VERSION ""

NS_ :

BS_:

BU_: SGW RFHM MPAD IPC GNMM EVCU2 ESL ECM DTCM DMSM BSM BCM AGSM ADCAM

BO_ 610 ADAS_FD_INFO2: 32 ADCAM
 SG_ TSRSts : 175|2@0+ (1,0) [0|3] "-"  EVCU2,SGW,IPC
 SG_ SignVehicleSpeedLimitConditional : 173|6@0+ (1,0) [0|63] "-"  IPC
 SG_ SignVehicleSpeedLimit : 165|6@0+ (1,0) [0|63] "-"  IPC
 SG_ SignSupplemVehicleSpeedLimit : 183|4@0+ (1,0) [0|15] "-"  IPC
 SG_ SignOvertaking : 155|2@0+ (1,0) [0|3] "-"  IPC
 SG_ AHBFault : 157|1@0+ (1,0) [0|1] ""  SGW,BCM
 SG_ AHB_ON : 158|1@0+ (1,0) [0|1] ""  BCM
 SG_ AHB_Blind : 156|1@0+ (1,0) [0|1] ""  BCM
 SG_ Speed_Sign_Shape : 153|2@0+ (1,0) [0|3] "-"  SGW,IPC
 SG_ SpdUnits_Cam : 159|1@0+ (1,0) [0|1] "-"  IPC
 SG_ SourceFusedSpeedLimit : 167|2@0+ (1,0) [0|3] "-"  IPC
 SG_ HAS_ValidRoad : 147|1@0+ (1,0) [0|1] "-"  Vector__XXX
 SG_ HAS_Status_DALM : 127|4@0+ (1,0) [0|3] "" BCM
 SG_ HAS_OpStat_Prim_DALM : 123|4@0+ (1,0) [0|5] "" BCM
 SG_ DALM_Request : 135|4@0+ (1,0) [0|14] "" BCM
 SG_ CADM_DALM_MC : 131|4@0+ (1,0) [0|15] "-"  BCM
 SG_ CADM_DALM_CRC : 143|8@0+ (1,0) [0|255] "-"  BCM
 SG_ Turn_Lever_Unlatch_Req : 7|2@0+ (1,0) [0|2] "-"  BCM
 SG_ SpeedArrows : 10|2@0+ (1,0) [0|3] "No_Unit"  IPC
 SG_ SignVehicleSpeedLimitPredictive : 23|5@0+ (1,0) [0|31] "No_Unit"  IPC
 SG_ MRRRR_Sts : 39|2@0+ (1,0) [0|2] "" SGW
 SG_ MRRRL_Sts : 25|2@0+ (1,0) [0|2] "" SGW
 SG_ MRRFR_Sts : 27|2@0+ (1,0) [0|2] "" SGW
 SG_ MRRFL_Sts : 29|2@0+ (1,0) [0|2] "" SGW
 SG_ LRRF_Sts : 31|2@0+ (1,0) [0|2] "" SGW
 SG_ LRCF_Sts : 18|2@0+ (1,0) [0|2] "" SGW
 SG_ DistanceSpeedLimitPredictive : 3|9@0+ (10,0) [0|5110] "meter"  IPC
 SG_ MessageCounter_ADAS_FD_INFO2 : 179|4@0+ (1,0) [0|15] "-"  EVCU2,SGW,BCM,IPC
 SG_ CRC_ADAS_FD_INFO2 : 191|8@0+ (1,0) [0|255] "-"  EVCU2,SGW,BCM,IPC
 SG_ DRV_Request : 43|4@0+ (1,0) [0|15] "" IPC
 SG_ Alg_DisplaySts : 146|3@0+ (1,0) [0|7] "" IPC

BO_ 1456 ADAS_FD_HMI: 32 ADCAM
 SG_ RR_Chime_RqSts : 99|1@0+ (1,0) [0|1] "" SGW,BCM
 SG_ MessageCounter_ADAS_FD_HMI : 179|4@0+ (1,0) [0|15] "-"  ADCAM,DMSM,BCM,BSM,IPC
 SG_ LR_Chime_RqSts : 100|1@0+ (1,0) [0|1] "" SGW,BCM
 SG_ CRC_ADAS_FD_HMI : 191|8@0+ (1,0) [0|255] "-"  ADCAM,DMSM,BCM,BSM,IPC
 SG_ Chime_Priority : 91|3@0+ (1,0) [0|4] "-"  SGW,BCM
 SG_ BSS_SRV_RQSts : 88|1@0+ (1,0) [0|1] "" SGW,BCM,IPC
 SG_ BSS_Blind_RQSts : 101|1@0+ (1,0) [0|1] "" SGW,BCM,IPC
 SG_ BSS_CFG_STATSts : 103|2@0+ (1,0) [0|2] "" IPC
 SG_ SVI_Request : 31|2@0+ (1,0) [0|3] "-"  SGW,IPC
 SG_ Set_Speed_MPH : 15|8@0+ (1,0) [0|255] "mph"  SGW,IPC
 SG_ Set_Speed_KPH : 7|8@0+ (1,0) [0|255] "kph"  SGW,IPC
 SG_ RF_Chime_RqSts : 95|1@0+ (1,0) [0|1] "-"  SGW,BCM
 SG_ PEB_Setting_Avail : 78|1@0+ (1,0) [0|1] "-"  Vector__XXX
 SG_ NCC_FailSts : 82|1@0+ (1,0) [0|1] "-"  Vector__XXX
 SG_ LKA_Status : 23|1@0+ (1,0) [0|1] "-"  SGW,IPC
 SG_ LKA_LEDControlSts : 57|2@0+ (1,0) [0|2] "-"  BCM
 SG_ LKA_FailSts : 84|1@0+ (1,0) [0|1] "-"  IPC
 SG_ LKA_Blind : 86|1@0+ (1,0) [0|1] "-"  IPC
 SG_ LF_Chime_RqSts : 93|1@0+ (1,0) [0|1] "-"  SGW,BCM
 SG_ Lane_DisplaySts_Right : 60|3@0+ (1,0) [0|7] "-"  SGW,IPC
 SG_ Lane_DisplaySts_Left : 71|3@0+ (1,0) [0|7] "-"  SGW,IPC
 SG_ ICA_Blind : 55|1@0+ (1,0) [0|1] "-"  IPC
 SG_ HAS_TurnSignalRequest : 111|2@0+ (1,0) [0|2] "" BCM
 SG_ HAS_TelltaleSts : 54|3@0+ (1,0) [0|6] "-"  SGW,IPC
 SG_ HAS_Hazard : 113|1@0+ (1,0) [0|1] "" BCM
 SG_ HAS_FailSts : 80|1@0+ (1,0) [0|1] "-"  IPC
 SG_ HAS_Escalation_Sts : 117|4@0+ (1,0) [0|8] "" Vector__XXX
 SG_ HAS_Blind : 85|1@0+ (1,0) [0|1] "-"  IPC
 SG_ FCW_Setting_Avail : 77|1@0+ (1,0) [0|1] "-"  IPC
 SG_ DMSM_Wakeup : 119|1@0+ (1,0) [0|1] "-"  DMSM
 SG_ DisplaySts_Veh : 63|3@0+ (1,0) [0|7] "-"  SGW,IPC
 SG_ DisplaySts_OFF : 68|3@0+ (1,0) [0|7] "-"  SGW,IPC
 SG_ DisplaySts_Curve : 109|2@0+ (1,0) [0|2] "" IPC
 SG_ DisplaySts_ACC : 51|4@0+ (1,0) [0|15] "-"  SGW,IPC
 SG_ DDD_FailSts : 96|1@0+ (1,0) [0|1] "" IPC
 SG_ DDD_DispPopupSts : 39|2@0+ (1,0) [0|2] "-"  IPC
 SG_ Chime_TypSts : 47|4@0+ (1,0) [0|15] "-"  SGW,BCM
 SG_ Chime_RepRate : 43|4@0+ (1,0) [0|15] "Hz"  SGW,BCM
 SG_ BlindSpotRightWarn : 171|2@0+ (1,0) [0|2] "" BCM
 SG_ BlindSpotLeftWarn : 105|2@0+ (1,0) [0|2] "" BCM
 SG_ AEB_Limited : 72|1@0+ (1,0) [0|1] "-"  IPC
 SG_ AEB_Limit_Fail : 74|1@0+ (1,0) [0|1] "-"  IPC
 SG_ AEB_FailSts : 83|1@0+ (1,0) [0|1] "-"  BSM,IPC
 SG_ AEB_DispPopupSts : 37|6@0+ (1,0) [0|63] "-"  SGW,IPC
 SG_ AEB_Blind : 76|1@0+ (1,0) [0|1] "-"  IPC
 SG_ ACC_Set_Speed_Strike : 92|1@0+ (1,0) [0|1] "-"  SGW,IPC
 SG_ ACC_Limited : 87|1@0+ (1,0) [0|1] "-"  IPC
 SG_ ACC_Limit_Fail : 73|1@0+ (1,0) [0|1] "-"  IPC
 SG_ ACC_FailSts : 81|1@0+ (1,0) [0|1] "-"  BCM,BSM,IPC
 SG_ ACC_DispPopupSts : 22|7@0+ (1,0) [0|127] "-"  SGW,IPC
 SG_ ACC_Blind : 75|1@0+ (1,0) [0|1] "-"  BSM,IPC
 SG_ Driver_Model : 107|2@0+ (1,0) [0|3] "" Vector__XXX
 SG_ RRCC_LEDSts : 25|2@0+ (1,0) [0|2] "-"  Vector__XXX
 SG_ HAS_Inhibit_HMI : 143|6@0+ (1,0) [0|63] "-"  IPC
 SG_ Lane_DispPopupSts : 127|8@0+ (1,0) [0|255] "-"  SGW,IPC
 SG_ RRCC_DispPopupSts : 149|6@0+ (1,0) [0|63] "-"  IPC
 SG_ SVI_Request_ext : 29|3@0+ (1,0) [0|7] "-"  IPC
 SG_ ADASDoorunlock_Request : 132|1@0+ (1,0) [0|1] "-"  BCM
 SG_ HAS_TelltaleSts_ext : 157|3@0+ (1,0) [0|7] "" IPC
 SG_ DisplaySts_Route : 154|3@0+ (1,0) [0|7] "" IPC
 SG_ SLA_Telltale_Sts : 167|2@0+ (1,0) [0|3] "" IPC

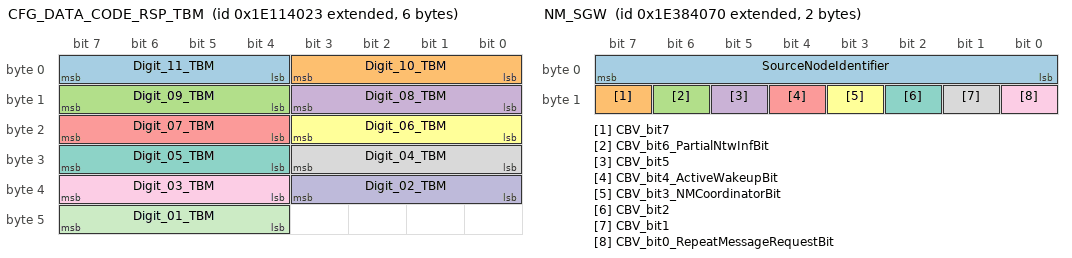
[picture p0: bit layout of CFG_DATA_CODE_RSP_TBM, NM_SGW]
BO_ 2651930659 CFG_DATA_CODE_RSP_TBM: 6 SGW
 SG_ Digit_11_TBM : 7|4@0+ (1,0) [0|15] "-"  BCM
 SG_ Digit_10_TBM : 3|4@0+ (1,0) [0|15] "-"  BCM
 SG_ Digit_09_TBM : 15|4@0+ (1,0) [0|15] "-"  BCM
 SG_ Digit_08_TBM : 11|4@0+ (1,0) [0|15] "-"  BCM
 SG_ Digit_07_TBM : 23|4@0+ (1,0) [0|15] "-"  BCM
 SG_ Digit_06_TBM : 19|4@0+ (1,0) [0|15] "-"  BCM
 SG_ Digit_05_TBM : 31|4@0+ (1,0) [0|15] "-"  BCM
 SG_ Digit_04_TBM : 27|4@0+ (1,0) [0|15] "-"  BCM
 SG_ Digit_03_TBM : 39|4@0+ (1,0) [0|15] "-"  BCM
 SG_ Digit_02_TBM : 35|4@0+ (1,0) [0|15] "-"  BCM
 SG_ Digit_01_TBM : 47|4@0+ (1,0) [0|15] "-"  BCM

BO_ 278 TRANSM_FD_1: 64 EVCU2
 SG_ TRANS_ADAS_Inhibit : 311|1@0+ (1,0) [0|1] "-"  BCM,BSM

BO_ 1452 TBM_SCHEDULE_FD_2: 32 SGW
 SG_ U_Call_Stat_TBM : 143|3@0+ (1,0) [0|7] "-"  BCM
 SG_ E_Call_Stat_TBM : 130|3@0+ (1,0) [0|7] "-"  BCM
 SG_ PrivacyMode : 134|1@0+ (1,0) [0|1] "-"  MPAD
 SG_ WiFiSts : 154|2@0+ (1,0) [0|3] "-"  MPAD
 SG_ SignalStrength : 159|3@0+ (1,0) [0|7] "-"  MPAD
 SG_ NetConnection : 163|2@0+ (1,0) [0|3] "-"  MPAD
 SG_ LTESts : 147|3@0+ (1,0) [0|7] "-"  MPAD
 SG_ MessageCounter_TBMS2 : 179|4@0+ (1,0) [0|15] "-"  MPAD,BCM
 SG_ CRC_TBMS2 : 191|8@0+ (1,0) [0|255] "-"  MPAD,BCM

BO_ 2654486640 NM_SGW: 2 SGW
 SG_ SourceNodeIdentifier : 7|8@0+ (1,0) [0|255] "-"  ADCAM,MPAD,EVCU2,GNMM,AGSM,ESL,BCM,BSM,IPC,RFHM,ECM,DTCM
 SG_ CBV_bit7 : 15|1@0+ (1,0) [0|1] "" ADCAM,MPAD,EVCU2,GNMM,AGSM,ESL,BCM,BSM,IPC,RFHM,ECM,DTCM
 SG_ CBV_bit6_PartialNtwInfBit : 14|1@0+ (1,0) [0|1] "" ADCAM,MPAD,EVCU2,GNMM,AGSM,ESL,BCM,BSM,IPC,RFHM,ECM,DTCM
 SG_ CBV_bit5 : 13|1@0+ (1,0) [0|1] "" ADCAM,MPAD,EVCU2,GNMM,AGSM,ESL,BCM,BSM,IPC,RFHM,ECM,DTCM
 SG_ CBV_bit4_ActiveWakeupBit : 12|1@0+ (1,0) [0|1] "" ADCAM,MPAD,EVCU2,GNMM,AGSM,ESL,BCM,BSM,IPC,RFHM,ECM,DTCM
 SG_ CBV_bit3_NMCoordinatorBit : 11|1@0+ (1,0) [0|1] "" ADCAM,MPAD,EVCU2,GNMM,AGSM,ESL,BCM,BSM,IPC,RFHM,ECM,DTCM
 SG_ CBV_bit2 : 10|1@0+ (1,0) [0|1] "" ADCAM,MPAD,EVCU2,GNMM,AGSM,ESL,BCM,BSM,IPC,RFHM,ECM,DTCM
 SG_ CBV_bit1 : 9|1@0+ (1,0) [0|1] "" ADCAM,MPAD,EVCU2,GNMM,AGSM,ESL,BCM,BSM,IPC,RFHM,ECM,DTCM
 SG_ CBV_bit0_RepeatMessageRequestBit : 8|1@0+ (1,0) [0|1] "" ADCAM,MPAD,EVCU2,GNMM,AGSM,ESL,BCM,BSM,IPC,RFHM,ECM,DTCM

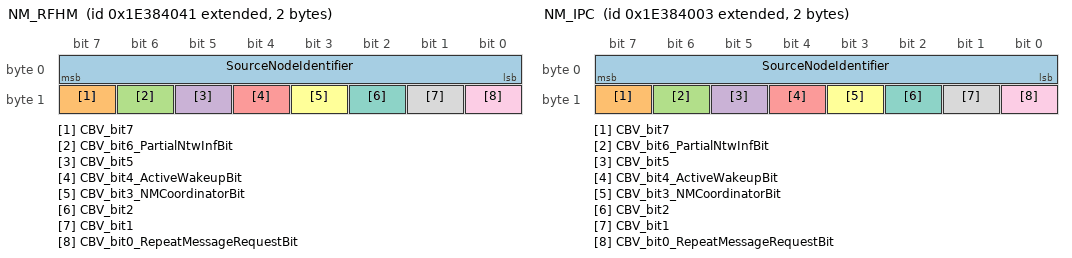
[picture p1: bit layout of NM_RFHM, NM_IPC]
BO_ 2654486593 NM_RFHM: 2 RFHM
 SG_ SourceNodeIdentifier : 7|8@0+ (1,0) [0|255] "-"  ADCAM,MPAD,EVCU2,GNMM,SGW,AGSM,ESL,BCM,BSM,IPC,ECM,DTCM
 SG_ CBV_bit7 : 15|1@0+ (1,0) [0|1] "" ADCAM,MPAD,EVCU2,GNMM,SGW,AGSM,ESL,BCM,BSM,IPC,ECM,DTCM
 SG_ CBV_bit6_PartialNtwInfBit : 14|1@0+ (1,0) [0|1] "" ADCAM,MPAD,EVCU2,GNMM,SGW,AGSM,ESL,BCM,BSM,IPC,ECM,DTCM
 SG_ CBV_bit5 : 13|1@0+ (1,0) [0|1] "" ADCAM,MPAD,EVCU2,GNMM,SGW,AGSM,ESL,BCM,BSM,IPC,ECM,DTCM
 SG_ CBV_bit4_ActiveWakeupBit : 12|1@0+ (1,0) [0|1] "" ADCAM,MPAD,EVCU2,GNMM,SGW,AGSM,ESL,BCM,BSM,IPC,ECM,DTCM
 SG_ CBV_bit3_NMCoordinatorBit : 11|1@0+ (1,0) [0|1] "" ADCAM,MPAD,EVCU2,GNMM,SGW,AGSM,ESL,BCM,BSM,IPC,ECM,DTCM
 SG_ CBV_bit2 : 10|1@0+ (1,0) [0|1] "" ADCAM,MPAD,EVCU2,GNMM,SGW,AGSM,ESL,BCM,BSM,IPC,ECM,DTCM
 SG_ CBV_bit1 : 9|1@0+ (1,0) [0|1] "" ADCAM,MPAD,EVCU2,GNMM,SGW,AGSM,ESL,BCM,BSM,IPC,ECM,DTCM
 SG_ CBV_bit0_RepeatMessageRequestBit : 8|1@0+ (1,0) [0|1] "" ADCAM,MPAD,EVCU2,GNMM,SGW,AGSM,ESL,BCM,BSM,IPC,ECM,DTCM

BO_ 2654486531 NM_IPC: 2 IPC
 SG_ SourceNodeIdentifier : 7|8@0+ (1,0) [0|255] "-"  ADCAM,MPAD,EVCU2,GNMM,SGW,AGSM,ESL,BCM,BSM,RFHM,ECM,DTCM
 SG_ CBV_bit7 : 15|1@0+ (1,0) [0|1] "" ADCAM,MPAD,EVCU2,GNMM,SGW,AGSM,ESL,BCM,BSM,RFHM,ECM,DTCM
 SG_ CBV_bit6_PartialNtwInfBit : 14|1@0+ (1,0) [0|1] "" ADCAM,MPAD,EVCU2,GNMM,SGW,AGSM,ESL,BCM,BSM,RFHM,ECM,DTCM
 SG_ CBV_bit5 : 13|1@0+ (1,0) [0|1] "" ADCAM,MPAD,EVCU2,GNMM,SGW,AGSM,ESL,BCM,BSM,RFHM,ECM,DTCM
 SG_ CBV_bit4_ActiveWakeupBit : 12|1@0+ (1,0) [0|1] "" ADCAM,MPAD,EVCU2,GNMM,SGW,AGSM,ESL,BCM,BSM,RFHM,ECM,DTCM
 SG_ CBV_bit3_NMCoordinatorBit : 11|1@0+ (1,0) [0|1] "" ADCAM,MPAD,EVCU2,GNMM,SGW,AGSM,ESL,BCM,BSM,RFHM,ECM,DTCM
 SG_ CBV_bit2 : 10|1@0+ (1,0) [0|1] "" ADCAM,MPAD,EVCU2,GNMM,SGW,AGSM,ESL,BCM,BSM,RFHM,ECM,DTCM
 SG_ CBV_bit1 : 9|1@0+ (1,0) [0|1] "" ADCAM,MPAD,EVCU2,GNMM,SGW,AGSM,ESL,BCM,BSM,RFHM,ECM,DTCM
 SG_ CBV_bit0_RepeatMessageRequestBit : 8|1@0+ (1,0) [0|1] "" ADCAM,MPAD,EVCU2,GNMM,SGW,AGSM,ESL,BCM,BSM,RFHM,ECM,DTCM

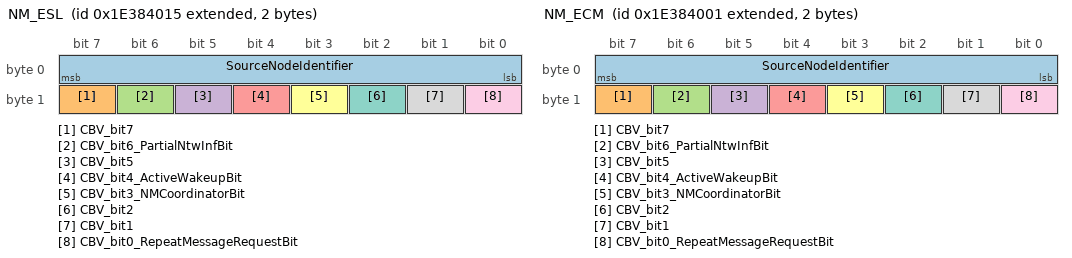
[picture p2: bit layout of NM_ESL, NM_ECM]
BO_ 2654486549 NM_ESL: 2 ESL
 SG_ SourceNodeIdentifier : 7|8@0+ (1,0) [0|255] "-"  ADCAM,MPAD,EVCU2,GNMM,SGW,AGSM,BCM,BSM,IPC,RFHM,ECM,DTCM
 SG_ CBV_bit7 : 15|1@0+ (1,0) [0|1] "" ADCAM,MPAD,EVCU2,GNMM,SGW,AGSM,BCM,BSM,IPC,RFHM,ECM,DTCM
 SG_ CBV_bit6_PartialNtwInfBit : 14|1@0+ (1,0) [0|1] "" ADCAM,MPAD,EVCU2,GNMM,SGW,AGSM,BCM,BSM,IPC,RFHM,ECM,DTCM
 SG_ CBV_bit5 : 13|1@0+ (1,0) [0|1] "" ADCAM,MPAD,EVCU2,GNMM,SGW,AGSM,BCM,BSM,IPC,RFHM,ECM,DTCM
 SG_ CBV_bit4_ActiveWakeupBit : 12|1@0+ (1,0) [0|1] "" ADCAM,MPAD,EVCU2,GNMM,SGW,AGSM,BCM,BSM,IPC,RFHM,ECM,DTCM
 SG_ CBV_bit3_NMCoordinatorBit : 11|1@0+ (1,0) [0|1] "" ADCAM,MPAD,EVCU2,GNMM,SGW,AGSM,BCM,BSM,IPC,RFHM,ECM,DTCM
 SG_ CBV_bit2 : 10|1@0+ (1,0) [0|1] "" ADCAM,MPAD,EVCU2,GNMM,SGW,AGSM,BCM,BSM,IPC,RFHM,ECM,DTCM
 SG_ CBV_bit1 : 9|1@0+ (1,0) [0|1] "" ADCAM,MPAD,EVCU2,GNMM,SGW,AGSM,BCM,BSM,IPC,RFHM,ECM,DTCM
 SG_ CBV_bit0_RepeatMessageRequestBit : 8|1@0+ (1,0) [0|1] "" ADCAM,MPAD,EVCU2,GNMM,SGW,AGSM,BCM,BSM,IPC,RFHM,ECM,DTCM

BO_ 2654486529 NM_ECM: 2 ECM
 SG_ SourceNodeIdentifier : 7|8@0+ (1,0) [0|255] "-"  ADCAM,MPAD,EVCU2,GNMM,SGW,AGSM,ESL,BCM,BSM,IPC,RFHM,DTCM
 SG_ CBV_bit7 : 15|1@0+ (1,0) [0|1] "" ADCAM,MPAD,EVCU2,GNMM,SGW,AGSM,ESL,BCM,BSM,IPC,RFHM,DTCM
 SG_ CBV_bit6_PartialNtwInfBit : 14|1@0+ (1,0) [0|1] "" ADCAM,MPAD,EVCU2,GNMM,SGW,AGSM,ESL,BCM,BSM,IPC,RFHM,DTCM
 SG_ CBV_bit5 : 13|1@0+ (1,0) [0|1] "" ADCAM,MPAD,EVCU2,GNMM,SGW,AGSM,ESL,BCM,BSM,IPC,RFHM,DTCM
 SG_ CBV_bit4_ActiveWakeupBit : 12|1@0+ (1,0) [0|1] "" ADCAM,MPAD,EVCU2,GNMM,SGW,AGSM,ESL,BCM,BSM,IPC,RFHM,DTCM
 SG_ CBV_bit3_NMCoordinatorBit : 11|1@0+ (1,0) [0|1] "" ADCAM,MPAD,EVCU2,GNMM,SGW,AGSM,ESL,BCM,BSM,IPC,RFHM,DTCM
 SG_ CBV_bit2 : 10|1@0+ (1,0) [0|1] "" ADCAM,MPAD,EVCU2,GNMM,SGW,AGSM,ESL,BCM,BSM,IPC,RFHM,DTCM
 SG_ CBV_bit1 : 9|1@0+ (1,0) [0|1] "" ADCAM,MPAD,EVCU2,GNMM,SGW,AGSM,ESL,BCM,BSM,IPC,RFHM,DTCM
 SG_ CBV_bit0_RepeatMessageRequestBit : 8|1@0+ (1,0) [0|1] "" ADCAM,MPAD,EVCU2,GNMM,SGW,AGSM,ESL,BCM,BSM,IPC,RFHM,DTCM

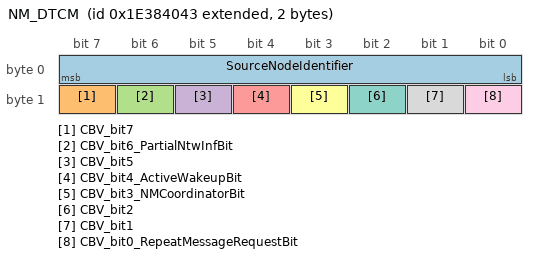
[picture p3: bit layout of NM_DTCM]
BO_ 2654486595 NM_DTCM: 2 DTCM
 SG_ SourceNodeIdentifier : 7|8@0+ (1,0) [0|255] "-"  ADCAM,MPAD,EVCU2,GNMM,SGW,AGSM,ESL,BCM,BSM,IPC,RFHM,ECM
 SG_ CBV_bit7 : 15|1@0+ (1,0) [0|1] "" ADCAM,MPAD,EVCU2,GNMM,SGW,AGSM,ESL,BCM,BSM,IPC,RFHM,ECM
 SG_ CBV_bit6_PartialNtwInfBit : 14|1@0+ (1,0) [0|1] "" ADCAM,MPAD,EVCU2,GNMM,SGW,AGSM,ESL,BCM,BSM,IPC,RFHM,ECM
 SG_ CBV_bit5 : 13|1@0+ (1,0) [0|1] "" ADCAM,MPAD,EVCU2,GNMM,SGW,AGSM,ESL,BCM,BSM,IPC,RFHM,ECM
 SG_ CBV_bit4_ActiveWakeupBit : 12|1@0+ (1,0) [0|1] "" ADCAM,MPAD,EVCU2,GNMM,SGW,AGSM,ESL,BCM,BSM,IPC,RFHM,ECM
 SG_ CBV_bit3_NMCoordinatorBit : 11|1@0+ (1,0) [0|1] "" ADCAM,MPAD,EVCU2,GNMM,SGW,AGSM,ESL,BCM,BSM,IPC,RFHM,ECM
 SG_ CBV_bit2 : 10|1@0+ (1,0) [0|1] "" ADCAM,MPAD,EVCU2,GNMM,SGW,AGSM,ESL,BCM,BSM,IPC,RFHM,ECM
 SG_ CBV_bit1 : 9|1@0+ (1,0) [0|1] "" ADCAM,MPAD,EVCU2,GNMM,SGW,AGSM,ESL,BCM,BSM,IPC,RFHM,ECM
 SG_ CBV_bit0_RepeatMessageRequestBit : 8|1@0+ (1,0) [0|1] "" ADCAM,MPAD,EVCU2,GNMM,SGW,AGSM,ESL,BCM,BSM,IPC,RFHM,ECM

BO_TX_BU_ 610 : ADCAM,MPAD;
BO_TX_BU_ 1456 : ADCAM,MPAD;
CM_ SG_ 610 CADM_DALM_MC "This signal is a counter used for safety checks strategies. This counter is incremented of 1 (one) unit at each frame transmission.";
CM_ SG_ 610 MRRRL_Sts "Mid Range Radar Rear Left Sensor Status";
CM_ SG_ 610 MRRRR_Sts "Mid Range Radar Rear Right Sensor Status";
CM_ SG_ 610 SignOvertaking "This signal indicates the road sign of no overtaking";
CM_ SG_ 610 SignSupplemVehicleSpeedLimit "This signal indicates the supplementary road sign  related to vehicle speed limit";
CM_ SG_ 610 SignVehicleSpeedLimit "This signal indicates the road sign of vehicle speed limit";
CM_ SG_ 610 SignVehicleSpeedLimitConditional "This signal indicates the conditional road sign of vehicle speed limit";
CM_ SG_ 610 SignVehicleSpeedLimitPredictive "This signal indicates the predictive vehicle sign speed limit.";
CM_ SG_ 610 SourceFusedSpeedLimit "Source of the fused speed limit data";
CM_ SG_ 610 HAS_OpStat_Prim_DALM "Capability of the primary controller to perform sensing, computing, and actuation";
CM_ SG_ 610 HAS_Status_DALM "Highway Assist System Status as reported by the main controller";
CM_ SG_ 610 HAS_ValidRoad "HAS Ready";
CM_ SG_ 610 LRCF_Sts "Long Range Camera Front Sensor Status";
CM_ SG_ 610 MRRFL_Sts "Mid Range Radar Front Left Sensor Status";
CM_ SG_ 610 MRRFR_Sts "Mid Range Radar Front Right Sensor Status";
CM_ SG_ 610 MessageCounter_ADAS_FD_INFO2 "This signal is a counter used for safety checks strategies. This counter is incremented of 1 (one) unit at each frame transmission.";
CM_ SG_ 610 LRRF_Sts "Long Range Radar Front Sensor Status";
CM_ SG_ 610 SpeedArrows "Arrow to indicate speed limit variation.";
CM_ SG_ 610 AHB_Blind "This signal indicates the AHB Controller state";
CM_ SG_ 610 AHB_ON "AHB Controller tells to the BCM to turn ON/OFF the high beam lamps";
CM_ SG_ 610 AHBFault "AHB Controller sends to the BCM the fault condition";
CM_ SG_ 610 Alg_DisplaySts "'Alg_DisplaySts.TEXT MSG n corresponds to a raw value of 'n'";
CM_ SG_ 610 CADM_DALM_CRC "CRC according to SAE J1850 standard at each frame transmission.";
CM_ SG_ 610 CRC_ADAS_FD_INFO2 "CRC according to SAE J1850 standard at each frame transmission.";
CM_ SG_ 610 DALM_Request "Request to driver alert lighting modules to trigger patttern and color display from primary controller";
CM_ SG_ 610 DistanceSpeedLimitPredictive "Distance to next speed limit (predictive speed limit).";
CM_ SG_ 610 DRV_Request "DRV_Request.TEXT MSG n corresponds to a raw value of 'n";
CM_ SG_ 610 SpdUnits_Cam "Speed Units";
CM_ SG_ 610 Speed_Sign_Shape "Shape of Speed Sign";
CM_ SG_ 610 TSRSts "This signal indicates the Traffic Sign Recognition status";
CM_ SG_ 610 Turn_Lever_Unlatch_Req "L2+ turn stalk unlatch request";
CM_ SG_ 1456 Lane_DispPopupSts "Lane Management Pop-up Messages.TEXT MSG n corresponds to a raw value of 'n'";
CM_ SG_ 1456 LF_Chime_RqSts "DASM_LF_Chime_RqSts";
CM_ SG_ 1456 LKA_Blind "LKA_Blind";
CM_ SG_ 1456 LKA_FailSts "LKA_FailSts";
CM_ SG_ 1456 Lane_DisplaySts_Left "Lane Display Status Left";
CM_ SG_ 1456 Lane_DisplaySts_Right "Lane Display Status Right";
CM_ SG_ 1456 ICA_Blind "This signal is used to indicate the presence of an occlusion of the ICA feature";
CM_ SG_ 1456 HAS_TurnSignalRequest "Request from the primary controller to actuate the turn signals";
CM_ SG_ 1456 NCC_FailSts "NCC_FailSts";
CM_ SG_ 1456 PEB_Setting_Avail "PEB setting availability";
CM_ SG_ 1456 RF_Chime_RqSts "DASM_RF_Chime_RqSts";
CM_ SG_ 1456 RR_Chime_RqSts "BSM right rear chime on request";
CM_ SG_ 1456 LKA_LEDControlSts "Lane Keep LED Control Status";
CM_ SG_ 1456 LKA_Status "None";
CM_ SG_ 1456 LR_Chime_RqSts "BSM Left rear chime on request";
CM_ SG_ 1456 MessageCounter_ADAS_FD_HMI "This signal is a counter used for safety checks strategies. This counter is incremented of 1 (one) unit at each frame transmission.";
CM_ SG_ 1456 SLA_Telltale_Sts "'SLA_Telltale_Sts.TEXT MSG n corresponds to a raw value of 'n'";
CM_ SG_ 1456 SVI_Request "Request to activate Secondary Visual Indication";
CM_ SG_ 1456 SVI_Request_ext "Cluster Glow";
CM_ SG_ 1456 ACC_Blind "ACC_Blind";
CM_ SG_ 1456 ACC_DispPopupSts "ACC Dips Pop Up";
CM_ SG_ 1456 ACC_FailSts "ACC_FailSts";
CM_ SG_ 1456 BSS_Blind_RQSts "Sensor blinded request from BSS";
CM_ SG_ 1456 ACC_Limit_Fail "ACC_Limit_Fail";
CM_ SG_ 1456 ACC_Limited "ACC_Limited";
CM_ SG_ 1456 ACC_Set_Speed_Strike "ACC Set Speed Strike";
CM_ SG_ 1456 ADASDoorunlock_Request "Request from Primary MPAD to unlock all the doors";
CM_ SG_ 1456 AEB_Blind "AEB_Blind";
CM_ SG_ 1456 AEB_DispPopupSts "AEB Dips Pop Up";
CM_ SG_ 1456 AEB_FailSts "AEB_FailSts";
CM_ SG_ 1456 AEB_Limit_Fail "AEB_Limit_Fail";
CM_ SG_ 1456 AEB_Limited "AEB_Limited";
CM_ SG_ 1456 BlindSpotLeftWarn "BlindSpotLeftWarn";
CM_ SG_ 1456 BlindSpotRightWarn "BlindSpotRightWarn";
CM_ SG_ 1456 BSS_CFG_STATSts "Blind Spot configuration status";
CM_ SG_ 1456 BSS_SRV_RQSts "BSS service warning request";
CM_ SG_ 1456 CRC_ADAS_FD_HMI "CRC according to SAE J1850 standard at each frame transmission.";
CM_ SG_ 1456 Chime_Priority "Chime Priority";
CM_ SG_ 1456 Chime_RepRate "DASM Chime Repetition Rate";
CM_ SG_ 1456 Chime_TypSts "DASM Chime Type Status";
CM_ SG_ 1456 DDD_DispPopupSts "DDD Disp Pop Up";
CM_ SG_ 1456 DDD_FailSts "DDD Fail Sts CADM2";
CM_ SG_ 1456 DisplaySts_ACC "Display status ACC";
CM_ SG_ 1456 DisplaySts_Curve "Indication that Curve Speed Control is reducing vehicle target speed in response to tight curve";
CM_ SG_ 1456 DisplaySts_OFF "Display Status Off";
CM_ SG_ 1456 DisplaySts_Route "'DisplaySts_Route.TEXT MSG n corresponds to a raw value of 'n'";
CM_ SG_ 1456 DisplaySts_Veh "Display Status Veh";
CM_ SG_ 1456 DMSM_Wakeup "To trigger driver monitoring camera and IR LED to turn on";
CM_ SG_ 1456 Driver_Model "Overall assessment of whether driver is attentive to the driving task according to driver model";
CM_ SG_ 1456 FCW_Setting_Avail "FCW setting availability";
CM_ SG_ 1456 HAS_Blind "HAS_Blind";
CM_ SG_ 1456 HAS_Escalation_Sts "HAS_Escalation_Sts";
CM_ SG_ 1456 HAS_FailSts "HAS_FailSts";
CM_ SG_ 1456 HAS_Hazard "Request from the primary controller to actuate the Hazard lamps.";
CM_ SG_ 1456 HAS_Inhibit_HMI "L2+ inhibiting reason message";
CM_ SG_ 1456 HAS_TelltaleSts "Highway Assist telltale status in cluster";
CM_ SG_ 1456 HAS_TelltaleSts_ext "'HAS_TelltaleSts_ext .TEXT MSG n corresponds to a raw value of 'n'";
CM_ SG_ 1456 RRCC_DispPopupSts "RRCC_DispPopupSts";
CM_ SG_ 1456 RRCC_LEDSts "RRCC_LEDSts";
CM_ SG_ 1456 Set_Speed_KPH "Speed shown by IPC, which ACC is controlling in KPH";
CM_ SG_ 1456 Set_Speed_MPH "Speed shown by IPC, which ACC is controlling in MPH";
CM_ SG_ 278 TRANS_ADAS_Inhibit "TCM's ability to accept external gear shift requests";
CM_ SG_ 1452 LTESts "It is used to show the cell network level";
CM_ SG_ 1452 E_Call_Stat_TBM "E-Call Status";
CM_ SG_ 1452 CRC_TBMS2 "CRC according to SAE J1850 standard at each frame transmission.";
CM_ SG_ 1452 MessageCounter_TBMS2 "This signal is a counter used for safety checks strategies. This counter is incremented of 1 (one) unit at each frame transmission.";
CM_ SG_ 1452 PrivacyMode "It is used to give information about  the Privacy Mode functionality.";
CM_ SG_ 1452 NetConnection "It is used to estimate data connection";
CM_ SG_ 1452 WiFiSts "It indicates the status of the WiFi modem";
CM_ SG_ 1452 U_Call_Stat_TBM "U-Call Status";
CM_ SG_ 1452 SignalStrength "It is used to show the cell signal strength";
CM_ SG_ 2654486640 CBV_bit0_RepeatMessageRequestBit "Repeat Message Request Bit";
CM_ SG_ 2654486640 CBV_bit3_NMCoordinatorBit "NM Coordinator Sleep Bit";
CM_ SG_ 2654486640 CBV_bit4_ActiveWakeupBit "Active Wakeup Bit";
CM_ SG_ 2654486640 CBV_bit6_PartialNtwInfBit "Partial Network Information Bit (PNI)";
CM_ SG_ 2654486640 SourceNodeIdentifier "Source Node Identifier";
CM_ SG_ 2654486593 CBV_bit0_RepeatMessageRequestBit "Repeat Message Request Bit";
CM_ SG_ 2654486593 CBV_bit3_NMCoordinatorBit "NM Coordinator Sleep Bit";
CM_ SG_ 2654486593 CBV_bit4_ActiveWakeupBit "Active Wakeup Bit";
CM_ SG_ 2654486593 CBV_bit6_PartialNtwInfBit "Partial Network Information Bit (PNI)";
CM_ SG_ 2654486593 SourceNodeIdentifier "Source Node Identifier";
CM_ SG_ 2654486531 CBV_bit0_RepeatMessageRequestBit "Repeat Message Request Bit";
CM_ SG_ 2654486531 CBV_bit3_NMCoordinatorBit "NM Coordinator Sleep Bit";
CM_ SG_ 2654486531 CBV_bit4_ActiveWakeupBit "Active Wakeup Bit";
CM_ SG_ 2654486531 CBV_bit6_PartialNtwInfBit "Partial Network Information Bit (PNI)";
CM_ SG_ 2654486531 SourceNodeIdentifier "Source Node Identifier";
CM_ SG_ 2654486549 CBV_bit0_RepeatMessageRequestBit "Repeat Message Request Bit";
CM_ SG_ 2654486549 CBV_bit3_NMCoordinatorBit "NM Coordinator Sleep Bit";
CM_ SG_ 2654486549 CBV_bit4_ActiveWakeupBit "Active Wakeup Bit";
CM_ SG_ 2654486549 CBV_bit6_PartialNtwInfBit "Partial Network Information Bit (PNI)";
CM_ SG_ 2654486549 SourceNodeIdentifier "Source Node Identifier";
CM_ SG_ 2654486529 CBV_bit3_NMCoordinatorBit "NM Coordinator Sleep Bit";
CM_ SG_ 2654486529 CBV_bit4_ActiveWakeupBit "Active Wakeup Bit";
CM_ SG_ 2654486529 CBV_bit6_PartialNtwInfBit "Partial Network Information Bit (PNI)";
CM_ SG_ 2654486529 SourceNodeIdentifier "Source Node Identifier";
CM_ SG_ 2654486529 CBV_bit0_RepeatMessageRequestBit "Repeat Message Request Bit";
CM_ SG_ 2654486595 SourceNodeIdentifier "Source Node Identifier";
CM_ SG_ 2654486595 CBV_bit0_RepeatMessageRequestBit "Repeat Message Request Bit";
CM_ SG_ 2654486595 CBV_bit3_NMCoordinatorBit "NM Coordinator Sleep Bit";
CM_ SG_ 2654486595 CBV_bit4_ActiveWakeupBit "Active Wakeup Bit";
CM_ SG_ 2654486595 CBV_bit6_PartialNtwInfBit "Partial Network Information Bit (PNI)";
BA_DEF_ BO_ "CANFD_BRS" ENUM "0","1";
BA_DEF_ BO_ "VFrameFormat" ENUM "StandardCAN","ExtendedCAN","reserved","reserved","reserved","reserved","reserved","reserved","reserved","reserved","reserved","reserved","reserved","reserved","StandardCAN_FD","ExtendedCAN_FD";
BA_DEF_ BO_ "DiagConnection" HEX 0 65535;
BA_DEF_ BO_ "DiagState" ENUM "No","Yes";
BA_DEF_ BO_ "NmAsrMessage" ENUM "No","Yes";
BA_DEF_ BO_ "GenMsgDelayTime" INT 0 65535;
BA_DEF_ BO_ "GenMsgCycleTime" INT 0 65535;
BA_DEF_ BO_ "GenMsgCycleTimeFast" INT 0 65535;
BA_DEF_ BO_ "GenMsgStartDelayTime" INT 0 65535;
BA_DEF_ BO_ "GenMsgILSupport" ENUM "No","Yes";
BA_DEF_ BO_ "GenMsgNrOfRepetition" INT 0 255;
BA_DEF_ BO_ "GenMsgSendType" ENUM "Cyclic","NotUsed","NotUsed","NotUsed","NotUsed","NotUsed","NotUsed","NotUsed","NoMsgSendType";
BA_DEF_ BO_ "NmMessage" ENUM "No","Yes";
BA_DEF_ BO_ "DiagResponse" ENUM "No","Yes";
BA_DEF_ BO_ "Type" ENUM "P","C","PE","COC","PE_Cntrl","E","E_Cntrl","OC","S","BAF","DC","EM","MM","ISO-TP","-";
BA_DEF_ BO_ "DiagRequest" ENUM "No","Yes";
BA_DEF_ SG_ "GenSigTimeoutTime_SGW" INT 0 65535;
BA_DEF_ SG_ "GenSigTimeoutTime_RFHM" INT 0 65535;
BA_DEF_ SG_ "GenSigTimeoutTime_MPAD" INT 0 65535;
BA_DEF_ SG_ "GenSigTimeoutTime_IPC" INT 0 65535;
BA_DEF_ SG_ "GenSigTimeoutTime_GNMM" INT 0 65535;
BA_DEF_ SG_ "GenSigTimeoutTime_EVCU2" INT 0 65535;
BA_DEF_ SG_ "GenSigTimeoutTime_ESL" INT 0 65535;
BA_DEF_ SG_ "GenSigTimeoutTime_ECM" INT 0 65535;
BA_DEF_ SG_ "GenSigTimeoutTime_DTCM" INT 0 65535;
BA_DEF_ SG_ "GenSigTimeoutTime_DMSM" INT 0 65535;
BA_DEF_ SG_ "GenSigTimeoutTime_BSM" INT 0 65535;
BA_DEF_ SG_ "GenSigTimeoutTime_BCM" INT 0 65535;
BA_DEF_ SG_ "GenSigTimeoutTime_AGSM" INT 0 65535;
BA_DEF_ SG_ "GenSigTimeoutTime_ADCAM" INT 0 65535;
BA_DEF_ SG_ "SystemSignalLongSymbol" STRING ;
BA_DEF_ SG_ "GenSigSendType" ENUM "NotUsed","OnWrite","OnWriteWithRepetition","OnChange","OnChangeWithRepetition","IfActive","IfActiveWithRepetition","NoSigSendType";
BA_DEF_ SG_ "GenSigInactiveValue" INT 0 2147483647;
BA_DEF_ SG_ "GenSigStartValue" INT 0 2147483647;
BA_DEF_DEF_ "CANFD_BRS" "0";
BA_DEF_DEF_ "VFrameFormat" "StandardCAN_FD";
BA_DEF_DEF_ "DiagConnection" 0;
BA_DEF_DEF_ "DiagState" "No";
BA_DEF_DEF_ "NmAsrMessage" "No";
BA_DEF_DEF_ "GenMsgDelayTime" 0;
BA_DEF_DEF_ "GenMsgCycleTime" 0;
BA_DEF_DEF_ "GenMsgCycleTimeFast" 0;
BA_DEF_DEF_ "GenMsgStartDelayTime" 0;
BA_DEF_DEF_ "GenMsgILSupport" "No";
BA_DEF_DEF_ "GenMsgNrOfRepetition" 0;
BA_DEF_DEF_ "GenMsgSendType" "NoMsgSendType";
BA_DEF_DEF_ "NmMessage" "No";
BA_DEF_DEF_ "DiagResponse" "No";
BA_DEF_DEF_ "Type" "-";
BA_DEF_DEF_ "DiagRequest" "No";
BA_DEF_DEF_ "GenSigTimeoutTime_SGW" 2500;
BA_DEF_DEF_ "GenSigTimeoutTime_RFHM" 2500;
BA_DEF_DEF_ "GenSigTimeoutTime_MPAD" 2500;
BA_DEF_DEF_ "GenSigTimeoutTime_IPC" 2500;
BA_DEF_DEF_ "GenSigTimeoutTime_GNMM" 2500;
BA_DEF_DEF_ "GenSigTimeoutTime_EVCU2" 2500;
BA_DEF_DEF_ "GenSigTimeoutTime_ESL" 2500;
BA_DEF_DEF_ "GenSigTimeoutTime_ECM" 2500;
BA_DEF_DEF_ "GenSigTimeoutTime_DTCM" 2500;
BA_DEF_DEF_ "GenSigTimeoutTime_DMSM" 2500;
BA_DEF_DEF_ "GenSigTimeoutTime_BSM" 2500;
BA_DEF_DEF_ "GenSigTimeoutTime_BCM" 2500;
BA_DEF_DEF_ "GenSigTimeoutTime_AGSM" 2500;
BA_DEF_DEF_ "GenSigTimeoutTime_ADCAM" 2500;
BA_DEF_DEF_ "SystemSignalLongSymbol" "";
BA_DEF_DEF_ "GenSigSendType" "NoSigSendType";
BA_DEF_DEF_ "GenSigInactiveValue" 0;
BA_DEF_DEF_ "GenSigStartValue" 0;
BA_ "CANFD_BRS" BO_ 610 1;
BA_ "GenMsgDelayTime" BO_ 610 20;
BA_ "GenMsgCycleTime" BO_ 610 100;
BA_ "GenMsgCycleTimeFast" BO_ 610 20;
BA_ "GenMsgILSupport" BO_ 610 1;
BA_ "GenMsgNrOfRepetition" BO_ 610 2;
BA_ "GenMsgSendType" BO_ 610 0;
BA_ "Type" BO_ 610 3;
BA_ "CANFD_BRS" BO_ 1456 1;
BA_ "GenMsgDelayTime" BO_ 1456 20;
BA_ "GenMsgCycleTime" BO_ 1456 100;
BA_ "GenMsgILSupport" BO_ 1456 1;
BA_ "GenMsgSendType" BO_ 1456 0;
BA_ "Type" BO_ 1456 3;
BA_ "CANFD_BRS" BO_ 2651930659 1;
BA_ "VFrameFormat" BO_ 2651930659 15;
BA_ "GenMsgILSupport" BO_ 2651930659 1;
BA_ "Type" BO_ 2651930659 11;
BA_ "CANFD_BRS" BO_ 278 1;
BA_ "GenMsgCycleTime" BO_ 278 10;
BA_ "GenMsgStartDelayTime" BO_ 278 5;
BA_ "GenMsgILSupport" BO_ 278 1;
BA_ "GenMsgSendType" BO_ 278 0;
BA_ "Type" BO_ 278 1;
BA_ "CANFD_BRS" BO_ 1452 1;
BA_ "GenMsgCycleTime" BO_ 1452 1000;
BA_ "GenMsgILSupport" BO_ 1452 1;
BA_ "GenMsgSendType" BO_ 1452 0;
BA_ "Type" BO_ 1452 3;
BA_ "CANFD_BRS" BO_ 2654486640 1;
BA_ "VFrameFormat" BO_ 2654486640 15;
BA_ "NmAsrMessage" BO_ 2654486640 1;
BA_ "NmMessage" BO_ 2654486640 1;
BA_ "Type" BO_ 2654486640 8;
BA_ "CANFD_BRS" BO_ 2654486593 1;
BA_ "VFrameFormat" BO_ 2654486593 15;
BA_ "NmAsrMessage" BO_ 2654486593 1;
BA_ "NmMessage" BO_ 2654486593 1;
BA_ "Type" BO_ 2654486593 8;
BA_ "CANFD_BRS" BO_ 2654486531 1;
BA_ "VFrameFormat" BO_ 2654486531 15;
BA_ "NmAsrMessage" BO_ 2654486531 1;
BA_ "NmMessage" BO_ 2654486531 1;
BA_ "Type" BO_ 2654486531 8;
BA_ "CANFD_BRS" BO_ 2654486549 1;
BA_ "VFrameFormat" BO_ 2654486549 15;
BA_ "NmAsrMessage" BO_ 2654486549 1;
BA_ "NmMessage" BO_ 2654486549 1;
BA_ "Type" BO_ 2654486549 8;
BA_ "CANFD_BRS" BO_ 2654486529 1;
BA_ "VFrameFormat" BO_ 2654486529 15;
BA_ "NmAsrMessage" BO_ 2654486529 1;
BA_ "NmMessage" BO_ 2654486529 1;
BA_ "Type" BO_ 2654486529 8;
BA_ "CANFD_BRS" BO_ 2654486595 1;
BA_ "VFrameFormat" BO_ 2654486595 15;
BA_ "NmAsrMessage" BO_ 2654486595 1;
BA_ "NmMessage" BO_ 2654486595 1;
BA_ "Type" BO_ 2654486595 8;
BA_ "GenSigTimeoutTime_SGW" SG_ 2654486531 CBV_bit2 0;
BA_ "GenSigTimeoutTime_RFHM" SG_ 2654486531 CBV_bit2 0;
BA_ "GenSigTimeoutTime_MPAD" SG_ 2654486531 CBV_bit2 0;
BA_ "GenSigTimeoutTime_IPC" SG_ 2654486531 CBV_bit2 0;
BA_ "GenSigTimeoutTime_GNMM" SG_ 2654486531 CBV_bit2 0;
BA_ "GenSigTimeoutTime_EVCU2" SG_ 2654486531 CBV_bit2 0;
BA_ "GenSigTimeoutTime_ESL" SG_ 2654486531 CBV_bit2 0;
BA_ "GenSigTimeoutTime_ECM" SG_ 2654486531 CBV_bit2 0;
BA_ "GenSigTimeoutTime_DTCM" SG_ 2654486531 CBV_bit2 0;
BA_ "GenSigTimeoutTime_DMSM" SG_ 2654486531 CBV_bit2 0;
BA_ "GenSigTimeoutTime_BSM" SG_ 2654486531 CBV_bit2 0;
BA_ "GenSigTimeoutTime_BCM" SG_ 2654486531 CBV_bit2 0;
BA_ "GenSigTimeoutTime_AGSM" SG_ 2654486531 CBV_bit2 0;
BA_ "GenSigTimeoutTime_ADCAM" SG_ 2654486531 CBV_bit2 0;
BA_ "GenSigTimeoutTime_SGW" SG_ 2654486549 CBV_bit2 0;
BA_ "GenSigTimeoutTime_RFHM" SG_ 2654486549 CBV_bit2 0;
BA_ "GenSigTimeoutTime_MPAD" SG_ 2654486549 CBV_bit2 0;
BA_ "GenSigTimeoutTime_IPC" SG_ 2654486549 CBV_bit2 0;
BA_ "GenSigTimeoutTime_GNMM" SG_ 2654486549 CBV_bit2 0;
BA_ "GenSigTimeoutTime_EVCU2" SG_ 2654486549 CBV_bit2 0;
BA_ "GenSigTimeoutTime_ESL" SG_ 2654486549 CBV_bit2 0;
BA_ "GenSigTimeoutTime_ECM" SG_ 2654486549 CBV_bit2 0;
BA_ "GenSigTimeoutTime_DTCM" SG_ 2654486549 CBV_bit2 0;
BA_ "GenSigTimeoutTime_DMSM" SG_ 2654486549 CBV_bit2 0;
BA_ "GenSigTimeoutTime_BSM" SG_ 2654486549 CBV_bit2 0;
BA_ "GenSigTimeoutTime_BCM" SG_ 2654486549 CBV_bit2 0;
BA_ "GenSigTimeoutTime_AGSM" SG_ 2654486549 CBV_bit2 0;
BA_ "GenSigTimeoutTime_ADCAM" SG_ 2654486549 CBV_bit2 0;
BA_ "GenSigTimeoutTime_SGW" SG_ 2654486549 CBV_bit3_NMCoordinatorBit 0;
BA_ "GenSigTimeoutTime_RFHM" SG_ 2654486549 CBV_bit3_NMCoordinatorBit 0;
BA_ "GenSigTimeoutTime_MPAD" SG_ 2654486549 CBV_bit3_NMCoordinatorBit 0;
BA_ "GenSigTimeoutTime_IPC" SG_ 2654486549 CBV_bit3_NMCoordinatorBit 0;
BA_ "GenSigTimeoutTime_GNMM" SG_ 2654486549 CBV_bit3_NMCoordinatorBit 0;
BA_ "GenSigTimeoutTime_EVCU2" SG_ 2654486549 CBV_bit3_NMCoordinatorBit 0;
BA_ "GenSigTimeoutTime_ESL" SG_ 2654486549 CBV_bit3_NMCoordinatorBit 0;
BA_ "GenSigTimeoutTime_ECM" SG_ 2654486549 CBV_bit3_NMCoordinatorBit 0;
BA_ "GenSigTimeoutTime_DTCM" SG_ 2654486549 CBV_bit3_NMCoordinatorBit 0;
BA_ "GenSigTimeoutTime_DMSM" SG_ 2654486549 CBV_bit3_NMCoordinatorBit 0;
BA_ "GenSigTimeoutTime_BSM" SG_ 2654486549 CBV_bit3_NMCoordinatorBit 0;
BA_ "GenSigTimeoutTime_BCM" SG_ 2654486549 CBV_bit3_NMCoordinatorBit 0;
BA_ "GenSigTimeoutTime_AGSM" SG_ 2654486549 CBV_bit3_NMCoordinatorBit 0;
BA_ "GenSigTimeoutTime_ADCAM" SG_ 2654486549 CBV_bit3_NMCoordinatorBit 0;
BA_ "GenSigTimeoutTime_SGW" SG_ 2654486549 CBV_bit4_ActiveWakeupBit 0;
BA_ "GenSigTimeoutTime_RFHM" SG_ 2654486549 CBV_bit4_ActiveWakeupBit 0;
BA_ "GenSigTimeoutTime_MPAD" SG_ 2654486549 CBV_bit4_ActiveWakeupBit 0;
BA_ "GenSigTimeoutTime_IPC" SG_ 2654486549 CBV_bit4_ActiveWakeupBit 0;
BA_ "GenSigTimeoutTime_GNMM" SG_ 2654486549 CBV_bit4_ActiveWakeupBit 0;
BA_ "GenSigTimeoutTime_EVCU2" SG_ 2654486549 CBV_bit4_ActiveWakeupBit 0;
BA_ "GenSigTimeoutTime_ESL" SG_ 2654486549 CBV_bit4_ActiveWakeupBit 0;
BA_ "GenSigTimeoutTime_ECM" SG_ 2654486549 CBV_bit4_ActiveWakeupBit 0;
BA_ "GenSigTimeoutTime_DTCM" SG_ 2654486549 CBV_bit4_ActiveWakeupBit 0;
BA_ "GenSigTimeoutTime_DMSM" SG_ 2654486549 CBV_bit4_ActiveWakeupBit 0;
BA_ "GenSigTimeoutTime_BSM" SG_ 2654486549 CBV_bit4_ActiveWakeupBit 0;
BA_ "GenSigTimeoutTime_BCM" SG_ 2654486549 CBV_bit4_ActiveWakeupBit 0;
BA_ "GenSigTimeoutTime_AGSM" SG_ 2654486549 CBV_bit4_ActiveWakeupBit 0;
BA_ "GenSigTimeoutTime_ADCAM" SG_ 2654486549 CBV_bit4_ActiveWakeupBit 0;
BA_ "GenSigTimeoutTime_SGW" SG_ 2654486529 CBV_bit4_ActiveWakeupBit 0;
BA_ "GenSigTimeoutTime_RFHM" SG_ 2654486529 CBV_bit4_ActiveWakeupBit 0;
BA_ "GenSigTimeoutTime_MPAD" SG_ 2654486529 CBV_bit4_ActiveWakeupBit 0;
BA_ "GenSigTimeoutTime_IPC" SG_ 2654486529 CBV_bit4_ActiveWakeupBit 0;
BA_ "GenSigTimeoutTime_GNMM" SG_ 2654486529 CBV_bit4_ActiveWakeupBit 0;
BA_ "GenSigTimeoutTime_EVCU2" SG_ 2654486529 CBV_bit4_ActiveWakeupBit 0;
BA_ "GenSigTimeoutTime_ESL" SG_ 2654486529 CBV_bit4_ActiveWakeupBit 0;
BA_ "GenSigTimeoutTime_ECM" SG_ 2654486529 CBV_bit4_ActiveWakeupBit 0;
BA_ "GenSigTimeoutTime_DTCM" SG_ 2654486529 CBV_bit4_ActiveWakeupBit 0;
BA_ "GenSigTimeoutTime_DMSM" SG_ 2654486529 CBV_bit4_ActiveWakeupBit 0;
BA_ "GenSigTimeoutTime_BSM" SG_ 2654486529 CBV_bit4_ActiveWakeupBit 0;
BA_ "GenSigTimeoutTime_SGW" SG_ 2654486529 CBV_bit5 0;
BA_ "GenSigTimeoutTime_RFHM" SG_ 2654486529 CBV_bit5 0;
BA_ "GenSigTimeoutTime_MPAD" SG_ 2654486529 CBV_bit5 0;
BA_ "GenSigTimeoutTime_IPC" SG_ 2654486529 CBV_bit5 0;
BA_ "GenSigTimeoutTime_GNMM" SG_ 2654486529 CBV_bit5 0;
BA_ "GenSigTimeoutTime_EVCU2" SG_ 2654486529 CBV_bit5 0;
BA_ "GenSigTimeoutTime_ESL" SG_ 2654486529 CBV_bit5 0;
BA_ "GenSigTimeoutTime_ECM" SG_ 2654486529 CBV_bit5 0;
BA_ "GenSigTimeoutTime_DTCM" SG_ 2654486529 CBV_bit5 0;
BA_ "GenSigTimeoutTime_DMSM" SG_ 2654486529 CBV_bit5 0;
BA_ "GenSigTimeoutTime_BSM" SG_ 2654486529 CBV_bit5 0;
BA_ "GenSigTimeoutTime_BCM" SG_ 2654486529 CBV_bit5 0;
BA_ "GenSigTimeoutTime_AGSM" SG_ 2654486529 CBV_bit5 0;
BA_ "GenSigTimeoutTime_ADCAM" SG_ 2654486529 CBV_bit5 0;
BA_ "GenSigTimeoutTime_SGW" SG_ 2654486549 CBV_bit5 0;
BA_ "GenSigTimeoutTime_RFHM" SG_ 2654486549 CBV_bit5 0;
BA_ "GenSigTimeoutTime_MPAD" SG_ 2654486549 CBV_bit5 0;
BA_ "GenSigTimeoutTime_IPC" SG_ 2654486549 CBV_bit5 0;
BA_ "GenSigTimeoutTime_GNMM" SG_ 2654486549 CBV_bit5 0;
BA_ "GenSigTimeoutTime_EVCU2" SG_ 2654486549 CBV_bit5 0;
BA_ "GenSigTimeoutTime_ESL" SG_ 2654486549 CBV_bit5 0;
BA_ "GenSigTimeoutTime_ECM" SG_ 2654486549 CBV_bit5 0;
BA_ "GenSigTimeoutTime_DTCM" SG_ 2654486549 CBV_bit5 0;
BA_ "GenSigTimeoutTime_DMSM" SG_ 2654486549 CBV_bit5 0;
BA_ "GenSigTimeoutTime_BSM" SG_ 2654486549 CBV_bit5 0;
BA_ "GenSigTimeoutTime_BCM" SG_ 2654486549 CBV_bit5 0;
BA_ "GenSigTimeoutTime_AGSM" SG_ 2654486549 CBV_bit5 0;
BA_ "GenSigTimeoutTime_ADCAM" SG_ 2654486549 CBV_bit5 0;
BA_ "GenSigTimeoutTime_SGW" SG_ 2654486549 CBV_bit6_PartialNtwInfBit 0;
BA_ "GenSigTimeoutTime_RFHM" SG_ 2654486549 CBV_bit6_PartialNtwInfBit 0;
BA_ "GenSigTimeoutTime_MPAD" SG_ 2654486549 CBV_bit6_PartialNtwInfBit 0;
BA_ "GenSigTimeoutTime_IPC" SG_ 2654486549 CBV_bit6_PartialNtwInfBit 0;
BA_ "GenSigTimeoutTime_GNMM" SG_ 2654486549 CBV_bit6_PartialNtwInfBit 0;
BA_ "GenSigTimeoutTime_EVCU2" SG_ 2654486549 CBV_bit6_PartialNtwInfBit 0;
BA_ "GenSigTimeoutTime_ESL" SG_ 2654486549 CBV_bit6_PartialNtwInfBit 0;
BA_ "GenSigTimeoutTime_ECM" SG_ 2654486549 CBV_bit6_PartialNtwInfBit 0;
BA_ "GenSigTimeoutTime_DTCM" SG_ 2654486549 CBV_bit6_PartialNtwInfBit 0;
BA_ "GenSigTimeoutTime_DMSM" SG_ 2654486549 CBV_bit6_PartialNtwInfBit 0;
BA_ "GenSigTimeoutTime_BSM" SG_ 2654486549 CBV_bit6_PartialNtwInfBit 0;
BA_ "GenSigTimeoutTime_BCM" SG_ 2654486549 CBV_bit6_PartialNtwInfBit 0;
BA_ "GenSigTimeoutTime_AGSM" SG_ 2654486549 CBV_bit6_PartialNtwInfBit 0;
BA_ "GenSigTimeoutTime_ADCAM" SG_ 2654486549 CBV_bit6_PartialNtwInfBit 0;
BA_ "GenSigTimeoutTime_EVCU2" SG_ 2654486529 CBV_bit6_PartialNtwInfBit 0;
BA_ "GenSigTimeoutTime_ESL" SG_ 2654486529 CBV_bit6_PartialNtwInfBit 0;
BA_ "GenSigTimeoutTime_ECM" SG_ 2654486529 CBV_bit6_PartialNtwInfBit 0;
BA_ "GenSigTimeoutTime_DTCM" SG_ 2654486529 CBV_bit6_PartialNtwInfBit 0;
BA_ "GenSigTimeoutTime_DMSM" SG_ 2654486529 CBV_bit6_PartialNtwInfBit 0;
BA_ "GenSigTimeoutTime_BSM" SG_ 2654486529 CBV_bit6_PartialNtwInfBit 0;
BA_ "GenSigTimeoutTime_BCM" SG_ 2654486529 CBV_bit6_PartialNtwInfBit 0;
BA_ "GenSigTimeoutTime_AGSM" SG_ 2654486529 CBV_bit6_PartialNtwInfBit 0;
BA_ "GenSigTimeoutTime_ADCAM" SG_ 2654486529 CBV_bit6_PartialNtwInfBit 0;
BA_ "GenSigTimeoutTime_SGW" SG_ 2654486529 CBV_bit6_PartialNtwInfBit 0;
BA_ "GenSigTimeoutTime_RFHM" SG_ 2654486529 CBV_bit6_PartialNtwInfBit 0;
BA_ "GenSigTimeoutTime_MPAD" SG_ 2654486529 CBV_bit6_PartialNtwInfBit 0;
BA_ "GenSigTimeoutTime_IPC" SG_ 2654486529 CBV_bit6_PartialNtwInfBit 0;
BA_ "GenSigTimeoutTime_GNMM" SG_ 2654486529 CBV_bit6_PartialNtwInfBit 0;
BA_ "GenSigTimeoutTime_SGW" SG_ 2654486549 CBV_bit7 0;
BA_ "GenSigTimeoutTime_RFHM" SG_ 2654486549 CBV_bit7 0;
BA_ "GenSigTimeoutTime_MPAD" SG_ 2654486549 CBV_bit7 0;
BA_ "GenSigTimeoutTime_IPC" SG_ 2654486549 CBV_bit7 0;
BA_ "GenSigTimeoutTime_GNMM" SG_ 2654486549 CBV_bit7 0;
BA_ "GenSigTimeoutTime_EVCU2" SG_ 2654486549 CBV_bit7 0;
BA_ "GenSigTimeoutTime_ESL" SG_ 2654486549 CBV_bit7 0;
BA_ "GenSigTimeoutTime_ECM" SG_ 2654486549 CBV_bit7 0;
BA_ "GenSigTimeoutTime_DTCM" SG_ 2654486549 CBV_bit7 0;
BA_ "GenSigTimeoutTime_DMSM" SG_ 2654486549 CBV_bit7 0;
BA_ "GenSigTimeoutTime_BSM" SG_ 2654486549 CBV_bit7 0;
BA_ "GenSigTimeoutTime_BCM" SG_ 2654486549 CBV_bit7 0;
BA_ "GenSigTimeoutTime_AGSM" SG_ 2654486549 CBV_bit7 0;
BA_ "GenSigTimeoutTime_ADCAM" SG_ 2654486549 CBV_bit7 0;
BA_ "GenSigTimeoutTime_SGW" SG_ 2654486529 CBV_bit7 0;
BA_ "GenSigTimeoutTime_RFHM" SG_ 2654486529 CBV_bit7 0;
BA_ "GenSigTimeoutTime_MPAD" SG_ 2654486529 CBV_bit7 0;
BA_ "GenSigTimeoutTime_IPC" SG_ 2654486529 CBV_bit7 0;
BA_ "GenSigTimeoutTime_GNMM" SG_ 2654486529 CBV_bit7 0;
BA_ "GenSigTimeoutTime_EVCU2" SG_ 2654486529 CBV_bit7 0;
BA_ "GenSigTimeoutTime_ESL" SG_ 2654486529 CBV_bit7 0;
BA_ "GenSigTimeoutTime_ECM" SG_ 2654486529 CBV_bit7 0;
BA_ "GenSigTimeoutTime_DTCM" SG_ 2654486529 CBV_bit7 0;
BA_ "GenSigTimeoutTime_DMSM" SG_ 2654486529 CBV_bit7 0;
BA_ "GenSigTimeoutTime_BSM" SG_ 2654486529 CBV_bit7 0;
BA_ "GenSigTimeoutTime_BCM" SG_ 2654486529 CBV_bit7 0;
BA_ "GenSigTimeoutTime_AGSM" SG_ 2654486529 CBV_bit7 0;
BA_ "GenSigTimeoutTime_ADCAM" SG_ 2654486529 CBV_bit7 0;
BA_ "GenSigTimeoutTime_SGW" SG_ 2654486549 SourceNodeIdentifier 0;
BA_ "GenSigTimeoutTime_RFHM" SG_ 2654486549 SourceNodeIdentifier 0;
BA_ "GenSigTimeoutTime_MPAD" SG_ 2654486549 SourceNodeIdentifier 0;
BA_ "GenSigTimeoutTime_IPC" SG_ 2654486549 SourceNodeIdentifier 0;
BA_ "GenSigTimeoutTime_GNMM" SG_ 2654486549 SourceNodeIdentifier 0;
BA_ "GenSigTimeoutTime_EVCU2" SG_ 2654486549 SourceNodeIdentifier 0;
BA_ "GenSigTimeoutTime_ESL" SG_ 2654486549 SourceNodeIdentifier 0;
BA_ "GenSigTimeoutTime_ECM" SG_ 2654486549 SourceNodeIdentifier 0;
BA_ "GenSigTimeoutTime_DTCM" SG_ 2654486549 SourceNodeIdentifier 0;
BA_ "GenSigTimeoutTime_DMSM" SG_ 2654486549 SourceNodeIdentifier 0;
BA_ "GenSigTimeoutTime_BSM" SG_ 2654486549 SourceNodeIdentifier 0;
BA_ "GenSigTimeoutTime_BCM" SG_ 2654486549 SourceNodeIdentifier 0;
BA_ "GenSigTimeoutTime_AGSM" SG_ 2654486549 SourceNodeIdentifier 0;
BA_ "GenSigTimeoutTime_ADCAM" SG_ 2654486549 SourceNodeIdentifier 0;
BA_ "GenSigTimeoutTime_SGW" SG_ 2654486529 SourceNodeIdentifier 0;
BA_ "GenSigTimeoutTime_RFHM" SG_ 2654486529 SourceNodeIdentifier 0;
BA_ "GenSigTimeoutTime_MPAD" SG_ 2654486529 SourceNodeIdentifier 0;
BA_ "GenSigTimeoutTime_IPC" SG_ 2654486529 SourceNodeIdentifier 0;
BA_ "GenSigTimeoutTime_GNMM" SG_ 2654486529 SourceNodeIdentifier 0;
BA_ "GenSigTimeoutTime_EVCU2" SG_ 2654486529 SourceNodeIdentifier 0;
BA_ "GenSigTimeoutTime_ESL" SG_ 2654486529 SourceNodeIdentifier 0;
BA_ "GenSigTimeoutTime_ECM" SG_ 2654486529 SourceNodeIdentifier 0;
BA_ "GenSigTimeoutTime_DTCM" SG_ 2654486529 SourceNodeIdentifier 0;
BA_ "GenSigTimeoutTime_DMSM" SG_ 2654486529 SourceNodeIdentifier 0;
BA_ "GenSigTimeoutTime_BSM" SG_ 2654486529 SourceNodeIdentifier 0;
BA_ "GenSigTimeoutTime_BCM" SG_ 2654486529 SourceNodeIdentifier 0;
BA_ "GenSigTimeoutTime_AGSM" SG_ 2654486529 SourceNodeIdentifier 0;
BA_ "GenSigTimeoutTime_ADCAM" SG_ 2654486529 SourceNodeIdentifier 0;
BA_ "GenSigTimeoutTime_SGW" SG_ 2654486549 CBV_bit1 0;
BA_ "GenSigTimeoutTime_RFHM" SG_ 2654486549 CBV_bit1 0;
BA_ "GenSigTimeoutTime_MPAD" SG_ 2654486549 CBV_bit1 0;
BA_ "GenSigTimeoutTime_IPC" SG_ 2654486549 CBV_bit1 0;
BA_ "GenSigTimeoutTime_GNMM" SG_ 2654486549 CBV_bit1 0;
BA_ "GenSigTimeoutTime_EVCU2" SG_ 2654486549 CBV_bit1 0;
BA_ "GenSigTimeoutTime_ESL" SG_ 2654486549 CBV_bit1 0;
BA_ "GenSigTimeoutTime_ECM" SG_ 2654486549 CBV_bit1 0;
BA_ "GenSigTimeoutTime_DTCM" SG_ 2654486549 CBV_bit1 0;
BA_ "GenSigTimeoutTime_DMSM" SG_ 2654486549 CBV_bit1 0;
BA_ "GenSigTimeoutTime_BSM" SG_ 2654486549 CBV_bit1 0;
BA_ "GenSigTimeoutTime_BCM" SG_ 2654486549 CBV_bit1 0;
BA_ "GenSigTimeoutTime_AGSM" SG_ 2654486549 CBV_bit1 0;
BA_ "GenSigTimeoutTime_ADCAM" SG_ 2654486549 CBV_bit1 0;
BA_ "GenSigTimeoutTime_SGW" SG_ 2654486549 CBV_bit0_RepeatMessageRequestBit 0;
BA_ "GenSigTimeoutTime_RFHM" SG_ 2654486549 CBV_bit0_RepeatMessageRequestBit 0;
BA_ "GenSigTimeoutTime_MPAD" SG_ 2654486549 CBV_bit0_RepeatMessageRequestBit 0;
BA_ "GenSigTimeoutTime_IPC" SG_ 2654486549 CBV_bit0_RepeatMessageRequestBit 0;
BA_ "GenSigTimeoutTime_GNMM" SG_ 2654486549 CBV_bit0_RepeatMessageRequestBit 0;
BA_ "GenSigTimeoutTime_EVCU2" SG_ 2654486549 CBV_bit0_RepeatMessageRequestBit 0;
BA_ "GenSigTimeoutTime_ESL" SG_ 2654486549 CBV_bit0_RepeatMessageRequestBit 0;
BA_ "GenSigTimeoutTime_ECM" SG_ 2654486549 CBV_bit0_RepeatMessageRequestBit 0;
BA_ "GenSigTimeoutTime_DTCM" SG_ 2654486549 CBV_bit0_RepeatMessageRequestBit 0;
BA_ "GenSigTimeoutTime_DMSM" SG_ 2654486549 CBV_bit0_RepeatMessageRequestBit 0;
BA_ "GenSigTimeoutTime_BSM" SG_ 2654486549 CBV_bit0_RepeatMessageRequestBit 0;
BA_ "GenSigTimeoutTime_BCM" SG_ 2654486549 CBV_bit0_RepeatMessageRequestBit 0;
BA_ "GenSigTimeoutTime_AGSM" SG_ 2654486549 CBV_bit0_RepeatMessageRequestBit 0;
BA_ "GenSigTimeoutTime_ADCAM" SG_ 2654486549 CBV_bit0_RepeatMessageRequestBit 0;
BA_ "GenSigTimeoutTime_SGW" SG_ 2654486529 CBV_bit0_RepeatMessageRequestBit 0;
BA_ "GenSigTimeoutTime_RFHM" SG_ 2654486529 CBV_bit0_RepeatMessageRequestBit 0;
BA_ "GenSigTimeoutTime_MPAD" SG_ 2654486529 CBV_bit0_RepeatMessageRequestBit 0;
BA_ "GenSigTimeoutTime_IPC" SG_ 2654486529 CBV_bit0_RepeatMessageRequestBit 0;
BA_ "GenSigTimeoutTime_GNMM" SG_ 2654486529 CBV_bit0_RepeatMessageRequestBit 0;
BA_ "GenSigTimeoutTime_EVCU2" SG_ 2654486529 CBV_bit0_RepeatMessageRequestBit 0;
BA_ "GenSigTimeoutTime_ESL" SG_ 2654486529 CBV_bit0_RepeatMessageRequestBit 0;
BA_ "GenSigTimeoutTime_ECM" SG_ 2654486529 CBV_bit0_RepeatMessageRequestBit 0;
BA_ "GenSigTimeoutTime_DTCM" SG_ 2654486529 CBV_bit0_RepeatMessageRequestBit 0;
BA_ "GenSigTimeoutTime_DMSM" SG_ 2654486529 CBV_bit0_RepeatMessageRequestBit 0;
BA_ "GenSigTimeoutTime_BSM" SG_ 2654486529 CBV_bit0_RepeatMessageRequestBit 0;
BA_ "GenSigTimeoutTime_BCM" SG_ 2654486529 CBV_bit0_RepeatMessageRequestBit 0;
BA_ "GenSigTimeoutTime_AGSM" SG_ 2654486529 CBV_bit0_RepeatMessageRequestBit 0;
BA_ "GenSigTimeoutTime_ADCAM" SG_ 2654486529 CBV_bit0_RepeatMessageRequestBit 0;
BA_ "GenSigTimeoutTime_SGW" SG_ 2654486595 CBV_bit0_RepeatMessageRequestBit 0;
BA_ "GenSigTimeoutTime_RFHM" SG_ 2654486595 CBV_bit0_RepeatMessageRequestBit 0;
BA_ "GenSigTimeoutTime_MPAD" SG_ 2654486595 CBV_bit0_RepeatMessageRequestBit 0;
BA_ "GenSigTimeoutTime_IPC" SG_ 2654486595 CBV_bit0_RepeatMessageRequestBit 0;
BA_ "GenSigTimeoutTime_GNMM" SG_ 2654486595 CBV_bit0_RepeatMessageRequestBit 0;
BA_ "GenSigTimeoutTime_EVCU2" SG_ 2654486595 CBV_bit0_RepeatMessageRequestBit 0;
BA_ "GenSigTimeoutTime_ESL" SG_ 2654486595 CBV_bit0_RepeatMessageRequestBit 0;
BA_ "GenSigTimeoutTime_ECM" SG_ 2654486595 CBV_bit0_RepeatMessageRequestBit 0;
BA_ "GenSigTimeoutTime_DTCM" SG_ 2654486595 CBV_bit0_RepeatMessageRequestBit 0;
BA_ "GenSigTimeoutTime_DMSM" SG_ 2654486595 CBV_bit0_RepeatMessageRequestBit 0;
BA_ "GenSigTimeoutTime_BSM" SG_ 2654486595 CBV_bit0_RepeatMessageRequestBit 0;
BA_ "GenSigTimeoutTime_BCM" SG_ 2654486595 CBV_bit0_RepeatMessageRequestBit 0;
BA_ "GenSigTimeoutTime_AGSM" SG_ 2654486595 CBV_bit0_RepeatMessageRequestBit 0;
BA_ "GenSigTimeoutTime_ADCAM" SG_ 2654486595 CBV_bit0_RepeatMessageRequestBit 0;
BA_ "GenSigTimeoutTime_SGW" SG_ 2654486529 CBV_bit1 0;
BA_ "GenSigTimeoutTime_RFHM" SG_ 2654486529 CBV_bit1 0;
BA_ "GenSigTimeoutTime_MPAD" SG_ 2654486529 CBV_bit1 0;
BA_ "GenSigTimeoutTime_IPC" SG_ 2654486529 CBV_bit1 0;
BA_ "GenSigTimeoutTime_GNMM" SG_ 2654486529 CBV_bit1 0;
BA_ "GenSigTimeoutTime_EVCU2" SG_ 2654486529 CBV_bit1 0;
BA_ "GenSigTimeoutTime_ESL" SG_ 2654486529 CBV_bit1 0;
BA_ "GenSigTimeoutTime_ECM" SG_ 2654486529 CBV_bit1 0;
BA_ "GenSigTimeoutTime_DTCM" SG_ 2654486529 CBV_bit1 0;
BA_ "GenSigTimeoutTime_DMSM" SG_ 2654486529 CBV_bit1 0;
BA_ "GenSigTimeoutTime_BSM" SG_ 2654486529 CBV_bit1 0;
BA_ "GenSigTimeoutTime_BCM" SG_ 2654486529 CBV_bit1 0;
BA_ "GenSigTimeoutTime_AGSM" SG_ 2654486529 CBV_bit1 0;
BA_ "GenSigTimeoutTime_ADCAM" SG_ 2654486529 CBV_bit1 0;
BA_ "GenSigTimeoutTime_SGW" SG_ 2654486595 CBV_bit1 0;
BA_ "GenSigTimeoutTime_RFHM" SG_ 2654486595 CBV_bit1 0;
BA_ "GenSigTimeoutTime_MPAD" SG_ 2654486595 CBV_bit1 0;
BA_ "GenSigTimeoutTime_IPC" SG_ 2654486595 CBV_bit1 0;
BA_ "GenSigTimeoutTime_GNMM" SG_ 2654486595 CBV_bit1 0;
BA_ "GenSigTimeoutTime_EVCU2" SG_ 2654486595 CBV_bit1 0;
BA_ "GenSigTimeoutTime_ESL" SG_ 2654486595 CBV_bit1 0;
BA_ "GenSigTimeoutTime_ECM" SG_ 2654486595 CBV_bit1 0;
BA_ "GenSigTimeoutTime_DTCM" SG_ 2654486595 CBV_bit1 0;
BA_ "GenSigTimeoutTime_DMSM" SG_ 2654486595 CBV_bit1 0;
BA_ "GenSigTimeoutTime_BSM" SG_ 2654486595 CBV_bit1 0;
BA_ "GenSigTimeoutTime_BCM" SG_ 2654486595 CBV_bit1 0;
BA_ "GenSigTimeoutTime_AGSM" SG_ 2654486595 CBV_bit1 0;
BA_ "GenSigTimeoutTime_ADCAM" SG_ 2654486595 CBV_bit1 0;
BA_ "GenSigTimeoutTime_SGW" SG_ 2654486595 SourceNodeIdentifier 0;
BA_ "GenSigTimeoutTime_RFHM" SG_ 2654486595 SourceNodeIdentifier 0;
BA_ "GenSigTimeoutTime_MPAD" SG_ 2654486595 SourceNodeIdentifier 0;
BA_ "GenSigTimeoutTime_IPC" SG_ 2654486595 SourceNodeIdentifier 0;
BA_ "GenSigTimeoutTime_GNMM" SG_ 2654486595 SourceNodeIdentifier 0;
BA_ "GenSigTimeoutTime_EVCU2" SG_ 2654486595 SourceNodeIdentifier 0;
BA_ "GenSigTimeoutTime_ESL" SG_ 2654486595 SourceNodeIdentifier 0;
BA_ "GenSigTimeoutTime_ECM" SG_ 2654486595 SourceNodeIdentifier 0;
BA_ "GenSigTimeoutTime_DTCM" SG_ 2654486595 SourceNodeIdentifier 0;
BA_ "GenSigTimeoutTime_DMSM" SG_ 2654486595 SourceNodeIdentifier 0;
BA_ "GenSigTimeoutTime_BSM" SG_ 2654486595 SourceNodeIdentifier 0;
BA_ "GenSigTimeoutTime_BCM" SG_ 2654486595 SourceNodeIdentifier 0;
BA_ "GenSigTimeoutTime_AGSM" SG_ 2654486595 SourceNodeIdentifier 0;
BA_ "GenSigTimeoutTime_ADCAM" SG_ 2654486595 SourceNodeIdentifier 0;
BA_ "GenSigTimeoutTime_SGW" SG_ 2654486595 CBV_bit7 0;
BA_ "GenSigTimeoutTime_RFHM" SG_ 2654486595 CBV_bit7 0;
BA_ "GenSigTimeoutTime_MPAD" SG_ 2654486595 CBV_bit7 0;
BA_ "GenSigTimeoutTime_IPC" SG_ 2654486595 CBV_bit7 0;
BA_ "GenSigTimeoutTime_GNMM" SG_ 2654486595 CBV_bit7 0;
BA_ "GenSigTimeoutTime_EVCU2" SG_ 2654486595 CBV_bit7 0;
BA_ "GenSigTimeoutTime_ESL" SG_ 2654486595 CBV_bit7 0;
BA_ "GenSigTimeoutTime_ECM" SG_ 2654486595 CBV_bit7 0;
BA_ "GenSigTimeoutTime_DTCM" SG_ 2654486595 CBV_bit7 0;
BA_ "GenSigTimeoutTime_DMSM" SG_ 2654486595 CBV_bit7 0;
BA_ "GenSigTimeoutTime_BSM" SG_ 2654486595 CBV_bit7 0;
BA_ "GenSigTimeoutTime_BCM" SG_ 2654486595 CBV_bit7 0;
BA_ "GenSigTimeoutTime_AGSM" SG_ 2654486595 CBV_bit7 0;
BA_ "GenSigTimeoutTime_ADCAM" SG_ 2654486595 CBV_bit7 0;
BA_ "GenSigTimeoutTime_SGW" SG_ 2654486595 CBV_bit6_PartialNtwInfBit 0;
BA_ "GenSigTimeoutTime_RFHM" SG_ 2654486595 CBV_bit6_PartialNtwInfBit 0;
BA_ "GenSigTimeoutTime_MPAD" SG_ 2654486595 CBV_bit6_PartialNtwInfBit 0;
BA_ "GenSigTimeoutTime_IPC" SG_ 2654486595 CBV_bit6_PartialNtwInfBit 0;
BA_ "GenSigTimeoutTime_GNMM" SG_ 2654486595 CBV_bit6_PartialNtwInfBit 0;
BA_ "GenSigTimeoutTime_EVCU2" SG_ 2654486595 CBV_bit6_PartialNtwInfBit 0;
BA_ "GenSigTimeoutTime_ESL" SG_ 2654486595 CBV_bit6_PartialNtwInfBit 0;
BA_ "GenSigTimeoutTime_ECM" SG_ 2654486595 CBV_bit6_PartialNtwInfBit 0;
BA_ "GenSigTimeoutTime_DTCM" SG_ 2654486595 CBV_bit6_PartialNtwInfBit 0;
BA_ "GenSigTimeoutTime_DMSM" SG_ 2654486595 CBV_bit6_PartialNtwInfBit 0;
BA_ "GenSigTimeoutTime_BSM" SG_ 2654486595 CBV_bit6_PartialNtwInfBit 0;
BA_ "GenSigTimeoutTime_BCM" SG_ 2654486595 CBV_bit6_PartialNtwInfBit 0;
BA_ "GenSigTimeoutTime_AGSM" SG_ 2654486595 CBV_bit6_PartialNtwInfBit 0;
BA_ "GenSigTimeoutTime_ADCAM" SG_ 2654486595 CBV_bit6_PartialNtwInfBit 0;
BA_ "GenSigTimeoutTime_SGW" SG_ 2654486595 CBV_bit5 0;
BA_ "GenSigTimeoutTime_RFHM" SG_ 2654486595 CBV_bit5 0;
BA_ "GenSigTimeoutTime_MPAD" SG_ 2654486595 CBV_bit5 0;
BA_ "GenSigTimeoutTime_IPC" SG_ 2654486595 CBV_bit5 0;
BA_ "GenSigTimeoutTime_GNMM" SG_ 2654486595 CBV_bit5 0;
BA_ "GenSigTimeoutTime_EVCU2" SG_ 2654486595 CBV_bit5 0;
BA_ "GenSigTimeoutTime_ESL" SG_ 2654486595 CBV_bit5 0;
BA_ "GenSigTimeoutTime_ECM" SG_ 2654486595 CBV_bit5 0;
BA_ "GenSigTimeoutTime_DTCM" SG_ 2654486595 CBV_bit5 0;
BA_ "GenSigTimeoutTime_DMSM" SG_ 2654486595 CBV_bit5 0;
BA_ "GenSigTimeoutTime_BSM" SG_ 2654486595 CBV_bit5 0;
BA_ "GenSigTimeoutTime_BCM" SG_ 2654486595 CBV_bit5 0;
BA_ "GenSigTimeoutTime_AGSM" SG_ 2654486595 CBV_bit5 0;
BA_ "GenSigTimeoutTime_ADCAM" SG_ 2654486595 CBV_bit5 0;
BA_ "GenSigTimeoutTime_BCM" SG_ 2654486529 CBV_bit4_ActiveWakeupBit 0;
BA_ "GenSigTimeoutTime_AGSM" SG_ 2654486529 CBV_bit4_ActiveWakeupBit 0;
BA_ "GenSigTimeoutTime_ADCAM" SG_ 2654486529 CBV_bit4_ActiveWakeupBit 0;
BA_ "GenSigTimeoutTime_SGW" SG_ 2654486595 CBV_bit4_ActiveWakeupBit 0;
BA_ "GenSigTimeoutTime_RFHM" SG_ 2654486595 CBV_bit4_ActiveWakeupBit 0;
BA_ "GenSigTimeoutTime_MPAD" SG_ 2654486595 CBV_bit4_ActiveWakeupBit 0;
BA_ "GenSigTimeoutTime_IPC" SG_ 2654486595 CBV_bit4_ActiveWakeupBit 0;
BA_ "GenSigTimeoutTime_GNMM" SG_ 2654486595 CBV_bit4_ActiveWakeupBit 0;
BA_ "GenSigTimeoutTime_EVCU2" SG_ 2654486595 CBV_bit4_ActiveWakeupBit 0;
BA_ "GenSigTimeoutTime_ESL" SG_ 2654486595 CBV_bit4_ActiveWakeupBit 0;
BA_ "GenSigTimeoutTime_ECM" SG_ 2654486595 CBV_bit4_ActiveWakeupBit 0;
BA_ "GenSigTimeoutTime_DTCM" SG_ 2654486595 CBV_bit4_ActiveWakeupBit 0;
BA_ "GenSigTimeoutTime_DMSM" SG_ 2654486595 CBV_bit4_ActiveWakeupBit 0;
BA_ "GenSigTimeoutTime_BSM" SG_ 2654486595 CBV_bit4_ActiveWakeupBit 0;
BA_ "GenSigTimeoutTime_BCM" SG_ 2654486595 CBV_bit4_ActiveWakeupBit 0;
BA_ "GenSigTimeoutTime_AGSM" SG_ 2654486595 CBV_bit4_ActiveWakeupBit 0;
BA_ "GenSigTimeoutTime_ADCAM" SG_ 2654486595 CBV_bit4_ActiveWakeupBit 0;
BA_ "GenSigTimeoutTime_SGW" SG_ 2654486529 CBV_bit3_NMCoordinatorBit 0;
BA_ "GenSigTimeoutTime_RFHM" SG_ 2654486529 CBV_bit3_NMCoordinatorBit 0;
BA_ "GenSigTimeoutTime_MPAD" SG_ 2654486529 CBV_bit3_NMCoordinatorBit 0;
BA_ "GenSigTimeoutTime_IPC" SG_ 2654486529 CBV_bit3_NMCoordinatorBit 0;
BA_ "GenSigTimeoutTime_GNMM" SG_ 2654486529 CBV_bit3_NMCoordinatorBit 0;
BA_ "GenSigTimeoutTime_EVCU2" SG_ 2654486529 CBV_bit3_NMCoordinatorBit 0;
BA_ "GenSigTimeoutTime_ESL" SG_ 2654486529 CBV_bit3_NMCoordinatorBit 0;
BA_ "GenSigTimeoutTime_ECM" SG_ 2654486529 CBV_bit3_NMCoordinatorBit 0;
BA_ "GenSigTimeoutTime_DTCM" SG_ 2654486529 CBV_bit3_NMCoordinatorBit 0;
BA_ "GenSigTimeoutTime_DMSM" SG_ 2654486529 CBV_bit3_NMCoordinatorBit 0;
BA_ "GenSigTimeoutTime_BSM" SG_ 2654486529 CBV_bit3_NMCoordinatorBit 0;
BA_ "GenSigTimeoutTime_BCM" SG_ 2654486529 CBV_bit3_NMCoordinatorBit 0;
BA_ "GenSigTimeoutTime_AGSM" SG_ 2654486529 CBV_bit3_NMCoordinatorBit 0;
BA_ "GenSigTimeoutTime_ADCAM" SG_ 2654486529 CBV_bit3_NMCoordinatorBit 0;
BA_ "GenSigTimeoutTime_SGW" SG_ 2654486595 CBV_bit3_NMCoordinatorBit 0;
BA_ "GenSigTimeoutTime_RFHM" SG_ 2654486595 CBV_bit3_NMCoordinatorBit 0;
BA_ "GenSigTimeoutTime_MPAD" SG_ 2654486595 CBV_bit3_NMCoordinatorBit 0;
BA_ "GenSigTimeoutTime_IPC" SG_ 2654486595 CBV_bit3_NMCoordinatorBit 0;
BA_ "GenSigTimeoutTime_GNMM" SG_ 2654486595 CBV_bit3_NMCoordinatorBit 0;
BA_ "GenSigTimeoutTime_EVCU2" SG_ 2654486595 CBV_bit3_NMCoordinatorBit 0;
BA_ "GenSigTimeoutTime_ESL" SG_ 2654486595 CBV_bit3_NMCoordinatorBit 0;
BA_ "GenSigTimeoutTime_ECM" SG_ 2654486595 CBV_bit3_NMCoordinatorBit 0;
BA_ "GenSigTimeoutTime_DTCM" SG_ 2654486595 CBV_bit3_NMCoordinatorBit 0;
BA_ "GenSigTimeoutTime_DMSM" SG_ 2654486595 CBV_bit3_NMCoordinatorBit 0;
BA_ "GenSigTimeoutTime_BSM" SG_ 2654486595 CBV_bit3_NMCoordinatorBit 0;
BA_ "GenSigTimeoutTime_BCM" SG_ 2654486595 CBV_bit3_NMCoordinatorBit 0;
BA_ "GenSigTimeoutTime_AGSM" SG_ 2654486595 CBV_bit3_NMCoordinatorBit 0;
BA_ "GenSigTimeoutTime_ADCAM" SG_ 2654486595 CBV_bit3_NMCoordinatorBit 0;
BA_ "GenSigTimeoutTime_SGW" SG_ 2654486529 CBV_bit2 0;
BA_ "GenSigTimeoutTime_RFHM" SG_ 2654486529 CBV_bit2 0;
BA_ "GenSigTimeoutTime_MPAD" SG_ 2654486529 CBV_bit2 0;
BA_ "GenSigTimeoutTime_IPC" SG_ 2654486529 CBV_bit2 0;
BA_ "GenSigTimeoutTime_GNMM" SG_ 2654486529 CBV_bit2 0;
BA_ "GenSigTimeoutTime_EVCU2" SG_ 2654486529 CBV_bit2 0;
BA_ "GenSigTimeoutTime_ESL" SG_ 2654486529 CBV_bit2 0;
BA_ "GenSigTimeoutTime_ECM" SG_ 2654486529 CBV_bit2 0;
BA_ "GenSigTimeoutTime_DTCM" SG_ 2654486529 CBV_bit2 0;
BA_ "GenSigTimeoutTime_DMSM" SG_ 2654486529 CBV_bit2 0;
BA_ "GenSigTimeoutTime_BSM" SG_ 2654486529 CBV_bit2 0;
BA_ "GenSigTimeoutTime_BCM" SG_ 2654486529 CBV_bit2 0;
BA_ "GenSigTimeoutTime_AGSM" SG_ 2654486529 CBV_bit2 0;
BA_ "GenSigTimeoutTime_ADCAM" SG_ 2654486529 CBV_bit2 0;
BA_ "GenSigTimeoutTime_SGW" SG_ 2654486595 CBV_bit2 0;
BA_ "GenSigTimeoutTime_RFHM" SG_ 2654486595 CBV_bit2 0;
BA_ "GenSigTimeoutTime_MPAD" SG_ 2654486595 CBV_bit2 0;
BA_ "GenSigTimeoutTime_IPC" SG_ 2654486595 CBV_bit2 0;
BA_ "GenSigTimeoutTime_GNMM" SG_ 2654486595 CBV_bit2 0;
BA_ "GenSigTimeoutTime_EVCU2" SG_ 2654486595 CBV_bit2 0;
BA_ "GenSigTimeoutTime_ESL" SG_ 2654486595 CBV_bit2 0;
BA_ "GenSigTimeoutTime_ECM" SG_ 2654486595 CBV_bit2 0;
BA_ "GenSigTimeoutTime_DTCM" SG_ 2654486595 CBV_bit2 0;
BA_ "GenSigTimeoutTime_DMSM" SG_ 2654486595 CBV_bit2 0;
BA_ "GenSigTimeoutTime_BSM" SG_ 2654486595 CBV_bit2 0;
BA_ "GenSigTimeoutTime_BCM" SG_ 2654486595 CBV_bit2 0;
BA_ "GenSigTimeoutTime_AGSM" SG_ 2654486595 CBV_bit2 0;
BA_ "GenSigTimeoutTime_ADCAM" SG_ 2654486595 CBV_bit2 0;
BA_ "GenSigTimeoutTime_SGW" SG_ 1456 SVI_Request_ext 0;
BA_ "GenSigTimeoutTime_RFHM" SG_ 1456 SVI_Request_ext 0;
BA_ "GenSigTimeoutTime_MPAD" SG_ 1456 SVI_Request_ext 0;
BA_ "GenSigTimeoutTime_GNMM" SG_ 1456 SVI_Request_ext 0;
BA_ "GenSigTimeoutTime_EVCU2" SG_ 1456 SVI_Request_ext 0;
BA_ "GenSigTimeoutTime_ESL" SG_ 1456 SVI_Request_ext 0;
BA_ "GenSigTimeoutTime_ECM" SG_ 1456 SVI_Request_ext 0;
BA_ "GenSigTimeoutTime_DTCM" SG_ 1456 SVI_Request_ext 0;
BA_ "GenSigTimeoutTime_DMSM" SG_ 1456 SVI_Request_ext 0;
BA_ "GenSigTimeoutTime_BSM" SG_ 1456 SVI_Request_ext 0;
BA_ "GenSigTimeoutTime_BCM" SG_ 1456 SVI_Request_ext 0;
BA_ "GenSigTimeoutTime_AGSM" SG_ 1456 SVI_Request_ext 0;
BA_ "GenSigTimeoutTime_ADCAM" SG_ 1456 SVI_Request_ext 0;
BA_ "GenSigSendType" SG_ 1456 SVI_Request_ext 3;
BA_ "GenSigTimeoutTime_SGW" SG_ 1456 SLA_Telltale_Sts 0;
BA_ "GenSigTimeoutTime_RFHM" SG_ 1456 SLA_Telltale_Sts 0;
BA_ "GenSigTimeoutTime_MPAD" SG_ 1456 SLA_Telltale_Sts 0;
BA_ "GenSigTimeoutTime_RFHM" SG_ 1456 SVI_Request 0;
BA_ "GenSigTimeoutTime_MPAD" SG_ 1456 SVI_Request 0;
BA_ "GenSigTimeoutTime_GNMM" SG_ 1456 SVI_Request 0;
BA_ "GenSigTimeoutTime_EVCU2" SG_ 1456 SVI_Request 0;
BA_ "GenSigTimeoutTime_ESL" SG_ 1456 SVI_Request 0;
BA_ "GenSigTimeoutTime_ECM" SG_ 1456 SVI_Request 0;
BA_ "GenSigTimeoutTime_DTCM" SG_ 1456 SVI_Request 0;
BA_ "GenSigTimeoutTime_DMSM" SG_ 1456 SVI_Request 0;
BA_ "GenSigTimeoutTime_BSM" SG_ 1456 SVI_Request 0;
BA_ "GenSigTimeoutTime_BCM" SG_ 1456 SVI_Request 0;
BA_ "GenSigTimeoutTime_AGSM" SG_ 1456 SVI_Request 0;
BA_ "GenSigTimeoutTime_ADCAM" SG_ 1456 SVI_Request 0;
BA_ "GenSigSendType" SG_ 1456 SVI_Request 3;
BA_ "GenSigTimeoutTime_SGW" SG_ 1456 HAS_Inhibit_HMI 0;
BA_ "GenSigTimeoutTime_RFHM" SG_ 1456 HAS_Inhibit_HMI 0;
BA_ "GenSigTimeoutTime_MPAD" SG_ 1456 HAS_Inhibit_HMI 0;
BA_ "GenSigTimeoutTime_GNMM" SG_ 1456 HAS_Inhibit_HMI 0;
BA_ "GenSigTimeoutTime_EVCU2" SG_ 1456 HAS_Inhibit_HMI 0;
BA_ "GenSigTimeoutTime_ESL" SG_ 1456 HAS_Inhibit_HMI 0;
BA_ "GenSigTimeoutTime_ECM" SG_ 1456 HAS_Inhibit_HMI 0;
BA_ "GenSigTimeoutTime_DTCM" SG_ 1456 HAS_Inhibit_HMI 0;
BA_ "GenSigTimeoutTime_DMSM" SG_ 1456 HAS_Inhibit_HMI 0;
BA_ "GenSigTimeoutTime_BSM" SG_ 1456 HAS_Inhibit_HMI 0;
BA_ "GenSigTimeoutTime_BCM" SG_ 1456 HAS_Inhibit_HMI 0;
BA_ "GenSigTimeoutTime_AGSM" SG_ 1456 HAS_Inhibit_HMI 0;
BA_ "GenSigTimeoutTime_ADCAM" SG_ 1456 HAS_Inhibit_HMI 0;
BA_ "GenSigSendType" SG_ 1456 HAS_Inhibit_HMI 4;
BA_ "GenSigTimeoutTime_SGW" SG_ 1456 Driver_Model 0;
BA_ "GenSigTimeoutTime_RFHM" SG_ 1456 Driver_Model 0;
BA_ "GenSigTimeoutTime_MPAD" SG_ 1456 Driver_Model 0;
BA_ "GenSigTimeoutTime_IPC" SG_ 1456 Driver_Model 0;
BA_ "GenSigTimeoutTime_GNMM" SG_ 1456 Driver_Model 0;
BA_ "GenSigTimeoutTime_EVCU2" SG_ 1456 Driver_Model 0;
BA_ "GenSigTimeoutTime_ESL" SG_ 1456 Driver_Model 0;
BA_ "GenSigTimeoutTime_ECM" SG_ 1456 Driver_Model 0;
BA_ "GenSigTimeoutTime_DTCM" SG_ 1456 Driver_Model 0;
BA_ "GenSigTimeoutTime_DMSM" SG_ 1456 Driver_Model 0;
BA_ "GenSigTimeoutTime_BSM" SG_ 1456 Driver_Model 0;
BA_ "GenSigTimeoutTime_BCM" SG_ 1456 Driver_Model 0;
BA_ "GenSigTimeoutTime_AGSM" SG_ 1456 Driver_Model 0;
BA_ "GenSigTimeoutTime_ADCAM" SG_ 1456 Driver_Model 0;
BA_ "GenSigSendType" SG_ 1456 Driver_Model 3;
BA_ "GenSigTimeoutTime_ECM" SG_ 1456 ICA_Blind 0;
BA_ "GenSigTimeoutTime_DTCM" SG_ 1456 ICA_Blind 0;
BA_ "GenSigTimeoutTime_DMSM" SG_ 1456 ICA_Blind 0;
BA_ "GenSigTimeoutTime_BSM" SG_ 1456 ICA_Blind 0;
BA_ "GenSigTimeoutTime_BCM" SG_ 1456 ICA_Blind 0;
BA_ "GenSigTimeoutTime_SGW" SG_ 1452 MessageCounter_TBMS2 0;
BA_ "GenSigTimeoutTime_RFHM" SG_ 1452 MessageCounter_TBMS2 0;
BA_ "GenSigTimeoutTime_IPC" SG_ 1452 MessageCounter_TBMS2 0;
BA_ "GenSigTimeoutTime_GNMM" SG_ 1452 MessageCounter_TBMS2 0;
BA_ "GenSigTimeoutTime_EVCU2" SG_ 1452 MessageCounter_TBMS2 0;
BA_ "GenSigTimeoutTime_ESL" SG_ 1452 MessageCounter_TBMS2 0;
BA_ "GenSigTimeoutTime_ECM" SG_ 1452 MessageCounter_TBMS2 0;
BA_ "GenSigTimeoutTime_DTCM" SG_ 1452 MessageCounter_TBMS2 0;
BA_ "GenSigTimeoutTime_DMSM" SG_ 1452 MessageCounter_TBMS2 0;
BA_ "GenSigTimeoutTime_BSM" SG_ 1452 MessageCounter_TBMS2 0;
BA_ "GenSigTimeoutTime_AGSM" SG_ 1452 MessageCounter_TBMS2 0;
BA_ "GenSigTimeoutTime_ADCAM" SG_ 1452 MessageCounter_TBMS2 0;
BA_ "GenSigTimeoutTime_SGW" SG_ 1452 LTESts 0;
BA_ "GenSigTimeoutTime_RFHM" SG_ 1452 LTESts 0;
BA_ "GenSigTimeoutTime_IPC" SG_ 1452 LTESts 0;
BA_ "GenSigTimeoutTime_GNMM" SG_ 1452 LTESts 0;
BA_ "GenSigTimeoutTime_EVCU2" SG_ 1452 LTESts 0;
BA_ "GenSigTimeoutTime_ESL" SG_ 1452 LTESts 0;
BA_ "GenSigTimeoutTime_ECM" SG_ 1452 LTESts 0;
BA_ "GenSigTimeoutTime_DTCM" SG_ 1452 LTESts 0;
BA_ "GenSigTimeoutTime_DMSM" SG_ 1452 LTESts 0;
BA_ "GenSigTimeoutTime_BSM" SG_ 1452 LTESts 0;
BA_ "GenSigTimeoutTime_BCM" SG_ 1452 LTESts 0;
BA_ "GenSigTimeoutTime_AGSM" SG_ 1452 LTESts 0;
BA_ "GenSigTimeoutTime_ADCAM" SG_ 1452 LTESts 0;
BA_ "GenSigSendType" SG_ 1452 LTESts 3;
BA_ "GenSigTimeoutTime_SGW" SG_ 1452 E_Call_Stat_TBM 0;
BA_ "GenSigTimeoutTime_RFHM" SG_ 1452 E_Call_Stat_TBM 0;
BA_ "GenSigTimeoutTime_DMSM" SG_ 1452 NetConnection 0;
BA_ "GenSigTimeoutTime_BSM" SG_ 1452 NetConnection 0;
BA_ "GenSigTimeoutTime_BCM" SG_ 1452 NetConnection 0;
BA_ "GenSigTimeoutTime_AGSM" SG_ 1452 NetConnection 0;
BA_ "GenSigTimeoutTime_ADCAM" SG_ 1452 NetConnection 0;
BA_ "GenSigSendType" SG_ 1452 NetConnection 3;
BA_ "GenSigTimeoutTime_SGW" SG_ 1456 MessageCounter_ADAS_FD_HMI 0;
BA_ "GenSigTimeoutTime_RFHM" SG_ 1456 MessageCounter_ADAS_FD_HMI 0;
BA_ "GenSigTimeoutTime_MPAD" SG_ 1456 MessageCounter_ADAS_FD_HMI 0;
BA_ "GenSigTimeoutTime_GNMM" SG_ 1456 MessageCounter_ADAS_FD_HMI 0;
BA_ "GenSigTimeoutTime_EVCU2" SG_ 1456 MessageCounter_ADAS_FD_HMI 0;
BA_ "GenSigTimeoutTime_ESL" SG_ 1456 MessageCounter_ADAS_FD_HMI 0;
BA_ "GenSigTimeoutTime_ECM" SG_ 1456 MessageCounter_ADAS_FD_HMI 0;
BA_ "GenSigTimeoutTime_DTCM" SG_ 1456 MessageCounter_ADAS_FD_HMI 0;
BA_ "GenSigTimeoutTime_AGSM" SG_ 1456 MessageCounter_ADAS_FD_HMI 0;
BA_ "GenSigTimeoutTime_RFHM" SG_ 1456 RR_Chime_RqSts 0;
BA_ "GenSigTimeoutTime_MPAD" SG_ 1456 RR_Chime_RqSts 0;
BA_ "GenSigTimeoutTime_IPC" SG_ 1456 RR_Chime_RqSts 0;
BA_ "GenSigTimeoutTime_GNMM" SG_ 1456 RR_Chime_RqSts 0;
BA_ "GenSigTimeoutTime_EVCU2" SG_ 1456 RR_Chime_RqSts 0;
BA_ "GenSigTimeoutTime_ESL" SG_ 1456 RR_Chime_RqSts 0;
BA_ "GenSigTimeoutTime_ECM" SG_ 1456 RR_Chime_RqSts 0;
BA_ "GenSigTimeoutTime_DTCM" SG_ 1456 RR_Chime_RqSts 0;
BA_ "GenSigTimeoutTime_DMSM" SG_ 1456 RR_Chime_RqSts 0;
BA_ "GenSigTimeoutTime_BSM" SG_ 1456 RR_Chime_RqSts 0;
BA_ "GenSigTimeoutTime_AGSM" SG_ 1456 RR_Chime_RqSts 0;
BA_ "GenSigTimeoutTime_ADCAM" SG_ 1456 RR_Chime_RqSts 0;
BA_ "GenSigSendType" SG_ 1456 RR_Chime_RqSts 3;
BA_ "GenSigTimeoutTime_RFHM" SG_ 1456 LR_Chime_RqSts 0;
BA_ "GenSigTimeoutTime_MPAD" SG_ 1456 LR_Chime_RqSts 0;
BA_ "GenSigTimeoutTime_IPC" SG_ 1456 LR_Chime_RqSts 0;
BA_ "GenSigTimeoutTime_GNMM" SG_ 1456 LR_Chime_RqSts 0;
BA_ "GenSigTimeoutTime_EVCU2" SG_ 1456 LR_Chime_RqSts 0;
BA_ "GenSigTimeoutTime_ESL" SG_ 1456 LR_Chime_RqSts 0;
BA_ "GenSigTimeoutTime_ECM" SG_ 1456 LR_Chime_RqSts 0;
BA_ "GenSigTimeoutTime_DTCM" SG_ 1456 LR_Chime_RqSts 0;
BA_ "GenSigTimeoutTime_DMSM" SG_ 1456 LR_Chime_RqSts 0;
BA_ "GenSigTimeoutTime_BSM" SG_ 1456 LR_Chime_RqSts 0;
BA_ "GenSigTimeoutTime_AGSM" SG_ 1456 LR_Chime_RqSts 0;
BA_ "GenSigTimeoutTime_ADCAM" SG_ 1456 LR_Chime_RqSts 0;
BA_ "GenSigSendType" SG_ 1456 LR_Chime_RqSts 3;
BA_ "GenSigTimeoutTime_MPAD" SG_ 1452 E_Call_Stat_TBM 0;
BA_ "GenSigTimeoutTime_SGW" SG_ 1452 U_Call_Stat_TBM 0;
BA_ "GenSigTimeoutTime_RFHM" SG_ 1452 U_Call_Stat_TBM 0;
BA_ "GenSigTimeoutTime_MPAD" SG_ 1452 U_Call_Stat_TBM 0;
BA_ "GenSigTimeoutTime_IPC" SG_ 1452 U_Call_Stat_TBM 0;
BA_ "GenSigTimeoutTime_GNMM" SG_ 1452 U_Call_Stat_TBM 0;
BA_ "GenSigTimeoutTime_EVCU2" SG_ 1452 U_Call_Stat_TBM 0;
BA_ "GenSigTimeoutTime_ESL" SG_ 1452 U_Call_Stat_TBM 0;
BA_ "GenSigTimeoutTime_ECM" SG_ 1452 U_Call_Stat_TBM 0;
BA_ "GenSigTimeoutTime_DTCM" SG_ 1452 U_Call_Stat_TBM 0;
BA_ "GenSigTimeoutTime_DMSM" SG_ 1452 U_Call_Stat_TBM 0;
BA_ "GenSigTimeoutTime_BSM" SG_ 1452 U_Call_Stat_TBM 0;
BA_ "GenSigTimeoutTime_AGSM" SG_ 1452 U_Call_Stat_TBM 0;
BA_ "GenSigTimeoutTime_ADCAM" SG_ 1452 U_Call_Stat_TBM 0;
BA_ "GenSigSendType" SG_ 1452 U_Call_Stat_TBM 3;
BA_ "GenSigTimeoutTime_SGW" SG_ 1452 PrivacyMode 0;
BA_ "GenSigTimeoutTime_RFHM" SG_ 1452 PrivacyMode 0;
BA_ "GenSigTimeoutTime_IPC" SG_ 1452 PrivacyMode 0;
BA_ "GenSigTimeoutTime_GNMM" SG_ 1452 PrivacyMode 0;
BA_ "GenSigTimeoutTime_EVCU2" SG_ 1452 PrivacyMode 0;
BA_ "GenSigTimeoutTime_ESL" SG_ 1452 PrivacyMode 0;
BA_ "GenSigTimeoutTime_ECM" SG_ 1452 PrivacyMode 0;
BA_ "GenSigTimeoutTime_DTCM" SG_ 1452 PrivacyMode 0;
BA_ "GenSigTimeoutTime_DMSM" SG_ 1452 PrivacyMode 0;
BA_ "GenSigTimeoutTime_BSM" SG_ 1452 PrivacyMode 0;
BA_ "GenSigTimeoutTime_BCM" SG_ 1452 PrivacyMode 0;
BA_ "GenSigTimeoutTime_AGSM" SG_ 1452 PrivacyMode 0;
BA_ "GenSigTimeoutTime_ADCAM" SG_ 1452 PrivacyMode 0;
BA_ "GenSigSendType" SG_ 1452 PrivacyMode 3;
BA_ "GenSigTimeoutTime_SGW" SG_ 1452 WiFiSts 0;
BA_ "GenSigTimeoutTime_RFHM" SG_ 1452 WiFiSts 0;
BA_ "GenSigTimeoutTime_IPC" SG_ 1452 WiFiSts 0;
BA_ "GenSigTimeoutTime_GNMM" SG_ 1452 WiFiSts 0;
BA_ "GenSigTimeoutTime_EVCU2" SG_ 1452 WiFiSts 0;
BA_ "GenSigTimeoutTime_ESL" SG_ 1452 WiFiSts 0;
BA_ "GenSigTimeoutTime_ECM" SG_ 1452 WiFiSts 0;
BA_ "GenSigTimeoutTime_DTCM" SG_ 1452 WiFiSts 0;
BA_ "GenSigTimeoutTime_DMSM" SG_ 1452 WiFiSts 0;
BA_ "GenSigTimeoutTime_BSM" SG_ 1452 WiFiSts 0;
BA_ "GenSigTimeoutTime_BCM" SG_ 1452 WiFiSts 0;
BA_ "GenSigTimeoutTime_AGSM" SG_ 1452 WiFiSts 0;
BA_ "GenSigTimeoutTime_ADCAM" SG_ 1452 WiFiSts 0;
BA_ "GenSigSendType" SG_ 1452 WiFiSts 3;
BA_ "GenSigTimeoutTime_SGW" SG_ 1452 NetConnection 0;
BA_ "GenSigTimeoutTime_RFHM" SG_ 1452 NetConnection 0;
BA_ "GenSigTimeoutTime_IPC" SG_ 1452 NetConnection 0;
BA_ "GenSigTimeoutTime_GNMM" SG_ 1452 NetConnection 0;
BA_ "GenSigTimeoutTime_EVCU2" SG_ 1452 NetConnection 0;
BA_ "GenSigTimeoutTime_ESL" SG_ 1452 NetConnection 0;
BA_ "GenSigTimeoutTime_ECM" SG_ 1452 NetConnection 0;
BA_ "GenSigTimeoutTime_DTCM" SG_ 1452 NetConnection 0;
BA_ "GenSigTimeoutTime_SGW" SG_ 1452 SignalStrength 0;
BA_ "GenSigTimeoutTime_RFHM" SG_ 1452 SignalStrength 0;
BA_ "GenSigTimeoutTime_IPC" SG_ 1452 SignalStrength 0;
BA_ "GenSigTimeoutTime_GNMM" SG_ 1452 SignalStrength 0;
BA_ "GenSigTimeoutTime_EVCU2" SG_ 1452 SignalStrength 0;
BA_ "GenSigTimeoutTime_ESL" SG_ 1452 SignalStrength 0;
BA_ "GenSigTimeoutTime_ECM" SG_ 1452 SignalStrength 0;
BA_ "GenSigTimeoutTime_DTCM" SG_ 1452 SignalStrength 0;
BA_ "GenSigTimeoutTime_DMSM" SG_ 1452 SignalStrength 0;
BA_ "GenSigTimeoutTime_BSM" SG_ 1452 SignalStrength 0;
BA_ "GenSigTimeoutTime_BCM" SG_ 1452 SignalStrength 0;
BA_ "GenSigTimeoutTime_AGSM" SG_ 1452 SignalStrength 0;
BA_ "GenSigTimeoutTime_ADCAM" SG_ 1452 SignalStrength 0;
BA_ "GenSigSendType" SG_ 1452 SignalStrength 3;
BA_ "GenSigTimeoutTime_ADCAM" SG_ 1456 Lane_DispPopupSts 0;
BA_ "GenSigSendType" SG_ 1456 Lane_DispPopupSts 3;
BA_ "GenSigTimeoutTime_RFHM" SG_ 1456 Lane_DispPopupSts 0;
BA_ "GenSigTimeoutTime_MPAD" SG_ 1456 Lane_DispPopupSts 0;
BA_ "GenSigTimeoutTime_GNMM" SG_ 1456 Lane_DispPopupSts 0;
BA_ "GenSigTimeoutTime_EVCU2" SG_ 1456 Lane_DispPopupSts 0;
BA_ "GenSigTimeoutTime_ESL" SG_ 1456 Lane_DispPopupSts 0;
BA_ "GenSigTimeoutTime_ECM" SG_ 1456 Lane_DispPopupSts 0;
BA_ "GenSigTimeoutTime_DTCM" SG_ 1456 Lane_DispPopupSts 0;
BA_ "GenSigTimeoutTime_DMSM" SG_ 1456 Lane_DispPopupSts 0;
BA_ "GenSigTimeoutTime_BSM" SG_ 1456 Lane_DispPopupSts 0;
BA_ "GenSigTimeoutTime_BCM" SG_ 1456 Lane_DispPopupSts 0;
BA_ "GenSigTimeoutTime_AGSM" SG_ 1456 Lane_DispPopupSts 0;
BA_ "GenSigTimeoutTime_SGW" SG_ 1456 RRCC_DispPopupSts 0;
BA_ "GenSigTimeoutTime_RFHM" SG_ 1456 RRCC_DispPopupSts 0;
BA_ "GenSigTimeoutTime_MPAD" SG_ 1456 RRCC_DispPopupSts 0;
BA_ "GenSigTimeoutTime_GNMM" SG_ 1456 RRCC_DispPopupSts 0;
BA_ "GenSigTimeoutTime_EVCU2" SG_ 1456 RRCC_DispPopupSts 0;
BA_ "GenSigTimeoutTime_ESL" SG_ 1456 RRCC_DispPopupSts 0;
BA_ "GenSigTimeoutTime_ECM" SG_ 1456 RRCC_DispPopupSts 0;
BA_ "GenSigTimeoutTime_DTCM" SG_ 1456 RRCC_DispPopupSts 0;
BA_ "GenSigTimeoutTime_DMSM" SG_ 1456 RRCC_DispPopupSts 0;
BA_ "GenSigTimeoutTime_BSM" SG_ 1456 RRCC_DispPopupSts 0;
BA_ "GenSigTimeoutTime_BCM" SG_ 1456 RRCC_DispPopupSts 0;
BA_ "GenSigTimeoutTime_AGSM" SG_ 1456 RRCC_DispPopupSts 0;
BA_ "GenSigTimeoutTime_ADCAM" SG_ 1456 RRCC_DispPopupSts 0;
BA_ "GenSigSendType" SG_ 1456 RRCC_DispPopupSts 3;
BA_ "GenSigTimeoutTime_GNMM" SG_ 1456 SLA_Telltale_Sts 0;
BA_ "GenSigTimeoutTime_EVCU2" SG_ 1456 SLA_Telltale_Sts 0;
BA_ "GenSigTimeoutTime_ESL" SG_ 1456 SLA_Telltale_Sts 0;
BA_ "GenSigTimeoutTime_ECM" SG_ 1456 SLA_Telltale_Sts 0;
BA_ "GenSigTimeoutTime_DTCM" SG_ 1456 SLA_Telltale_Sts 0;
BA_ "GenSigTimeoutTime_DMSM" SG_ 1456 SLA_Telltale_Sts 0;
BA_ "GenSigTimeoutTime_BSM" SG_ 1456 SLA_Telltale_Sts 0;
BA_ "GenSigTimeoutTime_BCM" SG_ 1456 SLA_Telltale_Sts 0;
BA_ "GenSigTimeoutTime_AGSM" SG_ 1456 SLA_Telltale_Sts 0;
BA_ "GenSigTimeoutTime_ADCAM" SG_ 1456 SLA_Telltale_Sts 0;
BA_ "GenSigSendType" SG_ 1456 SLA_Telltale_Sts 3;
BA_ "GenSigTimeoutTime_RFHM" SG_ 1456 Set_Speed_MPH 0;
BA_ "GenSigTimeoutTime_MPAD" SG_ 1456 Set_Speed_MPH 0;
BA_ "GenSigTimeoutTime_GNMM" SG_ 1456 Set_Speed_MPH 0;
BA_ "GenSigTimeoutTime_EVCU2" SG_ 1456 Set_Speed_MPH 0;
BA_ "GenSigTimeoutTime_ESL" SG_ 1456 Set_Speed_MPH 0;
BA_ "GenSigTimeoutTime_ECM" SG_ 1456 Set_Speed_MPH 0;
BA_ "GenSigTimeoutTime_DTCM" SG_ 1456 Set_Speed_MPH 0;
BA_ "GenSigTimeoutTime_DMSM" SG_ 1456 Set_Speed_MPH 0;
BA_ "GenSigTimeoutTime_BSM" SG_ 1456 Set_Speed_MPH 0;
BA_ "GenSigTimeoutTime_BCM" SG_ 1456 Set_Speed_MPH 0;
BA_ "GenSigTimeoutTime_AGSM" SG_ 1456 Set_Speed_MPH 0;
BA_ "GenSigTimeoutTime_ADCAM" SG_ 1456 Set_Speed_MPH 0;
BA_ "GenSigSendType" SG_ 1456 Set_Speed_MPH 3;
BA_ "GenSigTimeoutTime_RFHM" SG_ 1456 Set_Speed_KPH 0;
BA_ "GenSigTimeoutTime_MPAD" SG_ 1456 Set_Speed_KPH 0;
BA_ "GenSigTimeoutTime_GNMM" SG_ 1456 Set_Speed_KPH 0;
BA_ "GenSigTimeoutTime_EVCU2" SG_ 1456 Set_Speed_KPH 0;
BA_ "GenSigTimeoutTime_ESL" SG_ 1456 Set_Speed_KPH 0;
BA_ "GenSigTimeoutTime_ECM" SG_ 1456 Set_Speed_KPH 0;
BA_ "GenSigTimeoutTime_SGW" SG_ 2651930659 Digit_11_TBM 0;
BA_ "GenSigTimeoutTime_RFHM" SG_ 2651930659 Digit_11_TBM 0;
BA_ "GenSigTimeoutTime_MPAD" SG_ 2651930659 Digit_11_TBM 0;
BA_ "GenSigTimeoutTime_IPC" SG_ 2651930659 Digit_11_TBM 0;
BA_ "GenSigTimeoutTime_GNMM" SG_ 2651930659 Digit_11_TBM 0;
BA_ "GenSigTimeoutTime_EVCU2" SG_ 2651930659 Digit_11_TBM 0;
BA_ "GenSigTimeoutTime_ESL" SG_ 2651930659 Digit_11_TBM 0;
BA_ "GenSigTimeoutTime_ECM" SG_ 2651930659 Digit_11_TBM 0;
BA_ "GenSigTimeoutTime_DTCM" SG_ 2651930659 Digit_11_TBM 0;
BA_ "GenSigTimeoutTime_DMSM" SG_ 2651930659 Digit_11_TBM 0;
BA_ "GenSigTimeoutTime_BSM" SG_ 2651930659 Digit_11_TBM 0;
BA_ "GenSigTimeoutTime_AGSM" SG_ 2651930659 Digit_11_TBM 0;
BA_ "GenSigTimeoutTime_ADCAM" SG_ 2651930659 Digit_11_TBM 0;
BA_ "GenSigTimeoutTime_SGW" SG_ 2651930659 Digit_10_TBM 0;
BA_ "GenSigTimeoutTime_RFHM" SG_ 2651930659 Digit_10_TBM 0;
BA_ "GenSigTimeoutTime_MPAD" SG_ 2651930659 Digit_10_TBM 0;
BA_ "GenSigTimeoutTime_IPC" SG_ 2651930659 Digit_10_TBM 0;
BA_ "GenSigTimeoutTime_GNMM" SG_ 2651930659 Digit_10_TBM 0;
BA_ "GenSigTimeoutTime_EVCU2" SG_ 2651930659 Digit_10_TBM 0;
BA_ "GenSigTimeoutTime_ESL" SG_ 2651930659 Digit_10_TBM 0;
BA_ "GenSigTimeoutTime_ECM" SG_ 2651930659 Digit_10_TBM 0;
BA_ "GenSigTimeoutTime_DTCM" SG_ 2651930659 Digit_10_TBM 0;
BA_ "GenSigTimeoutTime_DMSM" SG_ 2651930659 Digit_10_TBM 0;
BA_ "GenSigTimeoutTime_BSM" SG_ 2651930659 Digit_10_TBM 0;
BA_ "GenSigTimeoutTime_AGSM" SG_ 2651930659 Digit_10_TBM 0;
BA_ "GenSigTimeoutTime_ADCAM" SG_ 2651930659 Digit_10_TBM 0;
BA_ "GenSigTimeoutTime_SGW" SG_ 2651930659 Digit_06_TBM 0;
BA_ "GenSigTimeoutTime_RFHM" SG_ 2651930659 Digit_06_TBM 0;
BA_ "GenSigTimeoutTime_MPAD" SG_ 2651930659 Digit_06_TBM 0;
BA_ "GenSigTimeoutTime_IPC" SG_ 2651930659 Digit_06_TBM 0;
BA_ "GenSigTimeoutTime_GNMM" SG_ 2651930659 Digit_06_TBM 0;
BA_ "GenSigTimeoutTime_EVCU2" SG_ 2651930659 Digit_06_TBM 0;
BA_ "GenSigTimeoutTime_ESL" SG_ 2651930659 Digit_06_TBM 0;
BA_ "GenSigTimeoutTime_ECM" SG_ 2651930659 Digit_06_TBM 0;
BA_ "GenSigTimeoutTime_DTCM" SG_ 2651930659 Digit_06_TBM 0;
BA_ "GenSigTimeoutTime_DMSM" SG_ 2651930659 Digit_06_TBM 0;
BA_ "GenSigTimeoutTime_BSM" SG_ 2651930659 Digit_06_TBM 0;
BA_ "GenSigTimeoutTime_AGSM" SG_ 2651930659 Digit_06_TBM 0;
BA_ "GenSigTimeoutTime_ADCAM" SG_ 2651930659 Digit_06_TBM 0;
BA_ "GenSigTimeoutTime_SGW" SG_ 2651930659 Digit_07_TBM 0;
BA_ "GenSigTimeoutTime_RFHM" SG_ 2651930659 Digit_07_TBM 0;
BA_ "GenSigTimeoutTime_MPAD" SG_ 2651930659 Digit_07_TBM 0;
BA_ "GenSigTimeoutTime_IPC" SG_ 2651930659 Digit_07_TBM 0;
BA_ "GenSigTimeoutTime_GNMM" SG_ 2651930659 Digit_07_TBM 0;
BA_ "GenSigTimeoutTime_EVCU2" SG_ 2651930659 Digit_07_TBM 0;
BA_ "GenSigTimeoutTime_ESL" SG_ 2651930659 Digit_07_TBM 0;
BA_ "GenSigTimeoutTime_ECM" SG_ 2651930659 Digit_07_TBM 0;
BA_ "GenSigTimeoutTime_DTCM" SG_ 2651930659 Digit_07_TBM 0;
BA_ "GenSigTimeoutTime_DMSM" SG_ 2651930659 Digit_07_TBM 0;
BA_ "GenSigTimeoutTime_BSM" SG_ 2651930659 Digit_07_TBM 0;
BA_ "GenSigTimeoutTime_AGSM" SG_ 2651930659 Digit_07_TBM 0;
BA_ "GenSigTimeoutTime_ADCAM" SG_ 2651930659 Digit_07_TBM 0;
BA_ "GenSigTimeoutTime_SGW" SG_ 2651930659 Digit_08_TBM 0;
BA_ "GenSigTimeoutTime_RFHM" SG_ 2651930659 Digit_08_TBM 0;
BA_ "GenSigTimeoutTime_MPAD" SG_ 2651930659 Digit_08_TBM 0;
BA_ "GenSigTimeoutTime_IPC" SG_ 2651930659 Digit_08_TBM 0;
BA_ "GenSigTimeoutTime_GNMM" SG_ 2651930659 Digit_08_TBM 0;
BA_ "GenSigTimeoutTime_EVCU2" SG_ 2651930659 Digit_08_TBM 0;
BA_ "GenSigTimeoutTime_ESL" SG_ 2651930659 Digit_08_TBM 0;
BA_ "GenSigTimeoutTime_ECM" SG_ 2651930659 Digit_08_TBM 0;
BA_ "GenSigTimeoutTime_DTCM" SG_ 2651930659 Digit_08_TBM 0;
BA_ "GenSigTimeoutTime_DMSM" SG_ 2651930659 Digit_08_TBM 0;
BA_ "GenSigTimeoutTime_BSM" SG_ 2651930659 Digit_08_TBM 0;
BA_ "GenSigTimeoutTime_AGSM" SG_ 2651930659 Digit_08_TBM 0;
BA_ "GenSigTimeoutTime_ADCAM" SG_ 2651930659 Digit_08_TBM 0;
BA_ "GenSigTimeoutTime_SGW" SG_ 2651930659 Digit_09_TBM 0;
BA_ "GenSigTimeoutTime_RFHM" SG_ 2651930659 Digit_09_TBM 0;
BA_ "GenSigTimeoutTime_MPAD" SG_ 2651930659 Digit_09_TBM 0;
BA_ "GenSigTimeoutTime_IPC" SG_ 2651930659 Digit_09_TBM 0;
BA_ "GenSigTimeoutTime_GNMM" SG_ 2651930659 Digit_09_TBM 0;
BA_ "GenSigTimeoutTime_EVCU2" SG_ 2651930659 Digit_09_TBM 0;
BA_ "GenSigTimeoutTime_ESL" SG_ 2651930659 Digit_09_TBM 0;
BA_ "GenSigTimeoutTime_ECM" SG_ 2651930659 Digit_09_TBM 0;
BA_ "GenSigTimeoutTime_DTCM" SG_ 2651930659 Digit_09_TBM 0;
BA_ "GenSigTimeoutTime_DMSM" SG_ 2651930659 Digit_09_TBM 0;
BA_ "GenSigTimeoutTime_BSM" SG_ 2651930659 Digit_09_TBM 0;
BA_ "GenSigTimeoutTime_AGSM" SG_ 2651930659 Digit_09_TBM 0;
BA_ "GenSigTimeoutTime_ADCAM" SG_ 2651930659 Digit_09_TBM 0;
BA_ "GenSigTimeoutTime_SGW" SG_ 2651930659 Digit_01_TBM 0;
BA_ "GenSigTimeoutTime_RFHM" SG_ 2651930659 Digit_01_TBM 0;
BA_ "GenSigTimeoutTime_MPAD" SG_ 2651930659 Digit_01_TBM 0;
BA_ "GenSigTimeoutTime_IPC" SG_ 2651930659 Digit_01_TBM 0;
BA_ "GenSigTimeoutTime_GNMM" SG_ 2651930659 Digit_01_TBM 0;
BA_ "GenSigTimeoutTime_EVCU2" SG_ 2651930659 Digit_01_TBM 0;
BA_ "GenSigTimeoutTime_ESL" SG_ 2651930659 Digit_01_TBM 0;
BA_ "GenSigTimeoutTime_ECM" SG_ 2651930659 Digit_01_TBM 0;
BA_ "GenSigTimeoutTime_DTCM" SG_ 2651930659 Digit_01_TBM 0;
BA_ "GenSigTimeoutTime_DMSM" SG_ 2651930659 Digit_01_TBM 0;
BA_ "GenSigTimeoutTime_BSM" SG_ 2651930659 Digit_01_TBM 0;
BA_ "GenSigTimeoutTime_AGSM" SG_ 2651930659 Digit_01_TBM 0;
BA_ "GenSigTimeoutTime_ADCAM" SG_ 2651930659 Digit_01_TBM 0;
BA_ "GenSigSendType" SG_ 2651930659 Digit_01_TBM 1;
BA_ "GenSigTimeoutTime_SGW" SG_ 2651930659 Digit_02_TBM 0;
BA_ "GenSigTimeoutTime_RFHM" SG_ 2651930659 Digit_02_TBM 0;
BA_ "GenSigTimeoutTime_MPAD" SG_ 2651930659 Digit_02_TBM 0;
BA_ "GenSigTimeoutTime_IPC" SG_ 2651930659 Digit_02_TBM 0;
BA_ "GenSigTimeoutTime_GNMM" SG_ 2651930659 Digit_02_TBM 0;
BA_ "GenSigTimeoutTime_EVCU2" SG_ 2651930659 Digit_02_TBM 0;
BA_ "GenSigTimeoutTime_ESL" SG_ 2651930659 Digit_02_TBM 0;
BA_ "GenSigTimeoutTime_ECM" SG_ 2651930659 Digit_02_TBM 0;
BA_ "GenSigTimeoutTime_DTCM" SG_ 2651930659 Digit_02_TBM 0;
BA_ "GenSigTimeoutTime_DMSM" SG_ 2651930659 Digit_02_TBM 0;
BA_ "GenSigTimeoutTime_BSM" SG_ 2651930659 Digit_02_TBM 0;
BA_ "GenSigTimeoutTime_AGSM" SG_ 2651930659 Digit_02_TBM 0;
BA_ "GenSigTimeoutTime_ADCAM" SG_ 2651930659 Digit_02_TBM 0;
BA_ "GenSigTimeoutTime_SGW" SG_ 2651930659 Digit_03_TBM 0;
BA_ "GenSigTimeoutTime_RFHM" SG_ 2651930659 Digit_03_TBM 0;
BA_ "GenSigTimeoutTime_MPAD" SG_ 2651930659 Digit_03_TBM 0;
BA_ "GenSigTimeoutTime_IPC" SG_ 2651930659 Digit_03_TBM 0;
BA_ "GenSigTimeoutTime_GNMM" SG_ 2651930659 Digit_03_TBM 0;
BA_ "GenSigTimeoutTime_EVCU2" SG_ 2651930659 Digit_03_TBM 0;
BA_ "GenSigTimeoutTime_ESL" SG_ 2651930659 Digit_03_TBM 0;
BA_ "GenSigTimeoutTime_ECM" SG_ 2651930659 Digit_03_TBM 0;
BA_ "GenSigTimeoutTime_DTCM" SG_ 2651930659 Digit_03_TBM 0;
BA_ "GenSigTimeoutTime_DMSM" SG_ 2651930659 Digit_03_TBM 0;
BA_ "GenSigTimeoutTime_BSM" SG_ 2651930659 Digit_03_TBM 0;
BA_ "GenSigTimeoutTime_AGSM" SG_ 2651930659 Digit_03_TBM 0;
BA_ "GenSigTimeoutTime_ADCAM" SG_ 2651930659 Digit_03_TBM 0;
BA_ "GenSigTimeoutTime_SGW" SG_ 2651930659 Digit_04_TBM 0;
BA_ "GenSigTimeoutTime_RFHM" SG_ 2651930659 Digit_04_TBM 0;
BA_ "GenSigTimeoutTime_MPAD" SG_ 2651930659 Digit_04_TBM 0;
BA_ "GenSigTimeoutTime_IPC" SG_ 2651930659 Digit_04_TBM 0;
BA_ "GenSigTimeoutTime_GNMM" SG_ 2651930659 Digit_04_TBM 0;
BA_ "GenSigTimeoutTime_EVCU2" SG_ 2651930659 Digit_04_TBM 0;
BA_ "GenSigTimeoutTime_ESL" SG_ 2651930659 Digit_04_TBM 0;
BA_ "GenSigTimeoutTime_ECM" SG_ 2651930659 Digit_04_TBM 0;
BA_ "GenSigTimeoutTime_DTCM" SG_ 2651930659 Digit_04_TBM 0;
BA_ "GenSigTimeoutTime_DMSM" SG_ 2651930659 Digit_04_TBM 0;
BA_ "GenSigTimeoutTime_BSM" SG_ 2651930659 Digit_04_TBM 0;
BA_ "GenSigTimeoutTime_AGSM" SG_ 2651930659 Digit_04_TBM 0;
BA_ "GenSigTimeoutTime_ADCAM" SG_ 2651930659 Digit_04_TBM 0;
BA_ "GenSigTimeoutTime_SGW" SG_ 2651930659 Digit_05_TBM 0;
BA_ "GenSigTimeoutTime_RFHM" SG_ 2651930659 Digit_05_TBM 0;
BA_ "GenSigTimeoutTime_MPAD" SG_ 2651930659 Digit_05_TBM 0;
BA_ "GenSigTimeoutTime_IPC" SG_ 2651930659 Digit_05_TBM 0;
BA_ "GenSigTimeoutTime_GNMM" SG_ 2651930659 Digit_05_TBM 0;
BA_ "GenSigTimeoutTime_EVCU2" SG_ 2651930659 Digit_05_TBM 0;
BA_ "GenSigTimeoutTime_ESL" SG_ 2651930659 Digit_05_TBM 0;
BA_ "GenSigTimeoutTime_ECM" SG_ 2651930659 Digit_05_TBM 0;
BA_ "GenSigTimeoutTime_DTCM" SG_ 2651930659 Digit_05_TBM 0;
BA_ "GenSigTimeoutTime_DMSM" SG_ 2651930659 Digit_05_TBM 0;
BA_ "GenSigTimeoutTime_BSM" SG_ 2651930659 Digit_05_TBM 0;
BA_ "GenSigTimeoutTime_AGSM" SG_ 2651930659 Digit_05_TBM 0;
BA_ "GenSigTimeoutTime_ADCAM" SG_ 2651930659 Digit_05_TBM 0;
BA_ "GenSigTimeoutTime_DTCM" SG_ 1456 Set_Speed_KPH 0;
BA_ "GenSigTimeoutTime_DMSM" SG_ 1456 Set_Speed_KPH 0;
BA_ "GenSigTimeoutTime_BSM" SG_ 1456 Set_Speed_KPH 0;
BA_ "GenSigTimeoutTime_BCM" SG_ 1456 Set_Speed_KPH 0;
BA_ "GenSigTimeoutTime_AGSM" SG_ 1456 Set_Speed_KPH 0;
BA_ "GenSigTimeoutTime_ADCAM" SG_ 1456 Set_Speed_KPH 0;
BA_ "GenSigSendType" SG_ 1456 Set_Speed_KPH 3;
BA_ "GenSigTimeoutTime_RFHM" SG_ 1456 RF_Chime_RqSts 0;
BA_ "GenSigTimeoutTime_MPAD" SG_ 1456 RF_Chime_RqSts 0;
BA_ "GenSigTimeoutTime_IPC" SG_ 1456 RF_Chime_RqSts 0;
BA_ "GenSigTimeoutTime_GNMM" SG_ 1456 RF_Chime_RqSts 0;
BA_ "GenSigTimeoutTime_EVCU2" SG_ 1456 RF_Chime_RqSts 0;
BA_ "GenSigTimeoutTime_ESL" SG_ 1456 RF_Chime_RqSts 0;
BA_ "GenSigTimeoutTime_ECM" SG_ 1456 RF_Chime_RqSts 0;
BA_ "GenSigTimeoutTime_DTCM" SG_ 1456 RF_Chime_RqSts 0;
BA_ "GenSigTimeoutTime_DMSM" SG_ 1456 RF_Chime_RqSts 0;
BA_ "GenSigTimeoutTime_BSM" SG_ 1456 RF_Chime_RqSts 0;
BA_ "GenSigTimeoutTime_AGSM" SG_ 1456 RF_Chime_RqSts 0;
BA_ "GenSigTimeoutTime_ADCAM" SG_ 1456 RF_Chime_RqSts 0;
BA_ "GenSigSendType" SG_ 1456 RF_Chime_RqSts 3;
BA_ "GenSigTimeoutTime_SGW" SG_ 1456 ICA_Blind 0;
BA_ "GenSigTimeoutTime_RFHM" SG_ 1456 ICA_Blind 0;
BA_ "GenSigTimeoutTime_MPAD" SG_ 1456 ICA_Blind 0;
BA_ "GenSigTimeoutTime_GNMM" SG_ 1456 ICA_Blind 0;
BA_ "GenSigTimeoutTime_EVCU2" SG_ 1456 ICA_Blind 0;
BA_ "GenSigTimeoutTime_ESL" SG_ 1456 ICA_Blind 0;
BA_ "GenSigTimeoutTime_RFHM" SG_ 1456 Lane_DisplaySts_Left 0;
BA_ "GenSigTimeoutTime_MPAD" SG_ 1456 Lane_DisplaySts_Left 0;
BA_ "GenSigTimeoutTime_GNMM" SG_ 1456 Lane_DisplaySts_Left 0;
BA_ "GenSigTimeoutTime_EVCU2" SG_ 1456 Lane_DisplaySts_Left 0;
BA_ "GenSigTimeoutTime_ESL" SG_ 1456 Lane_DisplaySts_Left 0;
BA_ "GenSigTimeoutTime_ECM" SG_ 1456 Lane_DisplaySts_Left 0;
BA_ "GenSigTimeoutTime_DTCM" SG_ 1456 Lane_DisplaySts_Left 0;
BA_ "GenSigTimeoutTime_DMSM" SG_ 1456 Lane_DisplaySts_Left 0;
BA_ "GenSigTimeoutTime_BSM" SG_ 1456 Lane_DisplaySts_Left 0;
BA_ "GenSigTimeoutTime_BCM" SG_ 1456 Lane_DisplaySts_Left 0;
BA_ "GenSigTimeoutTime_AGSM" SG_ 1456 Lane_DisplaySts_Left 0;
BA_ "GenSigTimeoutTime_ADCAM" SG_ 1456 Lane_DisplaySts_Left 0;
BA_ "GenSigSendType" SG_ 1456 Lane_DisplaySts_Left 3;
BA_ "GenSigTimeoutTime_SGW" SG_ 1456 PEB_Setting_Avail 0;
BA_ "GenSigTimeoutTime_RFHM" SG_ 1456 PEB_Setting_Avail 0;
BA_ "GenSigTimeoutTime_MPAD" SG_ 1456 PEB_Setting_Avail 0;
BA_ "GenSigTimeoutTime_IPC" SG_ 1456 PEB_Setting_Avail 0;
BA_ "GenSigTimeoutTime_GNMM" SG_ 1456 PEB_Setting_Avail 0;
BA_ "GenSigTimeoutTime_EVCU2" SG_ 1456 PEB_Setting_Avail 0;
BA_ "GenSigTimeoutTime_ESL" SG_ 1456 PEB_Setting_Avail 0;
BA_ "GenSigTimeoutTime_ECM" SG_ 1456 PEB_Setting_Avail 0;
BA_ "GenSigTimeoutTime_DTCM" SG_ 1456 PEB_Setting_Avail 0;
BA_ "GenSigTimeoutTime_DMSM" SG_ 1456 PEB_Setting_Avail 0;
BA_ "GenSigTimeoutTime_BSM" SG_ 1456 PEB_Setting_Avail 0;
BA_ "GenSigTimeoutTime_BCM" SG_ 1456 PEB_Setting_Avail 0;
BA_ "GenSigTimeoutTime_AGSM" SG_ 1456 PEB_Setting_Avail 0;
BA_ "GenSigTimeoutTime_ADCAM" SG_ 1456 PEB_Setting_Avail 0;
BA_ "GenSigSendType" SG_ 1456 PEB_Setting_Avail 3;
BA_ "GenSigTimeoutTime_SGW" SG_ 1456 NCC_FailSts 0;
BA_ "GenSigTimeoutTime_RFHM" SG_ 1456 NCC_FailSts 0;
BA_ "GenSigTimeoutTime_MPAD" SG_ 1456 NCC_FailSts 0;
BA_ "GenSigTimeoutTime_IPC" SG_ 1456 NCC_FailSts 0;
BA_ "GenSigTimeoutTime_GNMM" SG_ 1456 NCC_FailSts 0;
BA_ "GenSigTimeoutTime_EVCU2" SG_ 1456 NCC_FailSts 0;
BA_ "GenSigTimeoutTime_ESL" SG_ 1456 NCC_FailSts 0;
BA_ "GenSigTimeoutTime_ECM" SG_ 1456 NCC_FailSts 0;
BA_ "GenSigTimeoutTime_DTCM" SG_ 1456 NCC_FailSts 0;
BA_ "GenSigTimeoutTime_DMSM" SG_ 1456 NCC_FailSts 0;
BA_ "GenSigTimeoutTime_BSM" SG_ 1456 NCC_FailSts 0;
BA_ "GenSigTimeoutTime_BCM" SG_ 1456 NCC_FailSts 0;
BA_ "GenSigTimeoutTime_AGSM" SG_ 1456 NCC_FailSts 0;
BA_ "GenSigTimeoutTime_ADCAM" SG_ 1456 NCC_FailSts 0;
BA_ "GenSigSendType" SG_ 1456 NCC_FailSts 3;
BA_ "GenSigTimeoutTime_RFHM" SG_ 1456 LKA_Status 0;
BA_ "GenSigTimeoutTime_MPAD" SG_ 1456 LKA_Status 0;
BA_ "GenSigTimeoutTime_GNMM" SG_ 1456 LKA_Status 0;
BA_ "GenSigTimeoutTime_EVCU2" SG_ 1456 LKA_Status 0;
BA_ "GenSigTimeoutTime_ESL" SG_ 1456 LKA_Status 0;
BA_ "GenSigTimeoutTime_ECM" SG_ 1456 LKA_Status 0;
BA_ "GenSigTimeoutTime_DTCM" SG_ 1456 LKA_Status 0;
BA_ "GenSigTimeoutTime_DMSM" SG_ 1456 LKA_Status 0;
BA_ "GenSigTimeoutTime_BSM" SG_ 1456 LKA_Status 0;
BA_ "GenSigTimeoutTime_BCM" SG_ 1456 LKA_Status 0;
BA_ "GenSigTimeoutTime_AGSM" SG_ 1456 LKA_Status 0;
BA_ "GenSigTimeoutTime_ADCAM" SG_ 1456 LKA_Status 0;
BA_ "GenSigSendType" SG_ 1456 LKA_Status 3;
BA_ "GenSigTimeoutTime_SGW" SG_ 1456 LKA_LEDControlSts 0;
BA_ "GenSigTimeoutTime_RFHM" SG_ 1456 LKA_LEDControlSts 0;
BA_ "GenSigTimeoutTime_MPAD" SG_ 1456 LKA_LEDControlSts 0;
BA_ "GenSigTimeoutTime_IPC" SG_ 1456 LKA_LEDControlSts 0;
BA_ "GenSigTimeoutTime_GNMM" SG_ 1456 LKA_LEDControlSts 0;
BA_ "GenSigTimeoutTime_EVCU2" SG_ 1456 LKA_LEDControlSts 0;
BA_ "GenSigTimeoutTime_ESL" SG_ 1456 LKA_LEDControlSts 0;
BA_ "GenSigTimeoutTime_ECM" SG_ 1456 LKA_LEDControlSts 0;
BA_ "GenSigTimeoutTime_DTCM" SG_ 1456 LKA_LEDControlSts 0;
BA_ "GenSigTimeoutTime_DMSM" SG_ 1456 LKA_LEDControlSts 0;
BA_ "GenSigTimeoutTime_BSM" SG_ 1456 LKA_LEDControlSts 0;
BA_ "GenSigTimeoutTime_AGSM" SG_ 1456 LKA_LEDControlSts 0;
BA_ "GenSigTimeoutTime_ADCAM" SG_ 1456 LKA_LEDControlSts 0;
BA_ "GenSigSendType" SG_ 1456 LKA_LEDControlSts 3;
BA_ "GenSigTimeoutTime_SGW" SG_ 1456 LKA_FailSts 0;
BA_ "GenSigTimeoutTime_RFHM" SG_ 1456 LKA_FailSts 0;
BA_ "GenSigTimeoutTime_MPAD" SG_ 1456 LKA_FailSts 0;
BA_ "GenSigTimeoutTime_GNMM" SG_ 1456 LKA_FailSts 0;
BA_ "GenSigTimeoutTime_EVCU2" SG_ 1456 LKA_FailSts 0;
BA_ "GenSigTimeoutTime_ESL" SG_ 1456 LKA_FailSts 0;
BA_ "GenSigTimeoutTime_ECM" SG_ 1456 LKA_FailSts 0;
BA_ "GenSigTimeoutTime_DTCM" SG_ 1456 LKA_FailSts 0;
BA_ "GenSigTimeoutTime_DMSM" SG_ 1456 LKA_FailSts 0;
BA_ "GenSigTimeoutTime_BSM" SG_ 1456 LKA_FailSts 0;
BA_ "GenSigTimeoutTime_BCM" SG_ 1456 LKA_FailSts 0;
BA_ "GenSigTimeoutTime_AGSM" SG_ 1456 LKA_FailSts 0;
BA_ "GenSigTimeoutTime_ADCAM" SG_ 1456 LKA_FailSts 0;
BA_ "GenSigSendType" SG_ 1456 LKA_FailSts 3;
BA_ "GenSigTimeoutTime_SGW" SG_ 1456 LKA_Blind 0;
BA_ "GenSigTimeoutTime_RFHM" SG_ 1456 LKA_Blind 0;
BA_ "GenSigTimeoutTime_MPAD" SG_ 1456 LKA_Blind 0;
BA_ "GenSigTimeoutTime_GNMM" SG_ 1456 LKA_Blind 0;
BA_ "GenSigTimeoutTime_EVCU2" SG_ 1456 LKA_Blind 0;
BA_ "GenSigTimeoutTime_ESL" SG_ 1456 LKA_Blind 0;
BA_ "GenSigTimeoutTime_ECM" SG_ 1456 LKA_Blind 0;
BA_ "GenSigTimeoutTime_DTCM" SG_ 1456 LKA_Blind 0;
BA_ "GenSigTimeoutTime_DMSM" SG_ 1456 LKA_Blind 0;
BA_ "GenSigTimeoutTime_BSM" SG_ 1456 LKA_Blind 0;
BA_ "GenSigTimeoutTime_BCM" SG_ 1456 LKA_Blind 0;
BA_ "GenSigTimeoutTime_AGSM" SG_ 1456 LKA_Blind 0;
BA_ "GenSigTimeoutTime_ADCAM" SG_ 1456 LKA_Blind 0;
BA_ "GenSigSendType" SG_ 1456 LKA_Blind 3;
BA_ "GenSigTimeoutTime_RFHM" SG_ 1456 LF_Chime_RqSts 0;
BA_ "GenSigTimeoutTime_MPAD" SG_ 1456 LF_Chime_RqSts 0;
BA_ "GenSigTimeoutTime_IPC" SG_ 1456 LF_Chime_RqSts 0;
BA_ "GenSigTimeoutTime_GNMM" SG_ 1456 LF_Chime_RqSts 0;
BA_ "GenSigTimeoutTime_EVCU2" SG_ 1456 LF_Chime_RqSts 0;
BA_ "GenSigTimeoutTime_ESL" SG_ 1456 LF_Chime_RqSts 0;
BA_ "GenSigTimeoutTime_ECM" SG_ 1456 LF_Chime_RqSts 0;
BA_ "GenSigTimeoutTime_DTCM" SG_ 1456 LF_Chime_RqSts 0;
BA_ "GenSigTimeoutTime_DMSM" SG_ 1456 LF_Chime_RqSts 0;
BA_ "GenSigTimeoutTime_BSM" SG_ 1456 LF_Chime_RqSts 0;
BA_ "GenSigTimeoutTime_AGSM" SG_ 1456 LF_Chime_RqSts 0;
BA_ "GenSigTimeoutTime_ADCAM" SG_ 1456 LF_Chime_RqSts 0;
BA_ "GenSigSendType" SG_ 1456 LF_Chime_RqSts 3;
BA_ "GenSigTimeoutTime_RFHM" SG_ 1456 Lane_DisplaySts_Right 0;
BA_ "GenSigTimeoutTime_MPAD" SG_ 1456 Lane_DisplaySts_Right 0;
BA_ "GenSigTimeoutTime_GNMM" SG_ 1456 Lane_DisplaySts_Right 0;
BA_ "GenSigTimeoutTime_EVCU2" SG_ 1456 Lane_DisplaySts_Right 0;
BA_ "GenSigTimeoutTime_ESL" SG_ 1456 Lane_DisplaySts_Right 0;
BA_ "GenSigTimeoutTime_ECM" SG_ 1456 Lane_DisplaySts_Right 0;
BA_ "GenSigTimeoutTime_DTCM" SG_ 1456 Lane_DisplaySts_Right 0;
BA_ "GenSigTimeoutTime_DMSM" SG_ 1456 Lane_DisplaySts_Right 0;
BA_ "GenSigTimeoutTime_BSM" SG_ 1456 Lane_DisplaySts_Right 0;
BA_ "GenSigTimeoutTime_BCM" SG_ 1456 Lane_DisplaySts_Right 0;
BA_ "GenSigTimeoutTime_AGSM" SG_ 1456 Lane_DisplaySts_Right 0;
BA_ "GenSigTimeoutTime_ADCAM" SG_ 1456 Lane_DisplaySts_Right 0;
BA_ "GenSigSendType" SG_ 1456 Lane_DisplaySts_Right 3;
BA_ "GenSigTimeoutTime_SGW" SG_ 1456 RRCC_LEDSts 0;
BA_ "GenSigTimeoutTime_RFHM" SG_ 1456 RRCC_LEDSts 0;
BA_ "GenSigTimeoutTime_MPAD" SG_ 1456 RRCC_LEDSts 0;
BA_ "GenSigTimeoutTime_IPC" SG_ 1456 RRCC_LEDSts 0;
BA_ "GenSigTimeoutTime_GNMM" SG_ 1456 RRCC_LEDSts 0;
BA_ "GenSigTimeoutTime_EVCU2" SG_ 1456 RRCC_LEDSts 0;
BA_ "GenSigTimeoutTime_ESL" SG_ 1456 RRCC_LEDSts 0;
BA_ "GenSigTimeoutTime_ECM" SG_ 1456 RRCC_LEDSts 0;
BA_ "GenSigTimeoutTime_DTCM" SG_ 1456 RRCC_LEDSts 0;
BA_ "GenSigTimeoutTime_DMSM" SG_ 1456 RRCC_LEDSts 0;
BA_ "GenSigTimeoutTime_BSM" SG_ 1456 RRCC_LEDSts 0;
BA_ "GenSigTimeoutTime_BCM" SG_ 1456 RRCC_LEDSts 0;
BA_ "GenSigTimeoutTime_AGSM" SG_ 1456 RRCC_LEDSts 0;
BA_ "GenSigTimeoutTime_ADCAM" SG_ 1456 RRCC_LEDSts 0;
BA_ "GenSigSendType" SG_ 1456 RRCC_LEDSts 3;
BA_ "GenSigTimeoutTime_SGW" SG_ 278 TRANS_ADAS_Inhibit 0;
BA_ "GenSigTimeoutTime_RFHM" SG_ 278 TRANS_ADAS_Inhibit 0;
BA_ "GenSigTimeoutTime_MPAD" SG_ 278 TRANS_ADAS_Inhibit 0;
BA_ "GenSigTimeoutTime_IPC" SG_ 278 TRANS_ADAS_Inhibit 0;
BA_ "GenSigTimeoutTime_GNMM" SG_ 278 TRANS_ADAS_Inhibit 0;
BA_ "GenSigTimeoutTime_EVCU2" SG_ 278 TRANS_ADAS_Inhibit 0;
BA_ "GenSigTimeoutTime_ESL" SG_ 278 TRANS_ADAS_Inhibit 0;
BA_ "GenSigTimeoutTime_ECM" SG_ 278 TRANS_ADAS_Inhibit 0;
BA_ "GenSigTimeoutTime_DTCM" SG_ 278 TRANS_ADAS_Inhibit 0;
BA_ "GenSigTimeoutTime_DMSM" SG_ 278 TRANS_ADAS_Inhibit 0;
BA_ "GenSigTimeoutTime_AGSM" SG_ 278 TRANS_ADAS_Inhibit 0;
BA_ "GenSigTimeoutTime_ADCAM" SG_ 278 TRANS_ADAS_Inhibit 0;
BA_ "GenSigTimeoutTime_SGW" SG_ 610 SpeedArrows 0;
BA_ "GenSigTimeoutTime_RFHM" SG_ 610 SpeedArrows 0;
BA_ "GenSigTimeoutTime_MPAD" SG_ 610 SpeedArrows 0;
BA_ "GenSigTimeoutTime_GNMM" SG_ 610 SpeedArrows 0;
BA_ "GenSigTimeoutTime_EVCU2" SG_ 610 SpeedArrows 0;
BA_ "GenSigTimeoutTime_ESL" SG_ 610 SpeedArrows 0;
BA_ "GenSigTimeoutTime_ECM" SG_ 610 SpeedArrows 0;
BA_ "GenSigTimeoutTime_DTCM" SG_ 610 SpeedArrows 0;
BA_ "GenSigTimeoutTime_DMSM" SG_ 610 SpeedArrows 0;
BA_ "GenSigTimeoutTime_BSM" SG_ 610 SpeedArrows 0;
BA_ "GenSigTimeoutTime_BCM" SG_ 610 SpeedArrows 0;
BA_ "GenSigTimeoutTime_AGSM" SG_ 610 SpeedArrows 0;
BA_ "GenSigTimeoutTime_ADCAM" SG_ 610 SpeedArrows 0;
BA_ "GenSigSendType" SG_ 610 SpeedArrows 3;
BA_ "GenSigTimeoutTime_SGW" SG_ 610 SignVehicleSpeedLimitPredictive 0;
BA_ "GenSigTimeoutTime_RFHM" SG_ 610 SignVehicleSpeedLimitPredictive 0;
BA_ "GenSigTimeoutTime_MPAD" SG_ 610 SignVehicleSpeedLimitPredictive 0;
BA_ "GenSigTimeoutTime_GNMM" SG_ 610 SignVehicleSpeedLimitPredictive 0;
BA_ "GenSigTimeoutTime_EVCU2" SG_ 610 SignVehicleSpeedLimitPredictive 0;
BA_ "GenSigTimeoutTime_ESL" SG_ 610 SignVehicleSpeedLimitPredictive 0;
BA_ "GenSigTimeoutTime_ECM" SG_ 610 SignVehicleSpeedLimitPredictive 0;
BA_ "GenSigTimeoutTime_DTCM" SG_ 610 SignVehicleSpeedLimitPredictive 0;
BA_ "GenSigTimeoutTime_DMSM" SG_ 610 SignVehicleSpeedLimitPredictive 0;
BA_ "GenSigTimeoutTime_BSM" SG_ 610 SignVehicleSpeedLimitPredictive 0;
BA_ "GenSigTimeoutTime_BCM" SG_ 610 SignVehicleSpeedLimitPredictive 0;
BA_ "GenSigTimeoutTime_AGSM" SG_ 610 SignVehicleSpeedLimitPredictive 0;
BA_ "GenSigTimeoutTime_ADCAM" SG_ 610 SignVehicleSpeedLimitPredictive 0;
BA_ "GenSigTimeoutTime_SGW" SG_ 610 Turn_Lever_Unlatch_Req 0;
BA_ "GenSigTimeoutTime_RFHM" SG_ 610 Turn_Lever_Unlatch_Req 0;
BA_ "GenSigTimeoutTime_MPAD" SG_ 610 Turn_Lever_Unlatch_Req 0;
BA_ "GenSigTimeoutTime_IPC" SG_ 610 Turn_Lever_Unlatch_Req 0;
BA_ "GenSigTimeoutTime_GNMM" SG_ 610 Turn_Lever_Unlatch_Req 0;
BA_ "GenSigTimeoutTime_EVCU2" SG_ 610 Turn_Lever_Unlatch_Req 0;
BA_ "GenSigTimeoutTime_ESL" SG_ 610 Turn_Lever_Unlatch_Req 0;
BA_ "GenSigTimeoutTime_ECM" SG_ 610 Turn_Lever_Unlatch_Req 0;
BA_ "GenSigTimeoutTime_DTCM" SG_ 610 Turn_Lever_Unlatch_Req 0;
BA_ "GenSigTimeoutTime_DMSM" SG_ 610 Turn_Lever_Unlatch_Req 0;
BA_ "GenSigTimeoutTime_BSM" SG_ 610 Turn_Lever_Unlatch_Req 0;
BA_ "GenSigTimeoutTime_AGSM" SG_ 610 Turn_Lever_Unlatch_Req 0;
BA_ "GenSigTimeoutTime_ADCAM" SG_ 610 Turn_Lever_Unlatch_Req 0;
BA_ "GenSigSendType" SG_ 610 Turn_Lever_Unlatch_Req 4;
BA_ "GenSigTimeoutTime_RFHM" SG_ 610 Speed_Sign_Shape 0;
BA_ "GenSigTimeoutTime_MPAD" SG_ 610 Speed_Sign_Shape 0;
BA_ "GenSigTimeoutTime_GNMM" SG_ 610 Speed_Sign_Shape 0;
BA_ "GenSigTimeoutTime_EVCU2" SG_ 610 Speed_Sign_Shape 0;
BA_ "GenSigTimeoutTime_ESL" SG_ 610 Speed_Sign_Shape 0;
BA_ "GenSigTimeoutTime_ECM" SG_ 610 Speed_Sign_Shape 0;
BA_ "GenSigTimeoutTime_DTCM" SG_ 610 Speed_Sign_Shape 0;
BA_ "GenSigTimeoutTime_DMSM" SG_ 610 Speed_Sign_Shape 0;
BA_ "GenSigTimeoutTime_BSM" SG_ 610 Speed_Sign_Shape 0;
BA_ "GenSigTimeoutTime_BCM" SG_ 610 Speed_Sign_Shape 0;
BA_ "GenSigTimeoutTime_AGSM" SG_ 610 Speed_Sign_Shape 0;
BA_ "GenSigTimeoutTime_ADCAM" SG_ 610 Speed_Sign_Shape 0;
BA_ "GenSigSendType" SG_ 610 Speed_Sign_Shape 3;
BA_ "GenSigTimeoutTime_SGW" SG_ 610 SpdUnits_Cam 0;
BA_ "GenSigTimeoutTime_RFHM" SG_ 610 SpdUnits_Cam 0;
BA_ "GenSigTimeoutTime_MPAD" SG_ 610 SpdUnits_Cam 0;
BA_ "GenSigTimeoutTime_GNMM" SG_ 610 SpdUnits_Cam 0;
BA_ "GenSigTimeoutTime_EVCU2" SG_ 610 SpdUnits_Cam 0;
BA_ "GenSigTimeoutTime_ESL" SG_ 610 SpdUnits_Cam 0;
BA_ "GenSigTimeoutTime_ECM" SG_ 610 SpdUnits_Cam 0;
BA_ "GenSigTimeoutTime_DTCM" SG_ 610 SpdUnits_Cam 0;
BA_ "GenSigTimeoutTime_DMSM" SG_ 610 SpdUnits_Cam 0;
BA_ "GenSigTimeoutTime_BSM" SG_ 610 SpdUnits_Cam 0;
BA_ "GenSigTimeoutTime_BCM" SG_ 610 SpdUnits_Cam 0;
BA_ "GenSigTimeoutTime_AGSM" SG_ 610 SpdUnits_Cam 0;
BA_ "GenSigTimeoutTime_ADCAM" SG_ 610 SpdUnits_Cam 0;
BA_ "GenSigSendType" SG_ 610 SpdUnits_Cam 3;
BA_ "GenSigTimeoutTime_SGW" SG_ 610 SourceFusedSpeedLimit 0;
BA_ "GenSigTimeoutTime_RFHM" SG_ 610 SourceFusedSpeedLimit 0;
BA_ "GenSigTimeoutTime_MPAD" SG_ 610 SourceFusedSpeedLimit 0;
BA_ "GenSigTimeoutTime_GNMM" SG_ 610 SourceFusedSpeedLimit 0;
BA_ "GenSigTimeoutTime_EVCU2" SG_ 610 SourceFusedSpeedLimit 0;
BA_ "GenSigTimeoutTime_ESL" SG_ 610 SourceFusedSpeedLimit 0;
BA_ "GenSigTimeoutTime_ECM" SG_ 610 SourceFusedSpeedLimit 0;
BA_ "GenSigTimeoutTime_DTCM" SG_ 610 SourceFusedSpeedLimit 0;
BA_ "GenSigTimeoutTime_DMSM" SG_ 610 SourceFusedSpeedLimit 0;
BA_ "GenSigTimeoutTime_BSM" SG_ 610 SourceFusedSpeedLimit 0;
BA_ "GenSigTimeoutTime_BCM" SG_ 610 SourceFusedSpeedLimit 0;
BA_ "GenSigTimeoutTime_AGSM" SG_ 610 SourceFusedSpeedLimit 0;
BA_ "GenSigTimeoutTime_ADCAM" SG_ 610 SourceFusedSpeedLimit 0;
BA_ "GenSigSendType" SG_ 610 SourceFusedSpeedLimit 3;
BA_ "GenSigTimeoutTime_RFHM" SG_ 610 MRRRR_Sts 0;
BA_ "GenSigTimeoutTime_MPAD" SG_ 610 MRRRR_Sts 0;
BA_ "GenSigTimeoutTime_IPC" SG_ 610 MRRRR_Sts 0;
BA_ "GenSigTimeoutTime_GNMM" SG_ 610 MRRRR_Sts 0;
BA_ "GenSigTimeoutTime_EVCU2" SG_ 610 MRRRR_Sts 0;
BA_ "GenSigTimeoutTime_ESL" SG_ 610 MRRRR_Sts 0;
BA_ "GenSigTimeoutTime_ECM" SG_ 610 MRRRR_Sts 0;
BA_ "GenSigTimeoutTime_DTCM" SG_ 610 MRRRR_Sts 0;
BA_ "GenSigTimeoutTime_DMSM" SG_ 610 MRRRR_Sts 0;
BA_ "GenSigTimeoutTime_BSM" SG_ 610 MRRRR_Sts 0;
BA_ "GenSigTimeoutTime_BCM" SG_ 610 MRRRR_Sts 0;
BA_ "GenSigTimeoutTime_AGSM" SG_ 610 MRRRR_Sts 0;
BA_ "GenSigTimeoutTime_ADCAM" SG_ 610 MRRRR_Sts 0;
BA_ "GenSigSendType" SG_ 610 MRRRR_Sts 3;
BA_ "GenSigTimeoutTime_RFHM" SG_ 610 MRRRL_Sts 0;
BA_ "GenSigTimeoutTime_MPAD" SG_ 610 MRRRL_Sts 0;
BA_ "GenSigTimeoutTime_IPC" SG_ 610 MRRRL_Sts 0;
BA_ "GenSigTimeoutTime_GNMM" SG_ 610 MRRRL_Sts 0;
BA_ "GenSigTimeoutTime_EVCU2" SG_ 610 MRRRL_Sts 0;
BA_ "GenSigTimeoutTime_ESL" SG_ 610 MRRRL_Sts 0;
BA_ "GenSigTimeoutTime_ECM" SG_ 610 MRRRL_Sts 0;
BA_ "GenSigTimeoutTime_DTCM" SG_ 610 MRRRL_Sts 0;
BA_ "GenSigTimeoutTime_DMSM" SG_ 610 MRRRL_Sts 0;
BA_ "GenSigTimeoutTime_BSM" SG_ 610 MRRRL_Sts 0;
BA_ "GenSigTimeoutTime_BCM" SG_ 610 MRRRL_Sts 0;
BA_ "GenSigTimeoutTime_AGSM" SG_ 610 MRRRL_Sts 0;
BA_ "GenSigTimeoutTime_ADCAM" SG_ 610 MRRRL_Sts 0;
BA_ "GenSigSendType" SG_ 610 MRRRL_Sts 3;
BA_ "GenSigTimeoutTime_RFHM" SG_ 610 MRRFR_Sts 0;
BA_ "GenSigTimeoutTime_MPAD" SG_ 610 MRRFR_Sts 0;
BA_ "GenSigTimeoutTime_IPC" SG_ 610 MRRFR_Sts 0;
BA_ "GenSigTimeoutTime_GNMM" SG_ 610 MRRFR_Sts 0;
BA_ "GenSigTimeoutTime_EVCU2" SG_ 610 MRRFR_Sts 0;
BA_ "GenSigTimeoutTime_ESL" SG_ 610 MRRFR_Sts 0;
BA_ "GenSigTimeoutTime_ECM" SG_ 610 MRRFR_Sts 0;
BA_ "GenSigTimeoutTime_DTCM" SG_ 610 MRRFR_Sts 0;
BA_ "GenSigTimeoutTime_DMSM" SG_ 610 MRRFR_Sts 0;
BA_ "GenSigTimeoutTime_BSM" SG_ 610 MRRFR_Sts 0;
BA_ "GenSigTimeoutTime_BCM" SG_ 610 MRRFR_Sts 0;
BA_ "GenSigTimeoutTime_AGSM" SG_ 610 MRRFR_Sts 0;
BA_ "GenSigTimeoutTime_ADCAM" SG_ 610 MRRFR_Sts 0;
BA_ "GenSigSendType" SG_ 610 MRRFR_Sts 3;
BA_ "GenSigTimeoutTime_RFHM" SG_ 610 MRRFL_Sts 0;
BA_ "GenSigTimeoutTime_MPAD" SG_ 610 MRRFL_Sts 0;
BA_ "GenSigTimeoutTime_IPC" SG_ 610 MRRFL_Sts 0;
BA_ "GenSigTimeoutTime_GNMM" SG_ 610 MRRFL_Sts 0;
BA_ "GenSigTimeoutTime_EVCU2" SG_ 610 MRRFL_Sts 0;
BA_ "GenSigTimeoutTime_ESL" SG_ 610 MRRFL_Sts 0;
BA_ "GenSigTimeoutTime_ECM" SG_ 610 MRRFL_Sts 0;
BA_ "GenSigTimeoutTime_DTCM" SG_ 610 MRRFL_Sts 0;
BA_ "GenSigTimeoutTime_DMSM" SG_ 610 MRRFL_Sts 0;
BA_ "GenSigTimeoutTime_BSM" SG_ 610 MRRFL_Sts 0;
BA_ "GenSigTimeoutTime_BCM" SG_ 610 MRRFL_Sts 0;
BA_ "GenSigTimeoutTime_AGSM" SG_ 610 MRRFL_Sts 0;
BA_ "GenSigTimeoutTime_ADCAM" SG_ 610 MRRFL_Sts 0;
BA_ "GenSigSendType" SG_ 610 MRRFL_Sts 3;
BA_ "GenSigTimeoutTime_RFHM" SG_ 610 LRRF_Sts 0;
BA_ "GenSigTimeoutTime_MPAD" SG_ 610 LRRF_Sts 0;
BA_ "GenSigTimeoutTime_IPC" SG_ 610 LRRF_Sts 0;
BA_ "GenSigTimeoutTime_GNMM" SG_ 610 LRRF_Sts 0;
BA_ "GenSigTimeoutTime_EVCU2" SG_ 610 LRRF_Sts 0;
BA_ "GenSigTimeoutTime_ESL" SG_ 610 LRRF_Sts 0;
BA_ "GenSigTimeoutTime_ECM" SG_ 610 LRRF_Sts 0;
BA_ "GenSigTimeoutTime_DTCM" SG_ 610 LRRF_Sts 0;
BA_ "GenSigTimeoutTime_DMSM" SG_ 610 LRRF_Sts 0;
BA_ "GenSigTimeoutTime_BSM" SG_ 610 LRRF_Sts 0;
BA_ "GenSigTimeoutTime_BCM" SG_ 610 LRRF_Sts 0;
BA_ "GenSigTimeoutTime_AGSM" SG_ 610 LRRF_Sts 0;
BA_ "GenSigTimeoutTime_ADCAM" SG_ 610 LRRF_Sts 0;
BA_ "GenSigSendType" SG_ 610 LRRF_Sts 3;
BA_ "GenSigTimeoutTime_RFHM" SG_ 610 LRCF_Sts 0;
BA_ "GenSigTimeoutTime_MPAD" SG_ 610 LRCF_Sts 0;
BA_ "GenSigTimeoutTime_IPC" SG_ 610 LRCF_Sts 0;
BA_ "GenSigTimeoutTime_GNMM" SG_ 610 LRCF_Sts 0;
BA_ "GenSigTimeoutTime_EVCU2" SG_ 610 LRCF_Sts 0;
BA_ "GenSigTimeoutTime_ESL" SG_ 610 LRCF_Sts 0;
BA_ "GenSigTimeoutTime_ECM" SG_ 610 LRCF_Sts 0;
BA_ "GenSigTimeoutTime_DTCM" SG_ 610 LRCF_Sts 0;
BA_ "GenSigTimeoutTime_DMSM" SG_ 610 LRCF_Sts 0;
BA_ "GenSigTimeoutTime_BSM" SG_ 610 LRCF_Sts 0;
BA_ "GenSigTimeoutTime_BCM" SG_ 610 LRCF_Sts 0;
BA_ "GenSigTimeoutTime_AGSM" SG_ 610 LRCF_Sts 0;
BA_ "GenSigTimeoutTime_ADCAM" SG_ 610 LRCF_Sts 0;
BA_ "GenSigSendType" SG_ 610 LRCF_Sts 3;
BA_ "GenSigTimeoutTime_SGW" SG_ 610 DRV_Request 0;
BA_ "GenSigTimeoutTime_RFHM" SG_ 610 DRV_Request 0;
BA_ "GenSigTimeoutTime_MPAD" SG_ 610 DRV_Request 0;
BA_ "GenSigTimeoutTime_GNMM" SG_ 610 DRV_Request 0;
BA_ "GenSigTimeoutTime_EVCU2" SG_ 610 DRV_Request 0;
BA_ "GenSigTimeoutTime_ESL" SG_ 610 DRV_Request 0;
BA_ "GenSigTimeoutTime_ECM" SG_ 610 DRV_Request 0;
BA_ "GenSigTimeoutTime_DTCM" SG_ 610 DRV_Request 0;
BA_ "GenSigTimeoutTime_DMSM" SG_ 610 DRV_Request 0;
BA_ "GenSigTimeoutTime_BSM" SG_ 610 DRV_Request 0;
BA_ "GenSigTimeoutTime_BCM" SG_ 610 DRV_Request 0;
BA_ "GenSigTimeoutTime_AGSM" SG_ 610 DRV_Request 0;
BA_ "GenSigTimeoutTime_ADCAM" SG_ 610 DRV_Request 0;
BA_ "GenSigSendType" SG_ 610 DRV_Request 3;
BA_ "GenSigTimeoutTime_SGW" SG_ 610 DistanceSpeedLimitPredictive 0;
BA_ "GenSigTimeoutTime_RFHM" SG_ 610 DistanceSpeedLimitPredictive 0;
BA_ "GenSigTimeoutTime_MPAD" SG_ 610 DistanceSpeedLimitPredictive 0;
BA_ "GenSigTimeoutTime_GNMM" SG_ 610 DistanceSpeedLimitPredictive 0;
BA_ "GenSigTimeoutTime_EVCU2" SG_ 610 DistanceSpeedLimitPredictive 0;
BA_ "GenSigTimeoutTime_ESL" SG_ 610 DistanceSpeedLimitPredictive 0;
BA_ "GenSigTimeoutTime_ECM" SG_ 610 DistanceSpeedLimitPredictive 0;
BA_ "GenSigTimeoutTime_DTCM" SG_ 610 DistanceSpeedLimitPredictive 0;
BA_ "GenSigTimeoutTime_DMSM" SG_ 610 DistanceSpeedLimitPredictive 0;
BA_ "GenSigTimeoutTime_BSM" SG_ 610 DistanceSpeedLimitPredictive 0;
BA_ "GenSigTimeoutTime_BCM" SG_ 610 DistanceSpeedLimitPredictive 0;
BA_ "GenSigTimeoutTime_AGSM" SG_ 610 DistanceSpeedLimitPredictive 0;
BA_ "GenSigTimeoutTime_ADCAM" SG_ 610 DistanceSpeedLimitPredictive 0;
BA_ "GenSigSendType" SG_ 610 DistanceSpeedLimitPredictive 3;
BA_ "GenSigTimeoutTime_RFHM" SG_ 610 MessageCounter_ADAS_FD_INFO2 0;
BA_ "GenSigTimeoutTime_MPAD" SG_ 610 MessageCounter_ADAS_FD_INFO2 0;
BA_ "GenSigTimeoutTime_GNMM" SG_ 610 MessageCounter_ADAS_FD_INFO2 0;
BA_ "GenSigTimeoutTime_ESL" SG_ 610 MessageCounter_ADAS_FD_INFO2 0;
BA_ "GenSigTimeoutTime_ECM" SG_ 610 MessageCounter_ADAS_FD_INFO2 0;
BA_ "GenSigTimeoutTime_DTCM" SG_ 610 MessageCounter_ADAS_FD_INFO2 0;
BA_ "GenSigTimeoutTime_DMSM" SG_ 610 MessageCounter_ADAS_FD_INFO2 0;
BA_ "GenSigTimeoutTime_BSM" SG_ 610 MessageCounter_ADAS_FD_INFO2 0;
BA_ "GenSigTimeoutTime_AGSM" SG_ 610 MessageCounter_ADAS_FD_INFO2 0;
BA_ "GenSigTimeoutTime_ADCAM" SG_ 610 MessageCounter_ADAS_FD_INFO2 0;
BA_ "GenSigTimeoutTime_RFHM" SG_ 610 CRC_ADAS_FD_INFO2 0;
BA_ "GenSigTimeoutTime_MPAD" SG_ 610 CRC_ADAS_FD_INFO2 0;
BA_ "GenSigTimeoutTime_GNMM" SG_ 610 CRC_ADAS_FD_INFO2 0;
BA_ "GenSigTimeoutTime_ESL" SG_ 610 CRC_ADAS_FD_INFO2 0;
BA_ "GenSigTimeoutTime_ECM" SG_ 610 CRC_ADAS_FD_INFO2 0;
BA_ "GenSigTimeoutTime_DTCM" SG_ 610 CRC_ADAS_FD_INFO2 0;
BA_ "GenSigTimeoutTime_DMSM" SG_ 610 CRC_ADAS_FD_INFO2 0;
BA_ "GenSigTimeoutTime_BSM" SG_ 610 CRC_ADAS_FD_INFO2 0;
BA_ "GenSigTimeoutTime_AGSM" SG_ 610 CRC_ADAS_FD_INFO2 0;
BA_ "GenSigTimeoutTime_ADCAM" SG_ 610 CRC_ADAS_FD_INFO2 0;
BA_ "GenSigTimeoutTime_SGW" SG_ 610 Alg_DisplaySts 0;
BA_ "GenSigTimeoutTime_RFHM" SG_ 610 Alg_DisplaySts 0;
BA_ "GenSigTimeoutTime_MPAD" SG_ 610 Alg_DisplaySts 0;
BA_ "GenSigTimeoutTime_GNMM" SG_ 610 Alg_DisplaySts 0;
BA_ "GenSigTimeoutTime_EVCU2" SG_ 610 Alg_DisplaySts 0;
BA_ "GenSigTimeoutTime_ESL" SG_ 610 Alg_DisplaySts 0;
BA_ "GenSigTimeoutTime_ECM" SG_ 610 Alg_DisplaySts 0;
BA_ "GenSigTimeoutTime_DTCM" SG_ 610 Alg_DisplaySts 0;
BA_ "GenSigTimeoutTime_DMSM" SG_ 610 Alg_DisplaySts 0;
BA_ "GenSigTimeoutTime_BSM" SG_ 610 Alg_DisplaySts 0;
BA_ "GenSigTimeoutTime_BCM" SG_ 610 Alg_DisplaySts 0;
BA_ "GenSigTimeoutTime_AGSM" SG_ 610 Alg_DisplaySts 0;
BA_ "GenSigTimeoutTime_ADCAM" SG_ 610 Alg_DisplaySts 0;
BA_ "GenSigSendType" SG_ 610 Alg_DisplaySts 3;
BA_ "GenSigTimeoutTime_IPC" SG_ 610 CADM_DALM_CRC 0;
BA_ "GenSigTimeoutTime_GNMM" SG_ 610 CADM_DALM_CRC 0;
BA_ "GenSigTimeoutTime_EVCU2" SG_ 610 CADM_DALM_CRC 0;
BA_ "GenSigTimeoutTime_ESL" SG_ 610 CADM_DALM_CRC 0;
BA_ "GenSigTimeoutTime_ECM" SG_ 610 CADM_DALM_CRC 0;
BA_ "GenSigTimeoutTime_DTCM" SG_ 610 CADM_DALM_CRC 0;
BA_ "GenSigTimeoutTime_DMSM" SG_ 610 CADM_DALM_CRC 0;
BA_ "GenSigTimeoutTime_BSM" SG_ 610 CADM_DALM_CRC 0;
BA_ "GenSigTimeoutTime_AGSM" SG_ 610 CADM_DALM_CRC 0;
BA_ "GenSigTimeoutTime_ADCAM" SG_ 610 CADM_DALM_CRC 0;
BA_ "GenSigTimeoutTime_SGW" SG_ 610 CADM_DALM_CRC 0;
BA_ "GenSigTimeoutTime_RFHM" SG_ 610 CADM_DALM_CRC 0;
BA_ "GenSigTimeoutTime_MPAD" SG_ 610 CADM_DALM_CRC 0;
BA_ "GenSigTimeoutTime_SGW" SG_ 610 HAS_Status_DALM 0;
BA_ "GenSigTimeoutTime_RFHM" SG_ 610 HAS_Status_DALM 0;
BA_ "GenSigTimeoutTime_MPAD" SG_ 610 HAS_Status_DALM 0;
BA_ "GenSigTimeoutTime_IPC" SG_ 610 HAS_Status_DALM 0;
BA_ "GenSigTimeoutTime_GNMM" SG_ 610 HAS_Status_DALM 0;
BA_ "GenSigTimeoutTime_EVCU2" SG_ 610 HAS_Status_DALM 0;
BA_ "GenSigTimeoutTime_ESL" SG_ 610 HAS_Status_DALM 0;
BA_ "GenSigTimeoutTime_ECM" SG_ 610 HAS_Status_DALM 0;
BA_ "GenSigTimeoutTime_DTCM" SG_ 610 HAS_Status_DALM 0;
BA_ "GenSigTimeoutTime_DMSM" SG_ 610 HAS_Status_DALM 0;
BA_ "GenSigTimeoutTime_BSM" SG_ 610 HAS_Status_DALM 0;
BA_ "GenSigTimeoutTime_AGSM" SG_ 610 HAS_Status_DALM 0;
BA_ "GenSigTimeoutTime_ADCAM" SG_ 610 HAS_Status_DALM 0;
BA_ "GenSigSendType" SG_ 610 HAS_Status_DALM 3;
BA_ "GenSigTimeoutTime_SGW" SG_ 610 HAS_OpStat_Prim_DALM 0;
BA_ "GenSigTimeoutTime_RFHM" SG_ 610 HAS_OpStat_Prim_DALM 0;
BA_ "GenSigTimeoutTime_MPAD" SG_ 610 HAS_OpStat_Prim_DALM 0;
BA_ "GenSigTimeoutTime_IPC" SG_ 610 HAS_OpStat_Prim_DALM 0;
BA_ "GenSigTimeoutTime_GNMM" SG_ 610 HAS_OpStat_Prim_DALM 0;
BA_ "GenSigTimeoutTime_EVCU2" SG_ 610 HAS_OpStat_Prim_DALM 0;
BA_ "GenSigTimeoutTime_ESL" SG_ 610 HAS_OpStat_Prim_DALM 0;
BA_ "GenSigTimeoutTime_ECM" SG_ 610 HAS_OpStat_Prim_DALM 0;
BA_ "GenSigTimeoutTime_DTCM" SG_ 610 HAS_OpStat_Prim_DALM 0;
BA_ "GenSigTimeoutTime_DMSM" SG_ 610 HAS_OpStat_Prim_DALM 0;
BA_ "GenSigTimeoutTime_BSM" SG_ 610 HAS_OpStat_Prim_DALM 0;
BA_ "GenSigTimeoutTime_AGSM" SG_ 610 HAS_OpStat_Prim_DALM 0;
BA_ "GenSigTimeoutTime_ADCAM" SG_ 610 HAS_OpStat_Prim_DALM 0;
BA_ "GenSigSendType" SG_ 610 HAS_OpStat_Prim_DALM 3;
BA_ "GenSigTimeoutTime_SGW" SG_ 610 DALM_Request 0;
BA_ "GenSigTimeoutTime_RFHM" SG_ 610 DALM_Request 0;
BA_ "GenSigTimeoutTime_MPAD" SG_ 610 DALM_Request 0;
BA_ "GenSigTimeoutTime_IPC" SG_ 610 DALM_Request 0;
BA_ "GenSigTimeoutTime_GNMM" SG_ 610 DALM_Request 0;
BA_ "GenSigTimeoutTime_EVCU2" SG_ 610 DALM_Request 0;
BA_ "GenSigTimeoutTime_ESL" SG_ 610 DALM_Request 0;
BA_ "GenSigTimeoutTime_ECM" SG_ 610 DALM_Request 0;
BA_ "GenSigTimeoutTime_DTCM" SG_ 610 DALM_Request 0;
BA_ "GenSigTimeoutTime_DMSM" SG_ 610 DALM_Request 0;
BA_ "GenSigTimeoutTime_BSM" SG_ 610 DALM_Request 0;
BA_ "GenSigTimeoutTime_AGSM" SG_ 610 DALM_Request 0;
BA_ "GenSigTimeoutTime_ADCAM" SG_ 610 DALM_Request 0;
BA_ "GenSigSendType" SG_ 610 DALM_Request 3;
BA_ "GenSigTimeoutTime_SGW" SG_ 610 CADM_DALM_MC 0;
BA_ "GenSigTimeoutTime_RFHM" SG_ 610 CADM_DALM_MC 0;
BA_ "GenSigTimeoutTime_MPAD" SG_ 610 CADM_DALM_MC 0;
BA_ "GenSigTimeoutTime_IPC" SG_ 610 CADM_DALM_MC 0;
BA_ "GenSigTimeoutTime_GNMM" SG_ 610 CADM_DALM_MC 0;
BA_ "GenSigTimeoutTime_EVCU2" SG_ 610 CADM_DALM_MC 0;
BA_ "GenSigTimeoutTime_ESL" SG_ 610 CADM_DALM_MC 0;
BA_ "GenSigTimeoutTime_ECM" SG_ 610 CADM_DALM_MC 0;
BA_ "GenSigTimeoutTime_DTCM" SG_ 610 CADM_DALM_MC 0;
BA_ "GenSigTimeoutTime_DMSM" SG_ 610 CADM_DALM_MC 0;
BA_ "GenSigTimeoutTime_BSM" SG_ 610 CADM_DALM_MC 0;
BA_ "GenSigTimeoutTime_AGSM" SG_ 610 CADM_DALM_MC 0;
BA_ "GenSigTimeoutTime_ADCAM" SG_ 610 CADM_DALM_MC 0;
BA_ "GenSigTimeoutTime_SGW" SG_ 610 HAS_ValidRoad 0;
BA_ "GenSigTimeoutTime_RFHM" SG_ 610 HAS_ValidRoad 0;
BA_ "GenSigTimeoutTime_MPAD" SG_ 610 HAS_ValidRoad 0;
BA_ "GenSigTimeoutTime_IPC" SG_ 610 HAS_ValidRoad 0;
BA_ "GenSigTimeoutTime_GNMM" SG_ 610 HAS_ValidRoad 0;
BA_ "GenSigTimeoutTime_EVCU2" SG_ 610 HAS_ValidRoad 0;
BA_ "GenSigTimeoutTime_ESL" SG_ 610 HAS_ValidRoad 0;
BA_ "GenSigTimeoutTime_ECM" SG_ 610 HAS_ValidRoad 0;
BA_ "GenSigTimeoutTime_DTCM" SG_ 610 HAS_ValidRoad 0;
BA_ "GenSigTimeoutTime_DMSM" SG_ 610 HAS_ValidRoad 0;
BA_ "GenSigTimeoutTime_BSM" SG_ 610 HAS_ValidRoad 0;
BA_ "GenSigTimeoutTime_BCM" SG_ 610 HAS_ValidRoad 0;
BA_ "GenSigTimeoutTime_AGSM" SG_ 610 HAS_ValidRoad 0;
BA_ "GenSigTimeoutTime_ADCAM" SG_ 610 HAS_ValidRoad 0;
BA_ "GenSigSendType" SG_ 610 HAS_ValidRoad 3;
BA_ "GenSigTimeoutTime_IPC" SG_ 1452 E_Call_Stat_TBM 0;
BA_ "GenSigTimeoutTime_GNMM" SG_ 1452 E_Call_Stat_TBM 0;
BA_ "GenSigTimeoutTime_EVCU2" SG_ 1452 E_Call_Stat_TBM 0;
BA_ "GenSigTimeoutTime_ESL" SG_ 1452 E_Call_Stat_TBM 0;
BA_ "GenSigTimeoutTime_ECM" SG_ 1452 E_Call_Stat_TBM 0;
BA_ "GenSigTimeoutTime_DTCM" SG_ 1452 E_Call_Stat_TBM 0;
BA_ "GenSigTimeoutTime_DMSM" SG_ 1452 E_Call_Stat_TBM 0;
BA_ "GenSigTimeoutTime_BSM" SG_ 1452 E_Call_Stat_TBM 0;
BA_ "GenSigTimeoutTime_AGSM" SG_ 1452 E_Call_Stat_TBM 0;
BA_ "GenSigTimeoutTime_ADCAM" SG_ 1452 E_Call_Stat_TBM 0;
BA_ "GenSigSendType" SG_ 1452 E_Call_Stat_TBM 3;
BA_ "GenSigTimeoutTime_SGW" SG_ 1452 CRC_TBMS2 0;
BA_ "GenSigTimeoutTime_RFHM" SG_ 1452 CRC_TBMS2 0;
BA_ "GenSigTimeoutTime_IPC" SG_ 1452 CRC_TBMS2 0;
BA_ "GenSigTimeoutTime_GNMM" SG_ 1452 CRC_TBMS2 0;
BA_ "GenSigTimeoutTime_EVCU2" SG_ 1452 CRC_TBMS2 0;
BA_ "GenSigTimeoutTime_ESL" SG_ 1452 CRC_TBMS2 0;
BA_ "GenSigTimeoutTime_ECM" SG_ 1452 CRC_TBMS2 0;
BA_ "GenSigTimeoutTime_DTCM" SG_ 1452 CRC_TBMS2 0;
BA_ "GenSigTimeoutTime_DMSM" SG_ 1452 CRC_TBMS2 0;
BA_ "GenSigTimeoutTime_BSM" SG_ 1452 CRC_TBMS2 0;
BA_ "GenSigTimeoutTime_AGSM" SG_ 1452 CRC_TBMS2 0;
BA_ "GenSigTimeoutTime_ADCAM" SG_ 1452 CRC_TBMS2 0;
BA_ "GenSigTimeoutTime_ECM" SG_ 610 SignVehicleSpeedLimitConditional 0;
BA_ "GenSigTimeoutTime_DTCM" SG_ 610 SignVehicleSpeedLimitConditional 0;
BA_ "GenSigTimeoutTime_DMSM" SG_ 610 SignVehicleSpeedLimitConditional 0;
BA_ "GenSigTimeoutTime_BSM" SG_ 610 SignVehicleSpeedLimitConditional 0;
BA_ "GenSigTimeoutTime_BCM" SG_ 610 SignVehicleSpeedLimitConditional 0;
BA_ "GenSigTimeoutTime_AGSM" SG_ 610 SignVehicleSpeedLimitConditional 0;
BA_ "GenSigTimeoutTime_ADCAM" SG_ 610 SignVehicleSpeedLimitConditional 0;
BA_ "GenSigSendType" SG_ 610 SignVehicleSpeedLimitConditional 3;
BA_ "GenSigTimeoutTime_SGW" SG_ 610 SignVehicleSpeedLimitConditional 0;
BA_ "GenSigTimeoutTime_RFHM" SG_ 610 SignVehicleSpeedLimitConditional 0;
BA_ "GenSigTimeoutTime_MPAD" SG_ 610 SignVehicleSpeedLimitConditional 0;
BA_ "GenSigTimeoutTime_GNMM" SG_ 610 SignVehicleSpeedLimitConditional 0;
BA_ "GenSigTimeoutTime_EVCU2" SG_ 610 SignVehicleSpeedLimitConditional 0;
BA_ "GenSigTimeoutTime_ESL" SG_ 610 SignVehicleSpeedLimitConditional 0;
BA_ "GenSigTimeoutTime_SGW" SG_ 610 SignVehicleSpeedLimit 0;
BA_ "GenSigTimeoutTime_RFHM" SG_ 610 SignVehicleSpeedLimit 0;
BA_ "GenSigTimeoutTime_MPAD" SG_ 610 SignVehicleSpeedLimit 0;
BA_ "GenSigTimeoutTime_GNMM" SG_ 610 SignVehicleSpeedLimit 0;
BA_ "GenSigTimeoutTime_EVCU2" SG_ 610 SignVehicleSpeedLimit 0;
BA_ "GenSigTimeoutTime_ESL" SG_ 610 SignVehicleSpeedLimit 0;
BA_ "GenSigTimeoutTime_ECM" SG_ 610 SignVehicleSpeedLimit 0;
BA_ "GenSigTimeoutTime_DTCM" SG_ 610 SignVehicleSpeedLimit 0;
BA_ "GenSigTimeoutTime_DMSM" SG_ 610 SignVehicleSpeedLimit 0;
BA_ "GenSigTimeoutTime_BSM" SG_ 610 SignVehicleSpeedLimit 0;
BA_ "GenSigTimeoutTime_BCM" SG_ 610 SignVehicleSpeedLimit 0;
BA_ "GenSigTimeoutTime_AGSM" SG_ 610 SignVehicleSpeedLimit 0;
BA_ "GenSigTimeoutTime_ADCAM" SG_ 610 SignVehicleSpeedLimit 0;
BA_ "GenSigSendType" SG_ 610 SignVehicleSpeedLimit 3;
BA_ "GenSigTimeoutTime_SGW" SG_ 610 SignSupplemVehicleSpeedLimit 0;
BA_ "GenSigTimeoutTime_RFHM" SG_ 610 SignSupplemVehicleSpeedLimit 0;
BA_ "GenSigTimeoutTime_MPAD" SG_ 610 SignSupplemVehicleSpeedLimit 0;
BA_ "GenSigTimeoutTime_GNMM" SG_ 610 SignSupplemVehicleSpeedLimit 0;
BA_ "GenSigTimeoutTime_EVCU2" SG_ 610 SignSupplemVehicleSpeedLimit 0;
BA_ "GenSigTimeoutTime_ESL" SG_ 610 SignSupplemVehicleSpeedLimit 0;
BA_ "GenSigTimeoutTime_ECM" SG_ 610 SignSupplemVehicleSpeedLimit 0;
BA_ "GenSigTimeoutTime_DTCM" SG_ 610 SignSupplemVehicleSpeedLimit 0;
BA_ "GenSigTimeoutTime_DMSM" SG_ 610 SignSupplemVehicleSpeedLimit 0;
BA_ "GenSigTimeoutTime_BSM" SG_ 610 SignSupplemVehicleSpeedLimit 0;
BA_ "GenSigTimeoutTime_BCM" SG_ 610 SignSupplemVehicleSpeedLimit 0;
BA_ "GenSigTimeoutTime_AGSM" SG_ 610 SignSupplemVehicleSpeedLimit 0;
BA_ "GenSigTimeoutTime_ADCAM" SG_ 610 SignSupplemVehicleSpeedLimit 0;
BA_ "GenSigSendType" SG_ 610 SignSupplemVehicleSpeedLimit 3;
BA_ "GenSigTimeoutTime_RFHM" SG_ 610 TSRSts 0;
BA_ "GenSigTimeoutTime_MPAD" SG_ 610 TSRSts 0;
BA_ "GenSigTimeoutTime_GNMM" SG_ 610 TSRSts 0;
BA_ "GenSigTimeoutTime_ESL" SG_ 610 TSRSts 0;
BA_ "GenSigTimeoutTime_ECM" SG_ 610 TSRSts 0;
BA_ "GenSigTimeoutTime_DTCM" SG_ 610 TSRSts 0;
BA_ "GenSigTimeoutTime_DMSM" SG_ 610 TSRSts 0;
BA_ "GenSigTimeoutTime_BSM" SG_ 610 TSRSts 0;
BA_ "GenSigTimeoutTime_BCM" SG_ 610 TSRSts 0;
BA_ "GenSigTimeoutTime_AGSM" SG_ 610 TSRSts 0;
BA_ "GenSigTimeoutTime_ADCAM" SG_ 610 TSRSts 0;
BA_ "GenSigSendType" SG_ 610 TSRSts 3;
BA_ "GenSigTimeoutTime_SGW" SG_ 610 SignOvertaking 0;
BA_ "GenSigTimeoutTime_RFHM" SG_ 610 SignOvertaking 0;
BA_ "GenSigTimeoutTime_MPAD" SG_ 610 SignOvertaking 0;
BA_ "GenSigTimeoutTime_GNMM" SG_ 610 SignOvertaking 0;
BA_ "GenSigTimeoutTime_EVCU2" SG_ 610 SignOvertaking 0;
BA_ "GenSigTimeoutTime_ESL" SG_ 610 SignOvertaking 0;
BA_ "GenSigTimeoutTime_ECM" SG_ 610 SignOvertaking 0;
BA_ "GenSigTimeoutTime_DTCM" SG_ 610 SignOvertaking 0;
BA_ "GenSigTimeoutTime_DMSM" SG_ 610 SignOvertaking 0;
BA_ "GenSigTimeoutTime_BSM" SG_ 610 SignOvertaking 0;
BA_ "GenSigTimeoutTime_BCM" SG_ 610 SignOvertaking 0;
BA_ "GenSigTimeoutTime_AGSM" SG_ 610 SignOvertaking 0;
BA_ "GenSigTimeoutTime_ADCAM" SG_ 610 SignOvertaking 0;
BA_ "GenSigSendType" SG_ 610 SignOvertaking 3;
BA_ "GenSigTimeoutTime_RFHM" SG_ 610 AHBFault 0;
BA_ "GenSigTimeoutTime_MPAD" SG_ 610 AHBFault 0;
BA_ "GenSigTimeoutTime_IPC" SG_ 610 AHBFault 0;
BA_ "GenSigTimeoutTime_GNMM" SG_ 610 AHBFault 0;
BA_ "GenSigTimeoutTime_EVCU2" SG_ 610 AHBFault 0;
BA_ "GenSigTimeoutTime_ESL" SG_ 610 AHBFault 0;
BA_ "GenSigTimeoutTime_ECM" SG_ 610 AHBFault 0;
BA_ "GenSigTimeoutTime_DTCM" SG_ 610 AHBFault 0;
BA_ "GenSigTimeoutTime_DMSM" SG_ 610 AHBFault 0;
BA_ "GenSigTimeoutTime_BSM" SG_ 610 AHBFault 0;
BA_ "GenSigTimeoutTime_AGSM" SG_ 610 AHBFault 0;
BA_ "GenSigTimeoutTime_ADCAM" SG_ 610 AHBFault 0;
BA_ "GenSigTimeoutTime_SGW" SG_ 610 AHB_ON 0;
BA_ "GenSigTimeoutTime_RFHM" SG_ 610 AHB_ON 0;
BA_ "GenSigTimeoutTime_MPAD" SG_ 610 AHB_ON 0;
BA_ "GenSigTimeoutTime_IPC" SG_ 610 AHB_ON 0;
BA_ "GenSigTimeoutTime_GNMM" SG_ 610 AHB_ON 0;
BA_ "GenSigTimeoutTime_EVCU2" SG_ 610 AHB_ON 0;
BA_ "GenSigTimeoutTime_ESL" SG_ 610 AHB_ON 0;
BA_ "GenSigTimeoutTime_ECM" SG_ 610 AHB_ON 0;
BA_ "GenSigTimeoutTime_DTCM" SG_ 610 AHB_ON 0;
BA_ "GenSigTimeoutTime_DMSM" SG_ 610 AHB_ON 0;
BA_ "GenSigTimeoutTime_BSM" SG_ 610 AHB_ON 0;
BA_ "GenSigTimeoutTime_AGSM" SG_ 610 AHB_ON 0;
BA_ "GenSigTimeoutTime_ADCAM" SG_ 610 AHB_ON 0;
BA_ "GenSigTimeoutTime_SGW" SG_ 610 AHB_Blind 0;
BA_ "GenSigTimeoutTime_RFHM" SG_ 610 AHB_Blind 0;
BA_ "GenSigTimeoutTime_MPAD" SG_ 610 AHB_Blind 0;
BA_ "GenSigTimeoutTime_IPC" SG_ 610 AHB_Blind 0;
BA_ "GenSigTimeoutTime_GNMM" SG_ 610 AHB_Blind 0;
BA_ "GenSigTimeoutTime_EVCU2" SG_ 610 AHB_Blind 0;
BA_ "GenSigTimeoutTime_ESL" SG_ 610 AHB_Blind 0;
BA_ "GenSigTimeoutTime_ECM" SG_ 610 AHB_Blind 0;
BA_ "GenSigTimeoutTime_DTCM" SG_ 610 AHB_Blind 0;
BA_ "GenSigTimeoutTime_DMSM" SG_ 610 AHB_Blind 0;
BA_ "GenSigTimeoutTime_BSM" SG_ 610 AHB_Blind 0;
BA_ "GenSigTimeoutTime_AGSM" SG_ 610 AHB_Blind 0;
BA_ "GenSigTimeoutTime_ADCAM" SG_ 610 AHB_Blind 0;
BA_ "GenSigTimeoutTime_SGW" SG_ 1456 CRC_ADAS_FD_HMI 0;
BA_ "GenSigTimeoutTime_RFHM" SG_ 1456 CRC_ADAS_FD_HMI 0;
BA_ "GenSigTimeoutTime_MPAD" SG_ 1456 CRC_ADAS_FD_HMI 0;
BA_ "GenSigTimeoutTime_GNMM" SG_ 1456 CRC_ADAS_FD_HMI 0;
BA_ "GenSigTimeoutTime_EVCU2" SG_ 1456 CRC_ADAS_FD_HMI 0;
BA_ "GenSigTimeoutTime_ESL" SG_ 1456 CRC_ADAS_FD_HMI 0;
BA_ "GenSigTimeoutTime_ECM" SG_ 1456 CRC_ADAS_FD_HMI 0;
BA_ "GenSigTimeoutTime_DTCM" SG_ 1456 CRC_ADAS_FD_HMI 0;
BA_ "GenSigTimeoutTime_AGSM" SG_ 1456 CRC_ADAS_FD_HMI 0;
BA_ "GenSigTimeoutTime_RFHM" SG_ 1456 Chime_Priority 0;
BA_ "GenSigTimeoutTime_MPAD" SG_ 1456 Chime_Priority 0;
BA_ "GenSigTimeoutTime_IPC" SG_ 1456 Chime_Priority 0;
BA_ "GenSigTimeoutTime_GNMM" SG_ 1456 Chime_Priority 0;
BA_ "GenSigTimeoutTime_EVCU2" SG_ 1456 Chime_Priority 0;
BA_ "GenSigTimeoutTime_ESL" SG_ 1456 Chime_Priority 0;
BA_ "GenSigTimeoutTime_ECM" SG_ 1456 Chime_Priority 0;
BA_ "GenSigTimeoutTime_DTCM" SG_ 1456 Chime_Priority 0;
BA_ "GenSigTimeoutTime_DMSM" SG_ 1456 Chime_Priority 0;
BA_ "GenSigTimeoutTime_BSM" SG_ 1456 Chime_Priority 0;
BA_ "GenSigTimeoutTime_AGSM" SG_ 1456 Chime_Priority 0;
BA_ "GenSigTimeoutTime_ADCAM" SG_ 1456 Chime_Priority 0;
BA_ "GenSigSendType" SG_ 1456 Chime_Priority 3;
BA_ "GenSigTimeoutTime_RFHM" SG_ 1456 BSS_SRV_RQSts 0;
BA_ "GenSigTimeoutTime_MPAD" SG_ 1456 BSS_SRV_RQSts 0;
BA_ "GenSigTimeoutTime_GNMM" SG_ 1456 BSS_SRV_RQSts 0;
BA_ "GenSigTimeoutTime_EVCU2" SG_ 1456 BSS_SRV_RQSts 0;
BA_ "GenSigTimeoutTime_ESL" SG_ 1456 BSS_SRV_RQSts 0;
BA_ "GenSigTimeoutTime_ECM" SG_ 1456 BSS_SRV_RQSts 0;
BA_ "GenSigTimeoutTime_DTCM" SG_ 1456 BSS_SRV_RQSts 0;
BA_ "GenSigTimeoutTime_DMSM" SG_ 1456 BSS_SRV_RQSts 0;
BA_ "GenSigTimeoutTime_BSM" SG_ 1456 BSS_SRV_RQSts 0;
BA_ "GenSigTimeoutTime_AGSM" SG_ 1456 BSS_SRV_RQSts 0;
BA_ "GenSigTimeoutTime_ADCAM" SG_ 1456 BSS_SRV_RQSts 0;
BA_ "GenSigSendType" SG_ 1456 BSS_SRV_RQSts 3;
BA_ "GenSigTimeoutTime_RFHM" SG_ 1456 BSS_Blind_RQSts 0;
BA_ "GenSigTimeoutTime_MPAD" SG_ 1456 BSS_Blind_RQSts 0;
BA_ "GenSigTimeoutTime_GNMM" SG_ 1456 BSS_Blind_RQSts 0;
BA_ "GenSigTimeoutTime_EVCU2" SG_ 1456 BSS_Blind_RQSts 0;
BA_ "GenSigTimeoutTime_ESL" SG_ 1456 BSS_Blind_RQSts 0;
BA_ "GenSigTimeoutTime_ECM" SG_ 1456 BSS_Blind_RQSts 0;
BA_ "GenSigTimeoutTime_DTCM" SG_ 1456 BSS_Blind_RQSts 0;
BA_ "GenSigTimeoutTime_DMSM" SG_ 1456 BSS_Blind_RQSts 0;
BA_ "GenSigTimeoutTime_BSM" SG_ 1456 BSS_Blind_RQSts 0;
BA_ "GenSigTimeoutTime_AGSM" SG_ 1456 BSS_Blind_RQSts 0;
BA_ "GenSigTimeoutTime_ADCAM" SG_ 1456 BSS_Blind_RQSts 0;
BA_ "GenSigSendType" SG_ 1456 BSS_Blind_RQSts 3;
BA_ "GenSigTimeoutTime_AGSM" SG_ 1456 ICA_Blind 0;
BA_ "GenSigTimeoutTime_ADCAM" SG_ 1456 ICA_Blind 0;
BA_ "GenSigSendType" SG_ 1456 ICA_Blind 3;
BA_ "GenSigTimeoutTime_SGW" SG_ 1456 HAS_TurnSignalRequest 0;
BA_ "GenSigTimeoutTime_RFHM" SG_ 1456 HAS_TurnSignalRequest 0;
BA_ "GenSigTimeoutTime_MPAD" SG_ 1456 HAS_TurnSignalRequest 0;
BA_ "GenSigTimeoutTime_IPC" SG_ 1456 HAS_TurnSignalRequest 0;
BA_ "GenSigTimeoutTime_GNMM" SG_ 1456 HAS_TurnSignalRequest 0;
BA_ "GenSigTimeoutTime_EVCU2" SG_ 1456 HAS_TurnSignalRequest 0;
BA_ "GenSigTimeoutTime_ESL" SG_ 1456 HAS_TurnSignalRequest 0;
BA_ "GenSigTimeoutTime_ECM" SG_ 1456 HAS_TurnSignalRequest 0;
BA_ "GenSigTimeoutTime_DTCM" SG_ 1456 HAS_TurnSignalRequest 0;
BA_ "GenSigTimeoutTime_DMSM" SG_ 1456 HAS_TurnSignalRequest 0;
BA_ "GenSigTimeoutTime_BSM" SG_ 1456 HAS_TurnSignalRequest 0;
BA_ "GenSigTimeoutTime_AGSM" SG_ 1456 HAS_TurnSignalRequest 0;
BA_ "GenSigTimeoutTime_ADCAM" SG_ 1456 HAS_TurnSignalRequest 0;
BA_ "GenSigSendType" SG_ 1456 HAS_TurnSignalRequest 3;
BA_ "GenSigTimeoutTime_RFHM" SG_ 1456 HAS_TelltaleSts 0;
BA_ "GenSigTimeoutTime_MPAD" SG_ 1456 HAS_TelltaleSts 0;
BA_ "GenSigTimeoutTime_GNMM" SG_ 1456 HAS_TelltaleSts 0;
BA_ "GenSigTimeoutTime_EVCU2" SG_ 1456 HAS_TelltaleSts 0;
BA_ "GenSigTimeoutTime_ESL" SG_ 1456 HAS_TelltaleSts 0;
BA_ "GenSigTimeoutTime_ECM" SG_ 1456 HAS_TelltaleSts 0;
BA_ "GenSigTimeoutTime_DTCM" SG_ 1456 HAS_TelltaleSts 0;
BA_ "GenSigTimeoutTime_DMSM" SG_ 1456 HAS_TelltaleSts 0;
BA_ "GenSigTimeoutTime_BSM" SG_ 1456 HAS_TelltaleSts 0;
BA_ "GenSigTimeoutTime_BCM" SG_ 1456 HAS_TelltaleSts 0;
BA_ "GenSigTimeoutTime_AGSM" SG_ 1456 HAS_TelltaleSts 0;
BA_ "GenSigTimeoutTime_ADCAM" SG_ 1456 HAS_TelltaleSts 0;
BA_ "GenSigSendType" SG_ 1456 HAS_TelltaleSts 3;
BA_ "GenSigTimeoutTime_SGW" SG_ 1456 HAS_Hazard 0;
BA_ "GenSigTimeoutTime_RFHM" SG_ 1456 HAS_Hazard 0;
BA_ "GenSigTimeoutTime_MPAD" SG_ 1456 HAS_Hazard 0;
BA_ "GenSigTimeoutTime_IPC" SG_ 1456 HAS_Hazard 0;
BA_ "GenSigTimeoutTime_GNMM" SG_ 1456 HAS_Hazard 0;
BA_ "GenSigTimeoutTime_EVCU2" SG_ 1456 HAS_Hazard 0;
BA_ "GenSigTimeoutTime_ESL" SG_ 1456 HAS_Hazard 0;
BA_ "GenSigTimeoutTime_ECM" SG_ 1456 HAS_Hazard 0;
BA_ "GenSigTimeoutTime_DTCM" SG_ 1456 HAS_Hazard 0;
BA_ "GenSigTimeoutTime_DMSM" SG_ 1456 HAS_Hazard 0;
BA_ "GenSigTimeoutTime_BSM" SG_ 1456 HAS_Hazard 0;
BA_ "GenSigTimeoutTime_AGSM" SG_ 1456 HAS_Hazard 0;
BA_ "GenSigTimeoutTime_ADCAM" SG_ 1456 HAS_Hazard 0;
BA_ "GenSigSendType" SG_ 1456 HAS_Hazard 3;
BA_ "GenSigTimeoutTime_SGW" SG_ 1456 HAS_FailSts 0;
BA_ "GenSigTimeoutTime_RFHM" SG_ 1456 HAS_FailSts 0;
BA_ "GenSigTimeoutTime_MPAD" SG_ 1456 HAS_FailSts 0;
BA_ "GenSigTimeoutTime_GNMM" SG_ 1456 HAS_FailSts 0;
BA_ "GenSigTimeoutTime_EVCU2" SG_ 1456 HAS_FailSts 0;
BA_ "GenSigTimeoutTime_ESL" SG_ 1456 HAS_FailSts 0;
BA_ "GenSigTimeoutTime_ECM" SG_ 1456 HAS_FailSts 0;
BA_ "GenSigTimeoutTime_DTCM" SG_ 1456 HAS_FailSts 0;
BA_ "GenSigTimeoutTime_DMSM" SG_ 1456 HAS_FailSts 0;
BA_ "GenSigTimeoutTime_BSM" SG_ 1456 HAS_FailSts 0;
BA_ "GenSigTimeoutTime_BCM" SG_ 1456 HAS_FailSts 0;
BA_ "GenSigTimeoutTime_AGSM" SG_ 1456 HAS_FailSts 0;
BA_ "GenSigTimeoutTime_ADCAM" SG_ 1456 HAS_FailSts 0;
BA_ "GenSigSendType" SG_ 1456 HAS_FailSts 3;
BA_ "GenSigTimeoutTime_SGW" SG_ 1456 HAS_Escalation_Sts 0;
BA_ "GenSigTimeoutTime_RFHM" SG_ 1456 HAS_Escalation_Sts 0;
BA_ "GenSigTimeoutTime_MPAD" SG_ 1456 HAS_Escalation_Sts 0;
BA_ "GenSigTimeoutTime_IPC" SG_ 1456 HAS_Escalation_Sts 0;
BA_ "GenSigTimeoutTime_GNMM" SG_ 1456 HAS_Escalation_Sts 0;
BA_ "GenSigTimeoutTime_EVCU2" SG_ 1456 HAS_Escalation_Sts 0;
BA_ "GenSigTimeoutTime_ESL" SG_ 1456 HAS_Escalation_Sts 0;
BA_ "GenSigTimeoutTime_ECM" SG_ 1456 HAS_Escalation_Sts 0;
BA_ "GenSigTimeoutTime_DTCM" SG_ 1456 HAS_Escalation_Sts 0;
BA_ "GenSigTimeoutTime_DMSM" SG_ 1456 HAS_Escalation_Sts 0;
BA_ "GenSigTimeoutTime_BSM" SG_ 1456 HAS_Escalation_Sts 0;
BA_ "GenSigTimeoutTime_BCM" SG_ 1456 HAS_Escalation_Sts 0;
BA_ "GenSigTimeoutTime_AGSM" SG_ 1456 HAS_Escalation_Sts 0;
BA_ "GenSigTimeoutTime_ADCAM" SG_ 1456 HAS_Escalation_Sts 0;
BA_ "GenSigSendType" SG_ 1456 HAS_Escalation_Sts 3;
BA_ "GenSigTimeoutTime_SGW" SG_ 1456 HAS_Blind 0;
BA_ "GenSigTimeoutTime_RFHM" SG_ 1456 HAS_Blind 0;
BA_ "GenSigTimeoutTime_MPAD" SG_ 1456 HAS_Blind 0;
BA_ "GenSigTimeoutTime_GNMM" SG_ 1456 HAS_Blind 0;
BA_ "GenSigTimeoutTime_EVCU2" SG_ 1456 HAS_Blind 0;
BA_ "GenSigTimeoutTime_ESL" SG_ 1456 HAS_Blind 0;
BA_ "GenSigTimeoutTime_ECM" SG_ 1456 HAS_Blind 0;
BA_ "GenSigTimeoutTime_DTCM" SG_ 1456 HAS_Blind 0;
BA_ "GenSigTimeoutTime_DMSM" SG_ 1456 HAS_Blind 0;
BA_ "GenSigTimeoutTime_BSM" SG_ 1456 HAS_Blind 0;
BA_ "GenSigTimeoutTime_BCM" SG_ 1456 HAS_Blind 0;
BA_ "GenSigTimeoutTime_AGSM" SG_ 1456 HAS_Blind 0;
BA_ "GenSigTimeoutTime_ADCAM" SG_ 1456 HAS_Blind 0;
BA_ "GenSigSendType" SG_ 1456 HAS_Blind 3;
BA_ "GenSigTimeoutTime_SGW" SG_ 1456 FCW_Setting_Avail 0;
BA_ "GenSigTimeoutTime_RFHM" SG_ 1456 FCW_Setting_Avail 0;
BA_ "GenSigTimeoutTime_MPAD" SG_ 1456 FCW_Setting_Avail 0;
BA_ "GenSigTimeoutTime_GNMM" SG_ 1456 FCW_Setting_Avail 0;
BA_ "GenSigTimeoutTime_EVCU2" SG_ 1456 FCW_Setting_Avail 0;
BA_ "GenSigTimeoutTime_ESL" SG_ 1456 FCW_Setting_Avail 0;
BA_ "GenSigTimeoutTime_ECM" SG_ 1456 FCW_Setting_Avail 0;
BA_ "GenSigTimeoutTime_DTCM" SG_ 1456 FCW_Setting_Avail 0;
BA_ "GenSigTimeoutTime_DMSM" SG_ 1456 FCW_Setting_Avail 0;
BA_ "GenSigTimeoutTime_BSM" SG_ 1456 FCW_Setting_Avail 0;
BA_ "GenSigTimeoutTime_BCM" SG_ 1456 FCW_Setting_Avail 0;
BA_ "GenSigTimeoutTime_AGSM" SG_ 1456 FCW_Setting_Avail 0;
BA_ "GenSigTimeoutTime_ADCAM" SG_ 1456 FCW_Setting_Avail 0;
BA_ "GenSigSendType" SG_ 1456 FCW_Setting_Avail 3;
BA_ "GenSigTimeoutTime_SGW" SG_ 1456 DMSM_Wakeup 0;
BA_ "GenSigTimeoutTime_RFHM" SG_ 1456 DMSM_Wakeup 0;
BA_ "GenSigTimeoutTime_MPAD" SG_ 1456 DMSM_Wakeup 0;
BA_ "GenSigTimeoutTime_IPC" SG_ 1456 DMSM_Wakeup 0;
BA_ "GenSigTimeoutTime_GNMM" SG_ 1456 DMSM_Wakeup 0;
BA_ "GenSigTimeoutTime_EVCU2" SG_ 1456 DMSM_Wakeup 0;
BA_ "GenSigTimeoutTime_ESL" SG_ 1456 DMSM_Wakeup 0;
BA_ "GenSigTimeoutTime_ECM" SG_ 1456 DMSM_Wakeup 0;
BA_ "GenSigTimeoutTime_DTCM" SG_ 1456 DMSM_Wakeup 0;
BA_ "GenSigTimeoutTime_BSM" SG_ 1456 DMSM_Wakeup 0;
BA_ "GenSigTimeoutTime_BCM" SG_ 1456 DMSM_Wakeup 0;
BA_ "GenSigTimeoutTime_AGSM" SG_ 1456 DMSM_Wakeup 0;
BA_ "GenSigTimeoutTime_ADCAM" SG_ 1456 DMSM_Wakeup 0;
BA_ "GenSigSendType" SG_ 1456 DMSM_Wakeup 3;
BA_ "GenSigTimeoutTime_RFHM" SG_ 1456 DisplaySts_Veh 0;
BA_ "GenSigTimeoutTime_MPAD" SG_ 1456 DisplaySts_Veh 0;
BA_ "GenSigTimeoutTime_GNMM" SG_ 1456 DisplaySts_Veh 0;
BA_ "GenSigTimeoutTime_EVCU2" SG_ 1456 DisplaySts_Veh 0;
BA_ "GenSigTimeoutTime_ESL" SG_ 1456 DisplaySts_Veh 0;
BA_ "GenSigTimeoutTime_ECM" SG_ 1456 DisplaySts_Veh 0;
BA_ "GenSigTimeoutTime_DTCM" SG_ 1456 DisplaySts_Veh 0;
BA_ "GenSigTimeoutTime_DMSM" SG_ 1456 DisplaySts_Veh 0;
BA_ "GenSigTimeoutTime_BSM" SG_ 1456 DisplaySts_Veh 0;
BA_ "GenSigTimeoutTime_BCM" SG_ 1456 DisplaySts_Veh 0;
BA_ "GenSigTimeoutTime_AGSM" SG_ 1456 DisplaySts_Veh 0;
BA_ "GenSigTimeoutTime_ADCAM" SG_ 1456 DisplaySts_Veh 0;
BA_ "GenSigSendType" SG_ 1456 DisplaySts_Veh 3;
BA_ "GenSigTimeoutTime_RFHM" SG_ 1456 DisplaySts_OFF 0;
BA_ "GenSigTimeoutTime_MPAD" SG_ 1456 DisplaySts_OFF 0;
BA_ "GenSigTimeoutTime_GNMM" SG_ 1456 DisplaySts_OFF 0;
BA_ "GenSigTimeoutTime_EVCU2" SG_ 1456 DisplaySts_OFF 0;
BA_ "GenSigTimeoutTime_ESL" SG_ 1456 DisplaySts_OFF 0;
BA_ "GenSigTimeoutTime_ECM" SG_ 1456 DisplaySts_OFF 0;
BA_ "GenSigTimeoutTime_DTCM" SG_ 1456 DisplaySts_OFF 0;
BA_ "GenSigTimeoutTime_DMSM" SG_ 1456 DisplaySts_OFF 0;
BA_ "GenSigTimeoutTime_BSM" SG_ 1456 DisplaySts_OFF 0;
BA_ "GenSigTimeoutTime_BCM" SG_ 1456 DisplaySts_OFF 0;
BA_ "GenSigTimeoutTime_AGSM" SG_ 1456 DisplaySts_OFF 0;
BA_ "GenSigTimeoutTime_ADCAM" SG_ 1456 DisplaySts_OFF 0;
BA_ "GenSigSendType" SG_ 1456 DisplaySts_OFF 3;
BA_ "GenSigTimeoutTime_SGW" SG_ 1456 DisplaySts_Curve 0;
BA_ "GenSigTimeoutTime_RFHM" SG_ 1456 DisplaySts_Curve 0;
BA_ "GenSigTimeoutTime_MPAD" SG_ 1456 DisplaySts_Curve 0;
BA_ "GenSigTimeoutTime_GNMM" SG_ 1456 DisplaySts_Curve 0;
BA_ "GenSigTimeoutTime_EVCU2" SG_ 1456 DisplaySts_Curve 0;
BA_ "GenSigTimeoutTime_ESL" SG_ 1456 DisplaySts_Curve 0;
BA_ "GenSigTimeoutTime_ECM" SG_ 1456 DisplaySts_Curve 0;
BA_ "GenSigTimeoutTime_DTCM" SG_ 1456 DisplaySts_Curve 0;
BA_ "GenSigTimeoutTime_DMSM" SG_ 1456 DisplaySts_Curve 0;
BA_ "GenSigTimeoutTime_BSM" SG_ 1456 DisplaySts_Curve 0;
BA_ "GenSigTimeoutTime_BCM" SG_ 1456 DisplaySts_Curve 0;
BA_ "GenSigTimeoutTime_AGSM" SG_ 1456 DisplaySts_Curve 0;
BA_ "GenSigTimeoutTime_ADCAM" SG_ 1456 DisplaySts_Curve 0;
BA_ "GenSigSendType" SG_ 1456 DisplaySts_Curve 3;
BA_ "GenSigTimeoutTime_DMSM" SG_ 1456 DisplaySts_ACC 0;
BA_ "GenSigTimeoutTime_BSM" SG_ 1456 DisplaySts_ACC 0;
BA_ "GenSigTimeoutTime_BCM" SG_ 1456 DisplaySts_ACC 0;
BA_ "GenSigTimeoutTime_AGSM" SG_ 1456 DisplaySts_ACC 0;
BA_ "GenSigTimeoutTime_ADCAM" SG_ 1456 DisplaySts_ACC 0;
BA_ "GenSigSendType" SG_ 1456 DisplaySts_ACC 3;
BA_ "GenSigTimeoutTime_RFHM" SG_ 1456 DisplaySts_ACC 0;
BA_ "GenSigTimeoutTime_MPAD" SG_ 1456 DisplaySts_ACC 0;
BA_ "GenSigTimeoutTime_GNMM" SG_ 1456 DisplaySts_ACC 0;
BA_ "GenSigTimeoutTime_EVCU2" SG_ 1456 DisplaySts_ACC 0;
BA_ "GenSigTimeoutTime_ESL" SG_ 1456 DisplaySts_ACC 0;
BA_ "GenSigTimeoutTime_ECM" SG_ 1456 DisplaySts_ACC 0;
BA_ "GenSigTimeoutTime_DTCM" SG_ 1456 DisplaySts_ACC 0;
BA_ "GenSigTimeoutTime_SGW" SG_ 1456 DDD_FailSts 0;
BA_ "GenSigTimeoutTime_RFHM" SG_ 1456 DDD_FailSts 0;
BA_ "GenSigTimeoutTime_MPAD" SG_ 1456 DDD_FailSts 0;
BA_ "GenSigTimeoutTime_GNMM" SG_ 1456 DDD_FailSts 0;
BA_ "GenSigTimeoutTime_EVCU2" SG_ 1456 DDD_FailSts 0;
BA_ "GenSigTimeoutTime_ESL" SG_ 1456 DDD_FailSts 0;
BA_ "GenSigTimeoutTime_ECM" SG_ 1456 DDD_FailSts 0;
BA_ "GenSigTimeoutTime_DTCM" SG_ 1456 DDD_FailSts 0;
BA_ "GenSigTimeoutTime_DMSM" SG_ 1456 DDD_FailSts 0;
BA_ "GenSigTimeoutTime_BSM" SG_ 1456 DDD_FailSts 0;
BA_ "GenSigTimeoutTime_BCM" SG_ 1456 DDD_FailSts 0;
BA_ "GenSigTimeoutTime_AGSM" SG_ 1456 DDD_FailSts 0;
BA_ "GenSigTimeoutTime_ADCAM" SG_ 1456 DDD_FailSts 0;
BA_ "GenSigSendType" SG_ 1456 DDD_FailSts 3;
BA_ "GenSigTimeoutTime_SGW" SG_ 1456 DDD_DispPopupSts 0;
BA_ "GenSigTimeoutTime_RFHM" SG_ 1456 DDD_DispPopupSts 0;
BA_ "GenSigTimeoutTime_MPAD" SG_ 1456 DDD_DispPopupSts 0;
BA_ "GenSigTimeoutTime_GNMM" SG_ 1456 DDD_DispPopupSts 0;
BA_ "GenSigTimeoutTime_EVCU2" SG_ 1456 DDD_DispPopupSts 0;
BA_ "GenSigTimeoutTime_ESL" SG_ 1456 DDD_DispPopupSts 0;
BA_ "GenSigTimeoutTime_ECM" SG_ 1456 DDD_DispPopupSts 0;
BA_ "GenSigTimeoutTime_DTCM" SG_ 1456 DDD_DispPopupSts 0;
BA_ "GenSigTimeoutTime_DMSM" SG_ 1456 DDD_DispPopupSts 0;
BA_ "GenSigTimeoutTime_BSM" SG_ 1456 DDD_DispPopupSts 0;
BA_ "GenSigTimeoutTime_BCM" SG_ 1456 DDD_DispPopupSts 0;
BA_ "GenSigTimeoutTime_AGSM" SG_ 1456 DDD_DispPopupSts 0;
BA_ "GenSigTimeoutTime_ADCAM" SG_ 1456 DDD_DispPopupSts 0;
BA_ "GenSigSendType" SG_ 1456 DDD_DispPopupSts 3;
BA_ "GenSigTimeoutTime_SGW" SG_ 1456 HAS_TelltaleSts_ext 0;
BA_ "GenSigTimeoutTime_RFHM" SG_ 1456 HAS_TelltaleSts_ext 0;
BA_ "GenSigTimeoutTime_MPAD" SG_ 1456 HAS_TelltaleSts_ext 0;
BA_ "GenSigTimeoutTime_GNMM" SG_ 1456 HAS_TelltaleSts_ext 0;
BA_ "GenSigTimeoutTime_EVCU2" SG_ 1456 HAS_TelltaleSts_ext 0;
BA_ "GenSigTimeoutTime_ESL" SG_ 1456 HAS_TelltaleSts_ext 0;
BA_ "GenSigTimeoutTime_ECM" SG_ 1456 HAS_TelltaleSts_ext 0;
BA_ "GenSigTimeoutTime_DTCM" SG_ 1456 HAS_TelltaleSts_ext 0;
BA_ "GenSigTimeoutTime_DMSM" SG_ 1456 HAS_TelltaleSts_ext 0;
BA_ "GenSigTimeoutTime_BSM" SG_ 1456 HAS_TelltaleSts_ext 0;
BA_ "GenSigTimeoutTime_BCM" SG_ 1456 HAS_TelltaleSts_ext 0;
BA_ "GenSigTimeoutTime_AGSM" SG_ 1456 HAS_TelltaleSts_ext 0;
BA_ "GenSigTimeoutTime_ADCAM" SG_ 1456 HAS_TelltaleSts_ext 0;
BA_ "GenSigSendType" SG_ 1456 HAS_TelltaleSts_ext 3;
BA_ "GenSigTimeoutTime_SGW" SG_ 1456 DisplaySts_Route 0;
BA_ "GenSigTimeoutTime_RFHM" SG_ 1456 DisplaySts_Route 0;
BA_ "GenSigTimeoutTime_MPAD" SG_ 1456 DisplaySts_Route 0;
BA_ "GenSigTimeoutTime_GNMM" SG_ 1456 DisplaySts_Route 0;
BA_ "GenSigTimeoutTime_EVCU2" SG_ 1456 DisplaySts_Route 0;
BA_ "GenSigTimeoutTime_ESL" SG_ 1456 DisplaySts_Route 0;
BA_ "GenSigTimeoutTime_ECM" SG_ 1456 DisplaySts_Route 0;
BA_ "GenSigTimeoutTime_DTCM" SG_ 1456 DisplaySts_Route 0;
BA_ "GenSigTimeoutTime_DMSM" SG_ 1456 DisplaySts_Route 0;
BA_ "GenSigTimeoutTime_BSM" SG_ 1456 DisplaySts_Route 0;
BA_ "GenSigTimeoutTime_BCM" SG_ 1456 DisplaySts_Route 0;
BA_ "GenSigTimeoutTime_AGSM" SG_ 1456 DisplaySts_Route 0;
BA_ "GenSigTimeoutTime_ADCAM" SG_ 1456 DisplaySts_Route 0;
BA_ "GenSigSendType" SG_ 1456 DisplaySts_Route 3;
BA_ "GenSigTimeoutTime_SGW" SG_ 1456 ADASDoorunlock_Request 0;
BA_ "GenSigTimeoutTime_RFHM" SG_ 1456 ADASDoorunlock_Request 0;
BA_ "GenSigTimeoutTime_MPAD" SG_ 1456 ADASDoorunlock_Request 0;
BA_ "GenSigTimeoutTime_IPC" SG_ 1456 ADASDoorunlock_Request 0;
BA_ "GenSigTimeoutTime_GNMM" SG_ 1456 ADASDoorunlock_Request 0;
BA_ "GenSigTimeoutTime_EVCU2" SG_ 1456 ADASDoorunlock_Request 0;
BA_ "GenSigTimeoutTime_ESL" SG_ 1456 ADASDoorunlock_Request 0;
BA_ "GenSigTimeoutTime_ECM" SG_ 1456 ADASDoorunlock_Request 0;
BA_ "GenSigTimeoutTime_DTCM" SG_ 1456 ADASDoorunlock_Request 0;
BA_ "GenSigTimeoutTime_DMSM" SG_ 1456 ADASDoorunlock_Request 0;
BA_ "GenSigTimeoutTime_BSM" SG_ 1456 ADASDoorunlock_Request 0;
BA_ "GenSigTimeoutTime_AGSM" SG_ 1456 ADASDoorunlock_Request 0;
BA_ "GenSigTimeoutTime_ADCAM" SG_ 1456 ADASDoorunlock_Request 0;
BA_ "GenSigSendType" SG_ 1456 ADASDoorunlock_Request 3;
BA_ "GenSigTimeoutTime_RFHM" SG_ 1456 Chime_TypSts 0;
BA_ "GenSigTimeoutTime_MPAD" SG_ 1456 Chime_TypSts 0;
BA_ "GenSigTimeoutTime_IPC" SG_ 1456 Chime_TypSts 0;
BA_ "GenSigTimeoutTime_GNMM" SG_ 1456 Chime_TypSts 0;
BA_ "GenSigTimeoutTime_EVCU2" SG_ 1456 Chime_TypSts 0;
BA_ "GenSigTimeoutTime_ESL" SG_ 1456 Chime_TypSts 0;
BA_ "GenSigTimeoutTime_ECM" SG_ 1456 Chime_TypSts 0;
BA_ "GenSigTimeoutTime_DTCM" SG_ 1456 Chime_TypSts 0;
BA_ "GenSigTimeoutTime_DMSM" SG_ 1456 Chime_TypSts 0;
BA_ "GenSigTimeoutTime_BSM" SG_ 1456 Chime_TypSts 0;
BA_ "GenSigTimeoutTime_AGSM" SG_ 1456 Chime_TypSts 0;
BA_ "GenSigTimeoutTime_ADCAM" SG_ 1456 Chime_TypSts 0;
BA_ "GenSigSendType" SG_ 1456 Chime_TypSts 3;
BA_ "GenSigTimeoutTime_RFHM" SG_ 1456 Chime_RepRate 0;
BA_ "GenSigTimeoutTime_MPAD" SG_ 1456 Chime_RepRate 0;
BA_ "GenSigTimeoutTime_IPC" SG_ 1456 Chime_RepRate 0;
BA_ "GenSigTimeoutTime_GNMM" SG_ 1456 Chime_RepRate 0;
BA_ "GenSigTimeoutTime_EVCU2" SG_ 1456 Chime_RepRate 0;
BA_ "GenSigTimeoutTime_ESL" SG_ 1456 Chime_RepRate 0;
BA_ "GenSigTimeoutTime_ECM" SG_ 1456 Chime_RepRate 0;
BA_ "GenSigTimeoutTime_DTCM" SG_ 1456 Chime_RepRate 0;
BA_ "GenSigTimeoutTime_DMSM" SG_ 1456 Chime_RepRate 0;
BA_ "GenSigTimeoutTime_BSM" SG_ 1456 Chime_RepRate 0;
BA_ "GenSigTimeoutTime_AGSM" SG_ 1456 Chime_RepRate 0;
BA_ "GenSigTimeoutTime_ADCAM" SG_ 1456 Chime_RepRate 0;
BA_ "GenSigSendType" SG_ 1456 Chime_RepRate 3;
BA_ "GenSigTimeoutTime_SGW" SG_ 1456 BlindSpotRightWarn 0;
BA_ "GenSigTimeoutTime_RFHM" SG_ 1456 BlindSpotRightWarn 0;
BA_ "GenSigTimeoutTime_MPAD" SG_ 1456 BlindSpotRightWarn 0;
BA_ "GenSigTimeoutTime_IPC" SG_ 1456 BlindSpotRightWarn 0;
BA_ "GenSigTimeoutTime_GNMM" SG_ 1456 BlindSpotRightWarn 0;
BA_ "GenSigTimeoutTime_EVCU2" SG_ 1456 BlindSpotRightWarn 0;
BA_ "GenSigTimeoutTime_ESL" SG_ 1456 BlindSpotRightWarn 0;
BA_ "GenSigTimeoutTime_ECM" SG_ 1456 BlindSpotRightWarn 0;
BA_ "GenSigTimeoutTime_DTCM" SG_ 1456 BlindSpotRightWarn 0;
BA_ "GenSigTimeoutTime_DMSM" SG_ 1456 BlindSpotRightWarn 0;
BA_ "GenSigTimeoutTime_BSM" SG_ 1456 BlindSpotRightWarn 0;
BA_ "GenSigTimeoutTime_AGSM" SG_ 1456 BlindSpotRightWarn 0;
BA_ "GenSigTimeoutTime_ADCAM" SG_ 1456 BlindSpotRightWarn 0;
BA_ "GenSigSendType" SG_ 1456 BlindSpotRightWarn 3;
BA_ "GenSigTimeoutTime_SGW" SG_ 1456 BlindSpotLeftWarn 0;
BA_ "GenSigTimeoutTime_RFHM" SG_ 1456 BlindSpotLeftWarn 0;
BA_ "GenSigTimeoutTime_MPAD" SG_ 1456 BlindSpotLeftWarn 0;
BA_ "GenSigTimeoutTime_IPC" SG_ 1456 BlindSpotLeftWarn 0;
BA_ "GenSigTimeoutTime_GNMM" SG_ 1456 BlindSpotLeftWarn 0;
BA_ "GenSigTimeoutTime_EVCU2" SG_ 1456 BlindSpotLeftWarn 0;
BA_ "GenSigTimeoutTime_ESL" SG_ 1456 BlindSpotLeftWarn 0;
BA_ "GenSigTimeoutTime_ECM" SG_ 1456 BlindSpotLeftWarn 0;
BA_ "GenSigTimeoutTime_DTCM" SG_ 1456 BlindSpotLeftWarn 0;
BA_ "GenSigTimeoutTime_DMSM" SG_ 1456 BlindSpotLeftWarn 0;
BA_ "GenSigTimeoutTime_BSM" SG_ 1456 BlindSpotLeftWarn 0;
BA_ "GenSigTimeoutTime_AGSM" SG_ 1456 BlindSpotLeftWarn 0;
BA_ "GenSigTimeoutTime_ADCAM" SG_ 1456 BlindSpotLeftWarn 0;
BA_ "GenSigSendType" SG_ 1456 BlindSpotLeftWarn 3;
BA_ "GenSigTimeoutTime_SGW" SG_ 1456 AEB_Limited 0;
BA_ "GenSigTimeoutTime_RFHM" SG_ 1456 AEB_Limited 0;
BA_ "GenSigTimeoutTime_MPAD" SG_ 1456 AEB_Limited 0;
BA_ "GenSigTimeoutTime_GNMM" SG_ 1456 AEB_Limited 0;
BA_ "GenSigTimeoutTime_EVCU2" SG_ 1456 AEB_Limited 0;
BA_ "GenSigTimeoutTime_ESL" SG_ 1456 AEB_Limited 0;
BA_ "GenSigTimeoutTime_ECM" SG_ 1456 AEB_Limited 0;
BA_ "GenSigTimeoutTime_DTCM" SG_ 1456 AEB_Limited 0;
BA_ "GenSigTimeoutTime_DMSM" SG_ 1456 AEB_Limited 0;
BA_ "GenSigTimeoutTime_BSM" SG_ 1456 AEB_Limited 0;
BA_ "GenSigTimeoutTime_BCM" SG_ 1456 AEB_Limited 0;
BA_ "GenSigTimeoutTime_AGSM" SG_ 1456 AEB_Limited 0;
BA_ "GenSigTimeoutTime_ADCAM" SG_ 1456 AEB_Limited 0;
BA_ "GenSigSendType" SG_ 1456 AEB_Limited 3;
BA_ "GenSigTimeoutTime_SGW" SG_ 1456 AEB_Limit_Fail 0;
BA_ "GenSigTimeoutTime_RFHM" SG_ 1456 AEB_Limit_Fail 0;
BA_ "GenSigTimeoutTime_MPAD" SG_ 1456 AEB_Limit_Fail 0;
BA_ "GenSigTimeoutTime_GNMM" SG_ 1456 AEB_Limit_Fail 0;
BA_ "GenSigTimeoutTime_EVCU2" SG_ 1456 AEB_Limit_Fail 0;
BA_ "GenSigTimeoutTime_ESL" SG_ 1456 AEB_Limit_Fail 0;
BA_ "GenSigTimeoutTime_ECM" SG_ 1456 AEB_Limit_Fail 0;
BA_ "GenSigTimeoutTime_DTCM" SG_ 1456 AEB_Limit_Fail 0;
BA_ "GenSigTimeoutTime_DMSM" SG_ 1456 AEB_Limit_Fail 0;
BA_ "GenSigTimeoutTime_BSM" SG_ 1456 AEB_Limit_Fail 0;
BA_ "GenSigTimeoutTime_BCM" SG_ 1456 AEB_Limit_Fail 0;
BA_ "GenSigTimeoutTime_AGSM" SG_ 1456 AEB_Limit_Fail 0;
BA_ "GenSigTimeoutTime_ADCAM" SG_ 1456 AEB_Limit_Fail 0;
BA_ "GenSigSendType" SG_ 1456 AEB_Limit_Fail 3;
BA_ "GenSigTimeoutTime_SGW" SG_ 1456 AEB_FailSts 0;
BA_ "GenSigTimeoutTime_RFHM" SG_ 1456 AEB_FailSts 0;
BA_ "GenSigTimeoutTime_MPAD" SG_ 1456 AEB_FailSts 0;
BA_ "GenSigTimeoutTime_GNMM" SG_ 1456 AEB_FailSts 0;
BA_ "GenSigTimeoutTime_EVCU2" SG_ 1456 AEB_FailSts 0;
BA_ "GenSigTimeoutTime_ESL" SG_ 1456 AEB_FailSts 0;
BA_ "GenSigTimeoutTime_ECM" SG_ 1456 AEB_FailSts 0;
BA_ "GenSigTimeoutTime_DTCM" SG_ 1456 AEB_FailSts 0;
BA_ "GenSigTimeoutTime_DMSM" SG_ 1456 AEB_FailSts 0;
BA_ "GenSigTimeoutTime_BCM" SG_ 1456 AEB_FailSts 0;
BA_ "GenSigTimeoutTime_AGSM" SG_ 1456 AEB_FailSts 0;
BA_ "GenSigTimeoutTime_ADCAM" SG_ 1456 AEB_FailSts 0;
BA_ "GenSigSendType" SG_ 1456 AEB_FailSts 3;
BA_ "GenSigTimeoutTime_RFHM" SG_ 1456 AEB_DispPopupSts 0;
BA_ "GenSigTimeoutTime_MPAD" SG_ 1456 AEB_DispPopupSts 0;
BA_ "GenSigTimeoutTime_GNMM" SG_ 1456 AEB_DispPopupSts 0;
BA_ "GenSigTimeoutTime_EVCU2" SG_ 1456 AEB_DispPopupSts 0;
BA_ "GenSigTimeoutTime_ESL" SG_ 1456 AEB_DispPopupSts 0;
BA_ "GenSigTimeoutTime_ECM" SG_ 1456 AEB_DispPopupSts 0;
BA_ "GenSigTimeoutTime_DTCM" SG_ 1456 AEB_DispPopupSts 0;
BA_ "GenSigTimeoutTime_DMSM" SG_ 1456 AEB_DispPopupSts 0;
BA_ "GenSigTimeoutTime_BSM" SG_ 1456 AEB_DispPopupSts 0;
BA_ "GenSigTimeoutTime_BCM" SG_ 1456 AEB_DispPopupSts 0;
BA_ "GenSigTimeoutTime_AGSM" SG_ 1456 AEB_DispPopupSts 0;
BA_ "GenSigTimeoutTime_ADCAM" SG_ 1456 AEB_DispPopupSts 0;
BA_ "GenSigSendType" SG_ 1456 AEB_DispPopupSts 3;
BA_ "GenSigTimeoutTime_SGW" SG_ 1456 BSS_CFG_STATSts 0;
BA_ "GenSigTimeoutTime_RFHM" SG_ 1456 BSS_CFG_STATSts 0;
BA_ "GenSigTimeoutTime_MPAD" SG_ 1456 BSS_CFG_STATSts 0;
BA_ "GenSigTimeoutTime_GNMM" SG_ 1456 BSS_CFG_STATSts 0;
BA_ "GenSigTimeoutTime_EVCU2" SG_ 1456 BSS_CFG_STATSts 0;
BA_ "GenSigTimeoutTime_ESL" SG_ 1456 BSS_CFG_STATSts 0;
BA_ "GenSigTimeoutTime_ECM" SG_ 1456 BSS_CFG_STATSts 0;
BA_ "GenSigTimeoutTime_DTCM" SG_ 1456 BSS_CFG_STATSts 0;
BA_ "GenSigTimeoutTime_DMSM" SG_ 1456 BSS_CFG_STATSts 0;
BA_ "GenSigTimeoutTime_BSM" SG_ 1456 BSS_CFG_STATSts 0;
BA_ "GenSigTimeoutTime_BCM" SG_ 1456 BSS_CFG_STATSts 0;
BA_ "GenSigTimeoutTime_AGSM" SG_ 1456 BSS_CFG_STATSts 0;
BA_ "GenSigTimeoutTime_ADCAM" SG_ 1456 BSS_CFG_STATSts 0;
BA_ "GenSigSendType" SG_ 1456 BSS_CFG_STATSts 3;
BA_ "GenSigTimeoutTime_SGW" SG_ 1456 ACC_FailSts 0;
BA_ "GenSigTimeoutTime_RFHM" SG_ 1456 ACC_FailSts 0;
BA_ "GenSigTimeoutTime_MPAD" SG_ 1456 ACC_FailSts 0;
BA_ "GenSigTimeoutTime_GNMM" SG_ 1456 ACC_FailSts 0;
BA_ "GenSigTimeoutTime_EVCU2" SG_ 1456 ACC_FailSts 0;
BA_ "GenSigTimeoutTime_ESL" SG_ 1456 ACC_FailSts 0;
BA_ "GenSigTimeoutTime_ECM" SG_ 1456 ACC_FailSts 0;
BA_ "GenSigTimeoutTime_DTCM" SG_ 1456 ACC_FailSts 0;
BA_ "GenSigTimeoutTime_DMSM" SG_ 1456 ACC_FailSts 0;
BA_ "GenSigTimeoutTime_AGSM" SG_ 1456 ACC_FailSts 0;
BA_ "GenSigTimeoutTime_ADCAM" SG_ 1456 ACC_FailSts 0;
BA_ "GenSigSendType" SG_ 1456 ACC_FailSts 3;
BA_ "GenSigTimeoutTime_RFHM" SG_ 1456 ACC_DispPopupSts 0;
BA_ "GenSigTimeoutTime_MPAD" SG_ 1456 ACC_DispPopupSts 0;
BA_ "GenSigTimeoutTime_GNMM" SG_ 1456 ACC_DispPopupSts 0;
BA_ "GenSigTimeoutTime_EVCU2" SG_ 1456 ACC_DispPopupSts 0;
BA_ "GenSigTimeoutTime_ESL" SG_ 1456 ACC_DispPopupSts 0;
BA_ "GenSigTimeoutTime_ECM" SG_ 1456 ACC_DispPopupSts 0;
BA_ "GenSigTimeoutTime_DTCM" SG_ 1456 ACC_DispPopupSts 0;
BA_ "GenSigTimeoutTime_DMSM" SG_ 1456 ACC_DispPopupSts 0;
BA_ "GenSigTimeoutTime_SGW" SG_ 1456 AEB_Blind 0;
BA_ "GenSigTimeoutTime_RFHM" SG_ 1456 AEB_Blind 0;
BA_ "GenSigTimeoutTime_MPAD" SG_ 1456 AEB_Blind 0;
BA_ "GenSigTimeoutTime_GNMM" SG_ 1456 AEB_Blind 0;
BA_ "GenSigTimeoutTime_EVCU2" SG_ 1456 AEB_Blind 0;
BA_ "GenSigTimeoutTime_ESL" SG_ 1456 AEB_Blind 0;
BA_ "GenSigTimeoutTime_ECM" SG_ 1456 AEB_Blind 0;
BA_ "GenSigTimeoutTime_DTCM" SG_ 1456 AEB_Blind 0;
BA_ "GenSigTimeoutTime_DMSM" SG_ 1456 AEB_Blind 0;
BA_ "GenSigTimeoutTime_BSM" SG_ 1456 AEB_Blind 0;
BA_ "GenSigTimeoutTime_BCM" SG_ 1456 AEB_Blind 0;
BA_ "GenSigTimeoutTime_AGSM" SG_ 1456 AEB_Blind 0;
BA_ "GenSigTimeoutTime_ADCAM" SG_ 1456 AEB_Blind 0;
BA_ "GenSigSendType" SG_ 1456 AEB_Blind 3;
BA_ "GenSigTimeoutTime_RFHM" SG_ 1456 ACC_Set_Speed_Strike 0;
BA_ "GenSigTimeoutTime_MPAD" SG_ 1456 ACC_Set_Speed_Strike 0;
BA_ "GenSigTimeoutTime_GNMM" SG_ 1456 ACC_Set_Speed_Strike 0;
BA_ "GenSigTimeoutTime_EVCU2" SG_ 1456 ACC_Set_Speed_Strike 0;
BA_ "GenSigTimeoutTime_ESL" SG_ 1456 ACC_Set_Speed_Strike 0;
BA_ "GenSigTimeoutTime_ECM" SG_ 1456 ACC_Set_Speed_Strike 0;
BA_ "GenSigTimeoutTime_DTCM" SG_ 1456 ACC_Set_Speed_Strike 0;
BA_ "GenSigTimeoutTime_DMSM" SG_ 1456 ACC_Set_Speed_Strike 0;
BA_ "GenSigTimeoutTime_BSM" SG_ 1456 ACC_Set_Speed_Strike 0;
BA_ "GenSigTimeoutTime_BCM" SG_ 1456 ACC_Set_Speed_Strike 0;
BA_ "GenSigTimeoutTime_AGSM" SG_ 1456 ACC_Set_Speed_Strike 0;
BA_ "GenSigTimeoutTime_ADCAM" SG_ 1456 ACC_Set_Speed_Strike 0;
BA_ "GenSigSendType" SG_ 1456 ACC_Set_Speed_Strike 3;
BA_ "GenSigTimeoutTime_SGW" SG_ 1456 ACC_Limited 0;
BA_ "GenSigTimeoutTime_RFHM" SG_ 1456 ACC_Limited 0;
BA_ "GenSigTimeoutTime_MPAD" SG_ 1456 ACC_Limited 0;
BA_ "GenSigTimeoutTime_GNMM" SG_ 1456 ACC_Limited 0;
BA_ "GenSigTimeoutTime_EVCU2" SG_ 1456 ACC_Limited 0;
BA_ "GenSigTimeoutTime_ESL" SG_ 1456 ACC_Limited 0;
BA_ "GenSigTimeoutTime_ECM" SG_ 1456 ACC_Limited 0;
BA_ "GenSigTimeoutTime_DTCM" SG_ 1456 ACC_Limited 0;
BA_ "GenSigTimeoutTime_DMSM" SG_ 1456 ACC_Limited 0;
BA_ "GenSigTimeoutTime_BSM" SG_ 1456 ACC_Limited 0;
BA_ "GenSigTimeoutTime_BCM" SG_ 1456 ACC_Limited 0;
BA_ "GenSigTimeoutTime_AGSM" SG_ 1456 ACC_Limited 0;
BA_ "GenSigTimeoutTime_ADCAM" SG_ 1456 ACC_Limited 0;
BA_ "GenSigSendType" SG_ 1456 ACC_Limited 3;
BA_ "GenSigTimeoutTime_SGW" SG_ 1456 ACC_Limit_Fail 0;
BA_ "GenSigTimeoutTime_RFHM" SG_ 1456 ACC_Limit_Fail 0;
BA_ "GenSigTimeoutTime_MPAD" SG_ 1456 ACC_Limit_Fail 0;
BA_ "GenSigTimeoutTime_GNMM" SG_ 1456 ACC_Limit_Fail 0;
BA_ "GenSigTimeoutTime_EVCU2" SG_ 1456 ACC_Limit_Fail 0;
BA_ "GenSigTimeoutTime_ESL" SG_ 1456 ACC_Limit_Fail 0;
BA_ "GenSigTimeoutTime_ECM" SG_ 1456 ACC_Limit_Fail 0;
BA_ "GenSigTimeoutTime_DTCM" SG_ 1456 ACC_Limit_Fail 0;
BA_ "GenSigTimeoutTime_DMSM" SG_ 1456 ACC_Limit_Fail 0;
BA_ "GenSigTimeoutTime_BSM" SG_ 1456 ACC_Limit_Fail 0;
BA_ "GenSigTimeoutTime_BCM" SG_ 1456 ACC_Limit_Fail 0;
BA_ "GenSigTimeoutTime_AGSM" SG_ 1456 ACC_Limit_Fail 0;
BA_ "GenSigTimeoutTime_ADCAM" SG_ 1456 ACC_Limit_Fail 0;
BA_ "GenSigSendType" SG_ 1456 ACC_Limit_Fail 3;
BA_ "GenSigTimeoutTime_BSM" SG_ 1456 ACC_DispPopupSts 0;
BA_ "GenSigTimeoutTime_BCM" SG_ 1456 ACC_DispPopupSts 0;
BA_ "GenSigTimeoutTime_AGSM" SG_ 1456 ACC_DispPopupSts 0;
BA_ "GenSigTimeoutTime_ADCAM" SG_ 1456 ACC_DispPopupSts 0;
BA_ "GenSigSendType" SG_ 1456 ACC_DispPopupSts 3;
BA_ "GenSigTimeoutTime_SGW" SG_ 1456 ACC_Blind 0;
BA_ "GenSigTimeoutTime_RFHM" SG_ 1456 ACC_Blind 0;
BA_ "GenSigTimeoutTime_MPAD" SG_ 1456 ACC_Blind 0;
BA_ "GenSigTimeoutTime_GNMM" SG_ 1456 ACC_Blind 0;
BA_ "GenSigTimeoutTime_EVCU2" SG_ 1456 ACC_Blind 0;
BA_ "GenSigTimeoutTime_ESL" SG_ 1456 ACC_Blind 0;
BA_ "GenSigTimeoutTime_ECM" SG_ 1456 ACC_Blind 0;
BA_ "GenSigTimeoutTime_DTCM" SG_ 1456 ACC_Blind 0;
BA_ "GenSigTimeoutTime_DMSM" SG_ 1456 ACC_Blind 0;
BA_ "GenSigTimeoutTime_BCM" SG_ 1456 ACC_Blind 0;
BA_ "GenSigTimeoutTime_AGSM" SG_ 1456 ACC_Blind 0;
BA_ "GenSigTimeoutTime_ADCAM" SG_ 1456 ACC_Blind 0;
BA_ "GenSigSendType" SG_ 1456 ACC_Blind 3;
BA_ "GenSigTimeoutTime_SGW" SG_ 2654486640 CBV_bit1 0;
BA_ "GenSigTimeoutTime_RFHM" SG_ 2654486640 CBV_bit1 0;
BA_ "GenSigTimeoutTime_MPAD" SG_ 2654486640 CBV_bit1 0;
BA_ "GenSigTimeoutTime_IPC" SG_ 2654486640 CBV_bit1 0;
BA_ "GenSigTimeoutTime_GNMM" SG_ 2654486640 CBV_bit1 0;
BA_ "GenSigTimeoutTime_EVCU2" SG_ 2654486640 CBV_bit1 0;
BA_ "GenSigTimeoutTime_ESL" SG_ 2654486640 CBV_bit1 0;
BA_ "GenSigTimeoutTime_ECM" SG_ 2654486640 CBV_bit1 0;
BA_ "GenSigTimeoutTime_DTCM" SG_ 2654486640 CBV_bit1 0;
BA_ "GenSigTimeoutTime_DMSM" SG_ 2654486640 CBV_bit1 0;
BA_ "GenSigTimeoutTime_BSM" SG_ 2654486640 CBV_bit1 0;
BA_ "GenSigTimeoutTime_BCM" SG_ 2654486640 CBV_bit1 0;
BA_ "GenSigTimeoutTime_AGSM" SG_ 2654486640 CBV_bit1 0;
BA_ "GenSigTimeoutTime_ADCAM" SG_ 2654486640 CBV_bit1 0;
BA_ "GenSigTimeoutTime_SGW" SG_ 2654486640 CBV_bit0_RepeatMessageRequestBit 0;
BA_ "GenSigTimeoutTime_RFHM" SG_ 2654486640 CBV_bit0_RepeatMessageRequestBit 0;
BA_ "GenSigTimeoutTime_MPAD" SG_ 2654486640 CBV_bit0_RepeatMessageRequestBit 0;
BA_ "GenSigTimeoutTime_IPC" SG_ 2654486640 CBV_bit0_RepeatMessageRequestBit 0;
BA_ "GenSigTimeoutTime_GNMM" SG_ 2654486640 CBV_bit0_RepeatMessageRequestBit 0;
BA_ "GenSigTimeoutTime_EVCU2" SG_ 2654486640 CBV_bit0_RepeatMessageRequestBit 0;
BA_ "GenSigTimeoutTime_ESL" SG_ 2654486640 CBV_bit0_RepeatMessageRequestBit 0;
BA_ "GenSigTimeoutTime_ECM" SG_ 2654486640 CBV_bit0_RepeatMessageRequestBit 0;
BA_ "GenSigTimeoutTime_DTCM" SG_ 2654486640 CBV_bit0_RepeatMessageRequestBit 0;
BA_ "GenSigTimeoutTime_DMSM" SG_ 2654486640 CBV_bit0_RepeatMessageRequestBit 0;
BA_ "GenSigTimeoutTime_BSM" SG_ 2654486640 CBV_bit0_RepeatMessageRequestBit 0;
BA_ "GenSigTimeoutTime_BCM" SG_ 2654486640 CBV_bit0_RepeatMessageRequestBit 0;
BA_ "GenSigTimeoutTime_AGSM" SG_ 2654486640 CBV_bit0_RepeatMessageRequestBit 0;
BA_ "GenSigTimeoutTime_ADCAM" SG_ 2654486640 CBV_bit0_RepeatMessageRequestBit 0;
BA_ "GenSigTimeoutTime_SGW" SG_ 2654486640 SourceNodeIdentifier 0;
BA_ "GenSigTimeoutTime_RFHM" SG_ 2654486640 SourceNodeIdentifier 0;
BA_ "GenSigTimeoutTime_MPAD" SG_ 2654486640 SourceNodeIdentifier 0;
BA_ "GenSigTimeoutTime_IPC" SG_ 2654486640 SourceNodeIdentifier 0;
BA_ "GenSigTimeoutTime_GNMM" SG_ 2654486640 SourceNodeIdentifier 0;
BA_ "GenSigTimeoutTime_EVCU2" SG_ 2654486640 SourceNodeIdentifier 0;
BA_ "GenSigTimeoutTime_ESL" SG_ 2654486640 SourceNodeIdentifier 0;
BA_ "GenSigTimeoutTime_ECM" SG_ 2654486640 SourceNodeIdentifier 0;
BA_ "GenSigTimeoutTime_DTCM" SG_ 2654486640 SourceNodeIdentifier 0;
BA_ "GenSigTimeoutTime_DMSM" SG_ 2654486640 SourceNodeIdentifier 0;
BA_ "GenSigTimeoutTime_BSM" SG_ 2654486640 SourceNodeIdentifier 0;
BA_ "GenSigTimeoutTime_BCM" SG_ 2654486640 SourceNodeIdentifier 0;
BA_ "GenSigTimeoutTime_AGSM" SG_ 2654486640 SourceNodeIdentifier 0;
BA_ "GenSigTimeoutTime_ADCAM" SG_ 2654486640 SourceNodeIdentifier 0;
BA_ "GenSigTimeoutTime_SGW" SG_ 2654486593 SourceNodeIdentifier 0;
BA_ "GenSigTimeoutTime_RFHM" SG_ 2654486593 SourceNodeIdentifier 0;
BA_ "GenSigTimeoutTime_MPAD" SG_ 2654486593 SourceNodeIdentifier 0;
BA_ "GenSigTimeoutTime_IPC" SG_ 2654486593 SourceNodeIdentifier 0;
BA_ "GenSigTimeoutTime_GNMM" SG_ 2654486593 SourceNodeIdentifier 0;
BA_ "GenSigTimeoutTime_EVCU2" SG_ 2654486593 SourceNodeIdentifier 0;
BA_ "GenSigTimeoutTime_ESL" SG_ 2654486593 SourceNodeIdentifier 0;
BA_ "GenSigTimeoutTime_ECM" SG_ 2654486593 SourceNodeIdentifier 0;
BA_ "GenSigTimeoutTime_DTCM" SG_ 2654486593 SourceNodeIdentifier 0;
BA_ "GenSigTimeoutTime_DMSM" SG_ 2654486593 SourceNodeIdentifier 0;
BA_ "GenSigTimeoutTime_BSM" SG_ 2654486593 SourceNodeIdentifier 0;
BA_ "GenSigTimeoutTime_BCM" SG_ 2654486593 SourceNodeIdentifier 0;
BA_ "GenSigTimeoutTime_AGSM" SG_ 2654486593 SourceNodeIdentifier 0;
BA_ "GenSigTimeoutTime_ADCAM" SG_ 2654486593 SourceNodeIdentifier 0;
BA_ "GenSigTimeoutTime_SGW" SG_ 2654486593 CBV_bit7 0;
BA_ "GenSigTimeoutTime_RFHM" SG_ 2654486593 CBV_bit7 0;
BA_ "GenSigTimeoutTime_MPAD" SG_ 2654486593 CBV_bit7 0;
BA_ "GenSigTimeoutTime_IPC" SG_ 2654486593 CBV_bit7 0;
BA_ "GenSigTimeoutTime_GNMM" SG_ 2654486593 CBV_bit7 0;
BA_ "GenSigTimeoutTime_EVCU2" SG_ 2654486593 CBV_bit7 0;
BA_ "GenSigTimeoutTime_ESL" SG_ 2654486593 CBV_bit7 0;
BA_ "GenSigTimeoutTime_ECM" SG_ 2654486593 CBV_bit7 0;
BA_ "GenSigTimeoutTime_DTCM" SG_ 2654486593 CBV_bit7 0;
BA_ "GenSigTimeoutTime_DMSM" SG_ 2654486593 CBV_bit7 0;
BA_ "GenSigTimeoutTime_BSM" SG_ 2654486593 CBV_bit7 0;
BA_ "GenSigTimeoutTime_BCM" SG_ 2654486593 CBV_bit7 0;
BA_ "GenSigTimeoutTime_AGSM" SG_ 2654486593 CBV_bit7 0;
BA_ "GenSigTimeoutTime_ADCAM" SG_ 2654486593 CBV_bit7 0;
BA_ "GenSigTimeoutTime_SGW" SG_ 2654486640 CBV_bit7 0;
BA_ "GenSigTimeoutTime_RFHM" SG_ 2654486640 CBV_bit7 0;
BA_ "GenSigTimeoutTime_MPAD" SG_ 2654486640 CBV_bit7 0;
BA_ "GenSigTimeoutTime_IPC" SG_ 2654486640 CBV_bit7 0;
BA_ "GenSigTimeoutTime_GNMM" SG_ 2654486640 CBV_bit7 0;
BA_ "GenSigTimeoutTime_EVCU2" SG_ 2654486640 CBV_bit7 0;
BA_ "GenSigTimeoutTime_ESL" SG_ 2654486640 CBV_bit7 0;
BA_ "GenSigTimeoutTime_ECM" SG_ 2654486640 CBV_bit7 0;
BA_ "GenSigTimeoutTime_DTCM" SG_ 2654486640 CBV_bit7 0;
BA_ "GenSigTimeoutTime_DMSM" SG_ 2654486640 CBV_bit7 0;
BA_ "GenSigTimeoutTime_BSM" SG_ 2654486640 CBV_bit7 0;
BA_ "GenSigTimeoutTime_BCM" SG_ 2654486640 CBV_bit7 0;
BA_ "GenSigTimeoutTime_AGSM" SG_ 2654486640 CBV_bit7 0;
BA_ "GenSigTimeoutTime_ADCAM" SG_ 2654486640 CBV_bit7 0;
BA_ "GenSigTimeoutTime_SGW" SG_ 2654486640 CBV_bit6_PartialNtwInfBit 0;
BA_ "GenSigTimeoutTime_RFHM" SG_ 2654486640 CBV_bit6_PartialNtwInfBit 0;
BA_ "GenSigTimeoutTime_MPAD" SG_ 2654486640 CBV_bit6_PartialNtwInfBit 0;
BA_ "GenSigTimeoutTime_IPC" SG_ 2654486640 CBV_bit6_PartialNtwInfBit 0;
BA_ "GenSigTimeoutTime_GNMM" SG_ 2654486640 CBV_bit6_PartialNtwInfBit 0;
BA_ "GenSigTimeoutTime_EVCU2" SG_ 2654486640 CBV_bit6_PartialNtwInfBit 0;
BA_ "GenSigTimeoutTime_ESL" SG_ 2654486640 CBV_bit6_PartialNtwInfBit 0;
BA_ "GenSigTimeoutTime_ECM" SG_ 2654486640 CBV_bit6_PartialNtwInfBit 0;
BA_ "GenSigTimeoutTime_DTCM" SG_ 2654486640 CBV_bit6_PartialNtwInfBit 0;
BA_ "GenSigTimeoutTime_DMSM" SG_ 2654486640 CBV_bit6_PartialNtwInfBit 0;
BA_ "GenSigTimeoutTime_BSM" SG_ 2654486640 CBV_bit6_PartialNtwInfBit 0;
BA_ "GenSigTimeoutTime_BCM" SG_ 2654486640 CBV_bit6_PartialNtwInfBit 0;
BA_ "GenSigTimeoutTime_AGSM" SG_ 2654486640 CBV_bit6_PartialNtwInfBit 0;
BA_ "GenSigTimeoutTime_ADCAM" SG_ 2654486640 CBV_bit6_PartialNtwInfBit 0;
BA_ "GenSigTimeoutTime_SGW" SG_ 2654486593 CBV_bit6_PartialNtwInfBit 0;
BA_ "GenSigTimeoutTime_RFHM" SG_ 2654486593 CBV_bit6_PartialNtwInfBit 0;
BA_ "GenSigTimeoutTime_MPAD" SG_ 2654486593 CBV_bit6_PartialNtwInfBit 0;
BA_ "GenSigTimeoutTime_IPC" SG_ 2654486593 CBV_bit6_PartialNtwInfBit 0;
BA_ "GenSigTimeoutTime_GNMM" SG_ 2654486593 CBV_bit6_PartialNtwInfBit 0;
BA_ "GenSigTimeoutTime_EVCU2" SG_ 2654486593 CBV_bit6_PartialNtwInfBit 0;
BA_ "GenSigTimeoutTime_ESL" SG_ 2654486593 CBV_bit6_PartialNtwInfBit 0;
BA_ "GenSigTimeoutTime_ECM" SG_ 2654486593 CBV_bit6_PartialNtwInfBit 0;
BA_ "GenSigTimeoutTime_DTCM" SG_ 2654486593 CBV_bit6_PartialNtwInfBit 0;
BA_ "GenSigTimeoutTime_DMSM" SG_ 2654486593 CBV_bit6_PartialNtwInfBit 0;
BA_ "GenSigTimeoutTime_BSM" SG_ 2654486593 CBV_bit6_PartialNtwInfBit 0;
BA_ "GenSigTimeoutTime_BCM" SG_ 2654486593 CBV_bit6_PartialNtwInfBit 0;
BA_ "GenSigTimeoutTime_AGSM" SG_ 2654486593 CBV_bit6_PartialNtwInfBit 0;
BA_ "GenSigTimeoutTime_ADCAM" SG_ 2654486593 CBV_bit6_PartialNtwInfBit 0;
BA_ "GenSigTimeoutTime_SGW" SG_ 2654486593 CBV_bit5 0;
BA_ "GenSigTimeoutTime_RFHM" SG_ 2654486593 CBV_bit5 0;
BA_ "GenSigTimeoutTime_MPAD" SG_ 2654486593 CBV_bit5 0;
BA_ "GenSigTimeoutTime_IPC" SG_ 2654486593 CBV_bit5 0;
BA_ "GenSigTimeoutTime_GNMM" SG_ 2654486593 CBV_bit5 0;
BA_ "GenSigTimeoutTime_EVCU2" SG_ 2654486593 CBV_bit5 0;
BA_ "GenSigTimeoutTime_ESL" SG_ 2654486593 CBV_bit5 0;
BA_ "GenSigTimeoutTime_ECM" SG_ 2654486593 CBV_bit5 0;
BA_ "GenSigTimeoutTime_DTCM" SG_ 2654486593 CBV_bit5 0;
BA_ "GenSigTimeoutTime_DMSM" SG_ 2654486593 CBV_bit5 0;
BA_ "GenSigTimeoutTime_BSM" SG_ 2654486593 CBV_bit5 0;
BA_ "GenSigTimeoutTime_BCM" SG_ 2654486593 CBV_bit5 0;
BA_ "GenSigTimeoutTime_AGSM" SG_ 2654486593 CBV_bit5 0;
BA_ "GenSigTimeoutTime_ADCAM" SG_ 2654486593 CBV_bit5 0;
BA_ "GenSigTimeoutTime_SGW" SG_ 2654486640 CBV_bit5 0;
BA_ "GenSigTimeoutTime_RFHM" SG_ 2654486640 CBV_bit5 0;
BA_ "GenSigTimeoutTime_MPAD" SG_ 2654486640 CBV_bit5 0;
BA_ "GenSigTimeoutTime_IPC" SG_ 2654486640 CBV_bit5 0;
BA_ "GenSigTimeoutTime_GNMM" SG_ 2654486640 CBV_bit5 0;
BA_ "GenSigTimeoutTime_EVCU2" SG_ 2654486640 CBV_bit5 0;
BA_ "GenSigTimeoutTime_ESL" SG_ 2654486640 CBV_bit5 0;
BA_ "GenSigTimeoutTime_ECM" SG_ 2654486640 CBV_bit5 0;
BA_ "GenSigTimeoutTime_DTCM" SG_ 2654486640 CBV_bit5 0;
BA_ "GenSigTimeoutTime_DMSM" SG_ 2654486640 CBV_bit5 0;
BA_ "GenSigTimeoutTime_BSM" SG_ 2654486640 CBV_bit5 0;
BA_ "GenSigTimeoutTime_BCM" SG_ 2654486640 CBV_bit5 0;
BA_ "GenSigTimeoutTime_AGSM" SG_ 2654486640 CBV_bit5 0;
BA_ "GenSigTimeoutTime_ADCAM" SG_ 2654486640 CBV_bit5 0;
BA_ "GenSigTimeoutTime_SGW" SG_ 2654486640 CBV_bit4_ActiveWakeupBit 0;
BA_ "GenSigTimeoutTime_RFHM" SG_ 2654486640 CBV_bit4_ActiveWakeupBit 0;
BA_ "GenSigTimeoutTime_MPAD" SG_ 2654486640 CBV_bit4_ActiveWakeupBit 0;
BA_ "GenSigTimeoutTime_IPC" SG_ 2654486640 CBV_bit4_ActiveWakeupBit 0;
BA_ "GenSigTimeoutTime_GNMM" SG_ 2654486640 CBV_bit4_ActiveWakeupBit 0;
BA_ "GenSigTimeoutTime_EVCU2" SG_ 2654486640 CBV_bit4_ActiveWakeupBit 0;
BA_ "GenSigTimeoutTime_ESL" SG_ 2654486640 CBV_bit4_ActiveWakeupBit 0;
BA_ "GenSigTimeoutTime_ECM" SG_ 2654486640 CBV_bit4_ActiveWakeupBit 0;
BA_ "GenSigTimeoutTime_DTCM" SG_ 2654486640 CBV_bit4_ActiveWakeupBit 0;
BA_ "GenSigTimeoutTime_DMSM" SG_ 2654486640 CBV_bit4_ActiveWakeupBit 0;
BA_ "GenSigTimeoutTime_BSM" SG_ 2654486640 CBV_bit4_ActiveWakeupBit 0;
BA_ "GenSigTimeoutTime_BCM" SG_ 2654486640 CBV_bit4_ActiveWakeupBit 0;
BA_ "GenSigTimeoutTime_AGSM" SG_ 2654486640 CBV_bit4_ActiveWakeupBit 0;
BA_ "GenSigTimeoutTime_ADCAM" SG_ 2654486640 CBV_bit4_ActiveWakeupBit 0;
BA_ "GenSigTimeoutTime_RFHM" SG_ 2654486593 CBV_bit4_ActiveWakeupBit 0;
BA_ "GenSigTimeoutTime_MPAD" SG_ 2654486593 CBV_bit4_ActiveWakeupBit 0;
BA_ "GenSigTimeoutTime_IPC" SG_ 2654486593 CBV_bit4_ActiveWakeupBit 0;
BA_ "GenSigTimeoutTime_GNMM" SG_ 2654486593 CBV_bit4_ActiveWakeupBit 0;
BA_ "GenSigTimeoutTime_EVCU2" SG_ 2654486593 CBV_bit4_ActiveWakeupBit 0;
BA_ "GenSigTimeoutTime_ESL" SG_ 2654486593 CBV_bit4_ActiveWakeupBit 0;
BA_ "GenSigTimeoutTime_ECM" SG_ 2654486593 CBV_bit4_ActiveWakeupBit 0;
BA_ "GenSigTimeoutTime_DTCM" SG_ 2654486593 CBV_bit4_ActiveWakeupBit 0;
BA_ "GenSigTimeoutTime_DMSM" SG_ 2654486593 CBV_bit4_ActiveWakeupBit 0;
BA_ "GenSigTimeoutTime_BSM" SG_ 2654486593 CBV_bit4_ActiveWakeupBit 0;
BA_ "GenSigTimeoutTime_BCM" SG_ 2654486593 CBV_bit4_ActiveWakeupBit 0;
BA_ "GenSigTimeoutTime_AGSM" SG_ 2654486593 CBV_bit4_ActiveWakeupBit 0;
BA_ "GenSigTimeoutTime_ADCAM" SG_ 2654486593 CBV_bit4_ActiveWakeupBit 0;
BA_ "GenSigTimeoutTime_SGW" SG_ 2654486593 CBV_bit4_ActiveWakeupBit 0;
BA_ "GenSigTimeoutTime_SGW" SG_ 2654486593 CBV_bit3_NMCoordinatorBit 0;
BA_ "GenSigTimeoutTime_RFHM" SG_ 2654486593 CBV_bit3_NMCoordinatorBit 0;
BA_ "GenSigTimeoutTime_MPAD" SG_ 2654486593 CBV_bit3_NMCoordinatorBit 0;
BA_ "GenSigTimeoutTime_IPC" SG_ 2654486593 CBV_bit3_NMCoordinatorBit 0;
BA_ "GenSigTimeoutTime_GNMM" SG_ 2654486593 CBV_bit3_NMCoordinatorBit 0;
BA_ "GenSigTimeoutTime_EVCU2" SG_ 2654486593 CBV_bit3_NMCoordinatorBit 0;
BA_ "GenSigTimeoutTime_ESL" SG_ 2654486593 CBV_bit3_NMCoordinatorBit 0;
BA_ "GenSigTimeoutTime_ECM" SG_ 2654486593 CBV_bit3_NMCoordinatorBit 0;
BA_ "GenSigTimeoutTime_DTCM" SG_ 2654486593 CBV_bit3_NMCoordinatorBit 0;
BA_ "GenSigTimeoutTime_DMSM" SG_ 2654486593 CBV_bit3_NMCoordinatorBit 0;
BA_ "GenSigTimeoutTime_BSM" SG_ 2654486593 CBV_bit3_NMCoordinatorBit 0;
BA_ "GenSigTimeoutTime_BCM" SG_ 2654486593 CBV_bit3_NMCoordinatorBit 0;
BA_ "GenSigTimeoutTime_AGSM" SG_ 2654486593 CBV_bit3_NMCoordinatorBit 0;
BA_ "GenSigTimeoutTime_ADCAM" SG_ 2654486593 CBV_bit3_NMCoordinatorBit 0;
BA_ "GenSigTimeoutTime_SGW" SG_ 2654486640 CBV_bit3_NMCoordinatorBit 0;
BA_ "GenSigTimeoutTime_RFHM" SG_ 2654486640 CBV_bit3_NMCoordinatorBit 0;
BA_ "GenSigTimeoutTime_MPAD" SG_ 2654486640 CBV_bit3_NMCoordinatorBit 0;
BA_ "GenSigTimeoutTime_IPC" SG_ 2654486640 CBV_bit3_NMCoordinatorBit 0;
BA_ "GenSigTimeoutTime_GNMM" SG_ 2654486640 CBV_bit3_NMCoordinatorBit 0;
BA_ "GenSigTimeoutTime_EVCU2" SG_ 2654486640 CBV_bit3_NMCoordinatorBit 0;
BA_ "GenSigTimeoutTime_ESL" SG_ 2654486640 CBV_bit3_NMCoordinatorBit 0;
BA_ "GenSigTimeoutTime_ECM" SG_ 2654486640 CBV_bit3_NMCoordinatorBit 0;
BA_ "GenSigTimeoutTime_DTCM" SG_ 2654486640 CBV_bit3_NMCoordinatorBit 0;
BA_ "GenSigTimeoutTime_DMSM" SG_ 2654486640 CBV_bit3_NMCoordinatorBit 0;
BA_ "GenSigTimeoutTime_BSM" SG_ 2654486640 CBV_bit3_NMCoordinatorBit 0;
BA_ "GenSigTimeoutTime_BCM" SG_ 2654486640 CBV_bit3_NMCoordinatorBit 0;
BA_ "GenSigTimeoutTime_AGSM" SG_ 2654486640 CBV_bit3_NMCoordinatorBit 0;
BA_ "GenSigTimeoutTime_ADCAM" SG_ 2654486640 CBV_bit3_NMCoordinatorBit 0;
BA_ "GenSigTimeoutTime_SGW" SG_ 2654486640 CBV_bit2 0;
BA_ "GenSigTimeoutTime_RFHM" SG_ 2654486640 CBV_bit2 0;
BA_ "GenSigTimeoutTime_MPAD" SG_ 2654486640 CBV_bit2 0;
BA_ "GenSigTimeoutTime_IPC" SG_ 2654486640 CBV_bit2 0;
BA_ "GenSigTimeoutTime_GNMM" SG_ 2654486640 CBV_bit2 0;
BA_ "GenSigTimeoutTime_EVCU2" SG_ 2654486640 CBV_bit2 0;
BA_ "GenSigTimeoutTime_ESL" SG_ 2654486640 CBV_bit2 0;
BA_ "GenSigTimeoutTime_ECM" SG_ 2654486640 CBV_bit2 0;
BA_ "GenSigTimeoutTime_DTCM" SG_ 2654486640 CBV_bit2 0;
BA_ "GenSigTimeoutTime_DMSM" SG_ 2654486640 CBV_bit2 0;
BA_ "GenSigTimeoutTime_BSM" SG_ 2654486640 CBV_bit2 0;
BA_ "GenSigTimeoutTime_BCM" SG_ 2654486640 CBV_bit2 0;
BA_ "GenSigTimeoutTime_AGSM" SG_ 2654486640 CBV_bit2 0;
BA_ "GenSigTimeoutTime_ADCAM" SG_ 2654486640 CBV_bit2 0;
BA_ "GenSigTimeoutTime_SGW" SG_ 2654486593 CBV_bit2 0;
BA_ "GenSigTimeoutTime_RFHM" SG_ 2654486593 CBV_bit2 0;
BA_ "GenSigTimeoutTime_MPAD" SG_ 2654486593 CBV_bit2 0;
BA_ "GenSigTimeoutTime_IPC" SG_ 2654486593 CBV_bit2 0;
BA_ "GenSigTimeoutTime_GNMM" SG_ 2654486593 CBV_bit2 0;
BA_ "GenSigTimeoutTime_EVCU2" SG_ 2654486593 CBV_bit2 0;
BA_ "GenSigTimeoutTime_ESL" SG_ 2654486593 CBV_bit2 0;
BA_ "GenSigTimeoutTime_ECM" SG_ 2654486593 CBV_bit2 0;
BA_ "GenSigTimeoutTime_DTCM" SG_ 2654486593 CBV_bit2 0;
BA_ "GenSigTimeoutTime_DMSM" SG_ 2654486593 CBV_bit2 0;
BA_ "GenSigTimeoutTime_BSM" SG_ 2654486593 CBV_bit2 0;
BA_ "GenSigTimeoutTime_BCM" SG_ 2654486593 CBV_bit2 0;
BA_ "GenSigTimeoutTime_AGSM" SG_ 2654486593 CBV_bit2 0;
BA_ "GenSigTimeoutTime_ADCAM" SG_ 2654486593 CBV_bit2 0;
BA_ "GenSigTimeoutTime_SGW" SG_ 2654486531 CBV_bit3_NMCoordinatorBit 0;
BA_ "GenSigTimeoutTime_RFHM" SG_ 2654486531 CBV_bit3_NMCoordinatorBit 0;
BA_ "GenSigTimeoutTime_MPAD" SG_ 2654486531 CBV_bit3_NMCoordinatorBit 0;
BA_ "GenSigTimeoutTime_IPC" SG_ 2654486531 CBV_bit3_NMCoordinatorBit 0;
BA_ "GenSigTimeoutTime_GNMM" SG_ 2654486531 CBV_bit3_NMCoordinatorBit 0;
BA_ "GenSigTimeoutTime_EVCU2" SG_ 2654486531 CBV_bit3_NMCoordinatorBit 0;
BA_ "GenSigTimeoutTime_ESL" SG_ 2654486531 CBV_bit3_NMCoordinatorBit 0;
BA_ "GenSigTimeoutTime_ECM" SG_ 2654486531 CBV_bit3_NMCoordinatorBit 0;
BA_ "GenSigTimeoutTime_DTCM" SG_ 2654486531 CBV_bit3_NMCoordinatorBit 0;
BA_ "GenSigTimeoutTime_DMSM" SG_ 2654486531 CBV_bit3_NMCoordinatorBit 0;
BA_ "GenSigTimeoutTime_BSM" SG_ 2654486531 CBV_bit3_NMCoordinatorBit 0;
BA_ "GenSigTimeoutTime_BCM" SG_ 2654486531 CBV_bit3_NMCoordinatorBit 0;
BA_ "GenSigTimeoutTime_AGSM" SG_ 2654486531 CBV_bit3_NMCoordinatorBit 0;
BA_ "GenSigTimeoutTime_ADCAM" SG_ 2654486531 CBV_bit3_NMCoordinatorBit 0;
BA_ "GenSigTimeoutTime_SGW" SG_ 2654486531 CBV_bit4_ActiveWakeupBit 0;
BA_ "GenSigTimeoutTime_RFHM" SG_ 2654486531 CBV_bit4_ActiveWakeupBit 0;
BA_ "GenSigTimeoutTime_MPAD" SG_ 2654486531 CBV_bit4_ActiveWakeupBit 0;
BA_ "GenSigTimeoutTime_IPC" SG_ 2654486531 CBV_bit4_ActiveWakeupBit 0;
BA_ "GenSigTimeoutTime_GNMM" SG_ 2654486531 CBV_bit4_ActiveWakeupBit 0;
BA_ "GenSigTimeoutTime_EVCU2" SG_ 2654486531 CBV_bit4_ActiveWakeupBit 0;
BA_ "GenSigTimeoutTime_ESL" SG_ 2654486531 CBV_bit4_ActiveWakeupBit 0;
BA_ "GenSigTimeoutTime_ECM" SG_ 2654486531 CBV_bit4_ActiveWakeupBit 0;
BA_ "GenSigTimeoutTime_DTCM" SG_ 2654486531 CBV_bit4_ActiveWakeupBit 0;
BA_ "GenSigTimeoutTime_DMSM" SG_ 2654486531 CBV_bit4_ActiveWakeupBit 0;
BA_ "GenSigTimeoutTime_BSM" SG_ 2654486531 CBV_bit4_ActiveWakeupBit 0;
BA_ "GenSigTimeoutTime_BCM" SG_ 2654486531 CBV_bit4_ActiveWakeupBit 0;
BA_ "GenSigTimeoutTime_AGSM" SG_ 2654486531 CBV_bit4_ActiveWakeupBit 0;
BA_ "GenSigTimeoutTime_ADCAM" SG_ 2654486531 CBV_bit4_ActiveWakeupBit 0;
BA_ "GenSigTimeoutTime_DTCM" SG_ 2654486531 CBV_bit5 0;
BA_ "GenSigTimeoutTime_DMSM" SG_ 2654486531 CBV_bit5 0;
BA_ "GenSigTimeoutTime_BSM" SG_ 2654486531 CBV_bit5 0;
BA_ "GenSigTimeoutTime_BCM" SG_ 2654486531 CBV_bit5 0;
BA_ "GenSigTimeoutTime_AGSM" SG_ 2654486531 CBV_bit5 0;
BA_ "GenSigTimeoutTime_ADCAM" SG_ 2654486531 CBV_bit5 0;
BA_ "GenSigTimeoutTime_SGW" SG_ 2654486531 CBV_bit5 0;
BA_ "GenSigTimeoutTime_RFHM" SG_ 2654486531 CBV_bit5 0;
BA_ "GenSigTimeoutTime_MPAD" SG_ 2654486531 CBV_bit5 0;
BA_ "GenSigTimeoutTime_IPC" SG_ 2654486531 CBV_bit5 0;
BA_ "GenSigTimeoutTime_GNMM" SG_ 2654486531 CBV_bit5 0;
BA_ "GenSigTimeoutTime_EVCU2" SG_ 2654486531 CBV_bit5 0;
BA_ "GenSigTimeoutTime_ESL" SG_ 2654486531 CBV_bit5 0;
BA_ "GenSigTimeoutTime_ECM" SG_ 2654486531 CBV_bit5 0;
BA_ "GenSigTimeoutTime_SGW" SG_ 2654486531 CBV_bit6_PartialNtwInfBit 0;
BA_ "GenSigTimeoutTime_RFHM" SG_ 2654486531 CBV_bit6_PartialNtwInfBit 0;
BA_ "GenSigTimeoutTime_MPAD" SG_ 2654486531 CBV_bit6_PartialNtwInfBit 0;
BA_ "GenSigTimeoutTime_IPC" SG_ 2654486531 CBV_bit6_PartialNtwInfBit 0;
BA_ "GenSigTimeoutTime_GNMM" SG_ 2654486531 CBV_bit6_PartialNtwInfBit 0;
BA_ "GenSigTimeoutTime_EVCU2" SG_ 2654486531 CBV_bit6_PartialNtwInfBit 0;
BA_ "GenSigTimeoutTime_ESL" SG_ 2654486531 CBV_bit6_PartialNtwInfBit 0;
BA_ "GenSigTimeoutTime_ECM" SG_ 2654486531 CBV_bit6_PartialNtwInfBit 0;
BA_ "GenSigTimeoutTime_DTCM" SG_ 2654486531 CBV_bit6_PartialNtwInfBit 0;
BA_ "GenSigTimeoutTime_DMSM" SG_ 2654486531 CBV_bit6_PartialNtwInfBit 0;
BA_ "GenSigTimeoutTime_BSM" SG_ 2654486531 CBV_bit6_PartialNtwInfBit 0;
BA_ "GenSigTimeoutTime_BCM" SG_ 2654486531 CBV_bit6_PartialNtwInfBit 0;
BA_ "GenSigTimeoutTime_AGSM" SG_ 2654486531 CBV_bit6_PartialNtwInfBit 0;
BA_ "GenSigTimeoutTime_ADCAM" SG_ 2654486531 CBV_bit6_PartialNtwInfBit 0;
BA_ "GenSigTimeoutTime_SGW" SG_ 2654486531 SourceNodeIdentifier 0;
BA_ "GenSigTimeoutTime_RFHM" SG_ 2654486531 SourceNodeIdentifier 0;
BA_ "GenSigTimeoutTime_MPAD" SG_ 2654486531 SourceNodeIdentifier 0;
BA_ "GenSigTimeoutTime_IPC" SG_ 2654486531 SourceNodeIdentifier 0;
BA_ "GenSigTimeoutTime_GNMM" SG_ 2654486531 SourceNodeIdentifier 0;
BA_ "GenSigTimeoutTime_EVCU2" SG_ 2654486531 SourceNodeIdentifier 0;
BA_ "GenSigTimeoutTime_ESL" SG_ 2654486531 SourceNodeIdentifier 0;
BA_ "GenSigTimeoutTime_ECM" SG_ 2654486531 SourceNodeIdentifier 0;
BA_ "GenSigTimeoutTime_DTCM" SG_ 2654486531 SourceNodeIdentifier 0;
BA_ "GenSigTimeoutTime_DMSM" SG_ 2654486531 SourceNodeIdentifier 0;
BA_ "GenSigTimeoutTime_BSM" SG_ 2654486531 SourceNodeIdentifier 0;
BA_ "GenSigTimeoutTime_BCM" SG_ 2654486531 SourceNodeIdentifier 0;
BA_ "GenSigTimeoutTime_AGSM" SG_ 2654486531 SourceNodeIdentifier 0;
BA_ "GenSigTimeoutTime_ADCAM" SG_ 2654486531 SourceNodeIdentifier 0;
BA_ "GenSigTimeoutTime_SGW" SG_ 2654486531 CBV_bit7 0;
BA_ "GenSigTimeoutTime_RFHM" SG_ 2654486531 CBV_bit7 0;
BA_ "GenSigTimeoutTime_MPAD" SG_ 2654486531 CBV_bit7 0;
BA_ "GenSigTimeoutTime_IPC" SG_ 2654486531 CBV_bit7 0;
BA_ "GenSigTimeoutTime_GNMM" SG_ 2654486531 CBV_bit7 0;
BA_ "GenSigTimeoutTime_EVCU2" SG_ 2654486531 CBV_bit7 0;
BA_ "GenSigTimeoutTime_ESL" SG_ 2654486531 CBV_bit7 0;
BA_ "GenSigTimeoutTime_ECM" SG_ 2654486531 CBV_bit7 0;
BA_ "GenSigTimeoutTime_DTCM" SG_ 2654486531 CBV_bit7 0;
BA_ "GenSigTimeoutTime_DMSM" SG_ 2654486531 CBV_bit7 0;
BA_ "GenSigTimeoutTime_BSM" SG_ 2654486531 CBV_bit7 0;
BA_ "GenSigTimeoutTime_BCM" SG_ 2654486531 CBV_bit7 0;
BA_ "GenSigTimeoutTime_AGSM" SG_ 2654486531 CBV_bit7 0;
BA_ "GenSigTimeoutTime_ADCAM" SG_ 2654486531 CBV_bit7 0;
BA_ "GenSigTimeoutTime_SGW" SG_ 2654486593 CBV_bit1 0;
BA_ "GenSigTimeoutTime_RFHM" SG_ 2654486593 CBV_bit1 0;
BA_ "GenSigTimeoutTime_MPAD" SG_ 2654486593 CBV_bit1 0;
BA_ "GenSigTimeoutTime_IPC" SG_ 2654486593 CBV_bit1 0;
BA_ "GenSigTimeoutTime_GNMM" SG_ 2654486593 CBV_bit1 0;
BA_ "GenSigTimeoutTime_EVCU2" SG_ 2654486593 CBV_bit1 0;
BA_ "GenSigTimeoutTime_ESL" SG_ 2654486593 CBV_bit1 0;
BA_ "GenSigTimeoutTime_ECM" SG_ 2654486593 CBV_bit1 0;
BA_ "GenSigTimeoutTime_DTCM" SG_ 2654486593 CBV_bit1 0;
BA_ "GenSigTimeoutTime_DMSM" SG_ 2654486593 CBV_bit1 0;
BA_ "GenSigTimeoutTime_BSM" SG_ 2654486593 CBV_bit1 0;
BA_ "GenSigTimeoutTime_BCM" SG_ 2654486593 CBV_bit1 0;
BA_ "GenSigTimeoutTime_AGSM" SG_ 2654486593 CBV_bit1 0;
BA_ "GenSigTimeoutTime_ADCAM" SG_ 2654486593 CBV_bit1 0;
BA_ "GenSigTimeoutTime_SGW" SG_ 2654486593 CBV_bit0_RepeatMessageRequestBit 0;
BA_ "GenSigTimeoutTime_RFHM" SG_ 2654486593 CBV_bit0_RepeatMessageRequestBit 0;
BA_ "GenSigTimeoutTime_MPAD" SG_ 2654486593 CBV_bit0_RepeatMessageRequestBit 0;
BA_ "GenSigTimeoutTime_IPC" SG_ 2654486593 CBV_bit0_RepeatMessageRequestBit 0;
BA_ "GenSigTimeoutTime_GNMM" SG_ 2654486593 CBV_bit0_RepeatMessageRequestBit 0;
BA_ "GenSigTimeoutTime_EVCU2" SG_ 2654486593 CBV_bit0_RepeatMessageRequestBit 0;
BA_ "GenSigTimeoutTime_ESL" SG_ 2654486593 CBV_bit0_RepeatMessageRequestBit 0;
BA_ "GenSigTimeoutTime_ECM" SG_ 2654486593 CBV_bit0_RepeatMessageRequestBit 0;
BA_ "GenSigTimeoutTime_DTCM" SG_ 2654486593 CBV_bit0_RepeatMessageRequestBit 0;
BA_ "GenSigTimeoutTime_DMSM" SG_ 2654486593 CBV_bit0_RepeatMessageRequestBit 0;
BA_ "GenSigTimeoutTime_BSM" SG_ 2654486593 CBV_bit0_RepeatMessageRequestBit 0;
BA_ "GenSigTimeoutTime_BCM" SG_ 2654486593 CBV_bit0_RepeatMessageRequestBit 0;
BA_ "GenSigTimeoutTime_AGSM" SG_ 2654486593 CBV_bit0_RepeatMessageRequestBit 0;
BA_ "GenSigTimeoutTime_ADCAM" SG_ 2654486593 CBV_bit0_RepeatMessageRequestBit 0;
BA_ "GenSigTimeoutTime_SGW" SG_ 2654486531 CBV_bit0_RepeatMessageRequestBit 0;
BA_ "GenSigTimeoutTime_RFHM" SG_ 2654486531 CBV_bit0_RepeatMessageRequestBit 0;
BA_ "GenSigTimeoutTime_MPAD" SG_ 2654486531 CBV_bit0_RepeatMessageRequestBit 0;
BA_ "GenSigTimeoutTime_IPC" SG_ 2654486531 CBV_bit0_RepeatMessageRequestBit 0;
BA_ "GenSigTimeoutTime_GNMM" SG_ 2654486531 CBV_bit0_RepeatMessageRequestBit 0;
BA_ "GenSigTimeoutTime_EVCU2" SG_ 2654486531 CBV_bit0_RepeatMessageRequestBit 0;
BA_ "GenSigTimeoutTime_ESL" SG_ 2654486531 CBV_bit0_RepeatMessageRequestBit 0;
BA_ "GenSigTimeoutTime_ECM" SG_ 2654486531 CBV_bit0_RepeatMessageRequestBit 0;
BA_ "GenSigTimeoutTime_DTCM" SG_ 2654486531 CBV_bit0_RepeatMessageRequestBit 0;
BA_ "GenSigTimeoutTime_DMSM" SG_ 2654486531 CBV_bit0_RepeatMessageRequestBit 0;
BA_ "GenSigTimeoutTime_BSM" SG_ 2654486531 CBV_bit0_RepeatMessageRequestBit 0;
BA_ "GenSigTimeoutTime_BCM" SG_ 2654486531 CBV_bit0_RepeatMessageRequestBit 0;
BA_ "GenSigTimeoutTime_AGSM" SG_ 2654486531 CBV_bit0_RepeatMessageRequestBit 0;
BA_ "GenSigTimeoutTime_ADCAM" SG_ 2654486531 CBV_bit0_RepeatMessageRequestBit 0;
BA_ "GenSigTimeoutTime_SGW" SG_ 2654486531 CBV_bit1 0;
BA_ "GenSigTimeoutTime_RFHM" SG_ 2654486531 CBV_bit1 0;
BA_ "GenSigTimeoutTime_MPAD" SG_ 2654486531 CBV_bit1 0;
BA_ "GenSigTimeoutTime_IPC" SG_ 2654486531 CBV_bit1 0;
BA_ "GenSigTimeoutTime_GNMM" SG_ 2654486531 CBV_bit1 0;
BA_ "GenSigTimeoutTime_EVCU2" SG_ 2654486531 CBV_bit1 0;
BA_ "GenSigTimeoutTime_ESL" SG_ 2654486531 CBV_bit1 0;
BA_ "GenSigTimeoutTime_ECM" SG_ 2654486531 CBV_bit1 0;
BA_ "GenSigTimeoutTime_DTCM" SG_ 2654486531 CBV_bit1 0;
BA_ "GenSigTimeoutTime_DMSM" SG_ 2654486531 CBV_bit1 0;
BA_ "GenSigTimeoutTime_BSM" SG_ 2654486531 CBV_bit1 0;
BA_ "GenSigTimeoutTime_BCM" SG_ 2654486531 CBV_bit1 0;
BA_ "GenSigTimeoutTime_AGSM" SG_ 2654486531 CBV_bit1 0;
BA_ "GenSigTimeoutTime_ADCAM" SG_ 2654486531 CBV_bit1 0;
VAL_ 610 TSRSts 0 "Not_Active" 1 "Active" 2 "Blinded" 3 "Fault";
VAL_ 610 SignVehicleSpeedLimitConditional 0 "Sign_Not_Detected" 1 "Speed_Limit_5" 2 "Speed_Limit_10" 3 "Speed_Limit_15" 4 "Speed_Limit_20" 5 "Speed_Limit_25" 6 "Speed_Limit_30" 7 "Speed_Limit_35" 8 "Speed_Limit_40" 9 "Speed_Limit_45" 10 "Speed_Limit_50" 11 "Speed_Limit_55" 12 "Speed_Limit_60" 13 "Speed_Limit_65" 14 "Speed_Limit_70" 15 "Speed_Limit_75" 16 "Speed_Limit_80" 17 "Speed_Limit_85" 18 "Speed_Limit_90" 19 "Speed_Limit_95" 20 "Speed_Limit_100" 21 "Speed_Limit_105" 22 "Speed_Limit_110" 23 "Speed_Limit_115" 24 "Speed_Limit_120" 25 "Speed_Limit_125" 26 "Speed_Limit_130" 27 "Speed_Limit_135" 28 "Speed_Limit_140" 29 "Speed_Limit_145" 62 "Speed_Limit_Unlimited" 63 "End_Speed_Limit";
VAL_ 610 SignVehicleSpeedLimit 0 "Sign_Not_Detected" 1 "Speed_Limit_5" 2 "Speed_Limit_10" 3 "Speed_Limit_15" 4 "Speed_Limit_20" 5 "Speed_Limit_25" 6 "Speed_Limit_30" 7 "Speed_Limit_35" 8 "Speed_Limit_40" 9 "Speed_Limit_45" 10 "Speed_Limit_50" 11 "Speed_Limit_55" 12 "Speed_Limit_60" 13 "Speed_Limit_65" 14 "Speed_Limit_70" 15 "Speed_Limit_75" 16 "Speed_Limit_80" 17 "Speed_Limit_85" 18 "Speed_Limit_90" 19 "Speed_Limit_95" 20 "Speed_Limit_100" 21 "Speed_Limit_105" 22 "Speed_Limit_110" 23 "Speed_Limit_115" 24 "Speed_Limit_120" 25 "Speed_Limit_125" 26 "Speed_Limit_130" 27 "Speed_Limit_135" 28 "Speed_Limit_140" 29 "Speed_Limit_145" 62 "Speed_Limit_Unlimited" 63 "End_Speed_Limit";
VAL_ 610 SignSupplemVehicleSpeedLimit 0 "Sign_Not_Detected" 1 "Generic_Sign" 2 "Fog" 3 "Rain" 4 "Snow" 5 "Trailer" 6 "Time" 7 "Right_Arrow" 8 "Left_Arrow" 9 "School_Zone" 10 "Work_Zone" 11 "Night" 15 "End_Limit";
VAL_ 610 SignOvertaking 0 "Sign_Not_Detected" 1 "Overtaking" 2 "No_Overtaking";
VAL_ 610 AHBFault 0 "OFF" 1 "ON";
VAL_ 610 AHB_ON 0 "OFF" 1 "ON";
VAL_ 610 AHB_Blind 0 "OFF" 1 "ON";
VAL_ 1456 RR_Chime_RqSts 0 "No_rght_rear_chime_on_req" 1 "Right_rear_chime_on_req";
VAL_ 1456 LR_Chime_RqSts 0 "No_left_rear_chime_on_req" 1 "Left_rear_chime_on_req";
VAL_ 1456 Chime_Priority 0 "A" 1 "B" 2 "C" 3 "D" 4 "E";
VAL_ 1456 BSS_SRV_RQSts 0 "No_Service_Request" 1 "Service_Request";
VAL_ 1456 BSS_Blind_RQSts 0 "No_Sensor_Blocked_Request" 1 "Sensor_Blocked_Request";
VAL_ 1456 BSS_CFG_STATSts 0 "Not_enabled" 1 "Enabled_for_LED" 2 "Enabled_for_LED_and_Chime" 3 "SNA";
VAL_ 1452 U_Call_Stat_TBM 0 "Off" 1 "Red_Solid" 2 "Red_Blink" 3 "Green_Blink_Fast" 4 "Green_Blink_Slow" 5 "Green_Solid" 7 "SNA";
VAL_ 1452 E_Call_Stat_TBM 0 "Off" 1 "Red_Solid" 2 "Red_Blink" 3 "Green_Blink_Fast" 4 "Green_Blink_Slow" 5 "Green_Solid" 7 "SNA";
VAL_ 610 Speed_Sign_Shape 0 "Not_Detected" 1 "Shape_1_Square" 2 "Shape_2_Round" 3 "TBD";
VAL_ 610 SpdUnits_Cam 0 "km_h" 1 "mph";
VAL_ 610 SourceFusedSpeedLimit 0 "None" 1 "Camera" 2 "Map" 3 "Camera_and_Map";
VAL_ 610 HAS_ValidRoad 0 "False" 1 "True";
VAL_ 1456 SVI_Request 0 "OFF" 1 "Green" 2 "YELLOW" 3 "Red";
VAL_ 1456 Set_Speed_MPH 255 "SNA";
VAL_ 1456 Set_Speed_KPH 255 "SNA";
VAL_ 1456 RF_Chime_RqSts 0 "No_Request" 1 "Request";
VAL_ 1456 PEB_Setting_Avail 0 "Available" 1 "Not_Available";
VAL_ 1456 NCC_FailSts 0 "Fail_Not_Present" 1 "Fail_Present";
VAL_ 1456 LKA_Status 0 "OFF" 1 "ON";
VAL_ 1456 LKA_LEDControlSts 0 "OFF" 1 "CONT" 2 "BLINK" 3 "SNA";
VAL_ 1456 LKA_FailSts 0 "Fail_Not_Present" 1 "Fail_Present";
VAL_ 1456 LKA_Blind 0 "Fail_Not_Present" 1 "Fail_Present";
VAL_ 1456 LF_Chime_RqSts 0 "No_Request" 1 "Request";
VAL_ 1456 Lane_DisplaySts_Right 0 "Off" 1 "Gray" 2 "Green" 3 "Yellow" 4 "Yellow_Flashing" 5 "Red" 6 "Dashed" 7 "White";
VAL_ 1456 Lane_DisplaySts_Left 0 "Off" 1 "Gray" 2 "Green" 3 "Yellow" 4 "Yellow_Flashing" 5 "Red" 6 "Dashed" 7 "White";
VAL_ 1456 ICA_Blind 0 "Blinded" 1 "Not_Blinded";
VAL_ 1456 HAS_TurnSignalRequest 0 "No_Request" 1 "Left" 2 "Right";
VAL_ 1456 HAS_TelltaleSts 0 "OFF" 1 "GREY" 2 "GREEN" 3 "YELLOW" 4 "RED" 5 "GREEN_HANDS_FREE" 6 "YELLOW_HANDS_FREE" 7 "SNA";
VAL_ 1456 HAS_Hazard 0 "No_Request" 1 "Request";
VAL_ 1456 HAS_FailSts 0 "Fail_Not_Present" 1 "Fail_Present";
VAL_ 1456 HAS_Escalation_Sts 0 "No_State" 1 "State0" 2 "State1" 3 "State2" 4 "State3a" 5 "State3b" 6 "State4a" 7 "State4b" 8 "State5";
VAL_ 1456 HAS_Blind 0 "Fail_Not_Present" 1 "Fail_Present";
VAL_ 1456 FCW_Setting_Avail 0 "Available" 1 "Not_Available";
VAL_ 1456 DMSM_Wakeup 0 "Off" 1 "On";
VAL_ 1456 DisplaySts_Veh 0 "Off" 1 "Center_White" 2 "Center_Green" 3 "Right_Crossing_1" 4 "Left_Crossing_1" 5 "Right_Crossing_2" 6 "Left_Crossing_2";
VAL_ 1456 DisplaySts_OFF 0 "No_Code" 1 "ACC_LKA_HAS" 2 "ACC_LKA" 3 "ACC_HAS" 4 "ACC" 5 "LKA";
VAL_ 1456 DisplaySts_Curve 0 "No_Req" 1 "Left" 2 "Right";
VAL_ 1456 DisplaySts_ACC 0 "Off" 1 "Ready_TG1" 2 "Ready_TG2" 3 "Ready_TG3" 4 "Ready_TG4" 5 "ACC_E_NT_TG1" 6 "ACC_E_NT_TG2" 7 "ACC_E_NT_TG3" 8 "ACC_E_NT_TG4" 9 "ACC_E_WT_TG1" 10 "ACC_E_WT_TG2" 11 "ACC_E_WT_TG3" 12 "ACC_E_WT_TG4" 13 "NCC_Ready" 14 "NCC_Engaged";
VAL_ 1456 DDD_FailSts 0 "Fail_Not_Present" 1 "Fail_Present";
VAL_ 1456 DDD_DispPopupSts 0 "No_Code" 1 "Drowsniness_Detected" 2 "DDD_Perm_Fail" 3 "SNA";
VAL_ 1456 Chime_TypSts 0 "Default" 1 "Chime 1" 2 "Chime 2" 3 "Chime 3" 4 "Chime 4" 5 "Chime 5" 6 "Chime 6" 7 "Chime 7" 8 "Chime 8" 9 "Chime 9" 10 "Chime 10";
VAL_ 1456 BlindSpotRightWarn 0 "No_Req" 1 "Solid" 2 "Flashing";
VAL_ 1456 BlindSpotLeftWarn 0 "No_Req" 1 "Solid" 2 "Flashing";
VAL_ 1456 AEB_Limited 0 "Fail_Not_Present" 1 "Fail_Present";
VAL_ 1456 AEB_Limit_Fail 0 "Fail_Not_Present" 1 "Fail_Present";
VAL_ 1456 AEB_FailSts 0 "Fail_Not_Present" 1 "Fail_Present";
VAL_ 610 HAS_OpStat_Prim_DALM 0 "Inactive" 1 "FullService" 2 "FailOperational" 3 "FailDegraded" 4 "Emergency" 5 "No_Function";
VAL_ 610 DALM_Request 0 "No_Req" 1 "Yellow_Solid" 2 "Yellow_Runway" 3 "Red_Solid" 4 "Red_Runway" 5 "Blue_Solid" 6 "Blue_Runway" 7 "Green_Solid" 15 "SNA";
VAL_ 1456 AEB_DispPopupSts 0 "No_Code" 1 "Pre_Intervention_Warning" 4 "Braking_Complete" 5 "AEB_Unavailble_ESC_Off" 6 "AEB_Unavailble_4WD_Low" 7 "Active_Braking_Enabled" 8 "Active_Braking_Disabled" 9 "AEB_User_Disabled" 10 "AEB_Radar_Blind" 11 "Pre_Intervention_Warning_VRU_L" 12 "AEB_Fail" 13 "Pre_Intervention_Warning_VRU_R" 14 "AEB_Cam_Blind" 15 "Not_used3" 16 "AEB_LIMITED_Fail" 17 "PEB_Off" 18 "PEB_On" 19 "PEB_Radar_Blind" 20 "PEB_Fail" 21 "PEB_Cam_Blind" 22 "FCW_Limited_PEB_Off_Camera_Blinded" 23 "FCW_Limited_PEB_Off_Camera_Fail" 24 "Pre_Intervention_Warning_ICA_L" 25 "Pre_Intervention_Warning_ICA_R" 26 "AEB_Limit_Corner_Blind" 27 "AEB_Unavail_Corsa" 28 "AEB_Unavail_Off_Road" 29 "AEB_Cancel_ESC_Off" 30 "AEB_Cancel_Off_Road" 31 "AEB_Unavail_HDC" 32 "AEB_Initializing_Phase_Ongoing";
VAL_ 1456 AEB_Blind 0 "Fail_Not_Present" 1 "Fail_Present";
VAL_ 1456 ACC_Set_Speed_Strike 0 "Not_Present" 1 "Present";
VAL_ 1456 ACC_Limited 0 "Fail_Not_Present" 1 "Fail_Present";
VAL_ 1456 ACC_Limit_Fail 0 "Fail_Not_Present" 1 "Fail_Present";
VAL_ 1456 ACC_FailSts 0 "Fail_Not_Present" 1 "Fail_Present";
VAL_ 1456 ACC_DispPopupSts 0 "No_Code" 1 "ACC_Unavailable" 2 "ACC_Unavailable_4WD_Low" 3 "ACC_Unavailable_ESC_Off" 4 "ACC_Unavailable_ESC_Event" 5 "ACC_Unavailable_Brakes_Cooling" 6 "ACC_Unavailable_Below_Min_Speed" 7 "ACC_Unavailable_Above_Max_Speed" 8 "ACC_Unavailable_EPB_Active" 9 "ACC_Unavailable_Shift_D" 10 "ACC_Unavailable_Door_Open" 11 "ACC_Unavailable_Seatbelt_Unbuckled" 12 "ACC_Unavailable_Road_to_Steep" 13 "ACC_Unavailable_Wrong_Gear" 14 "ACC_Unavailable_Low_RPM" 15 "ACC_Unavailable_High_RPM" 16 "ACC_Unavailable_Clutch_Engaged" 17 "ACC_Cancel" 18 "ACC_AEB_Cancel_ESC_Off" 19 "ACC_Cancel_ESC_Off" 20 "ACC_Cancel_ESC_Event" 21 "ACC_Cancel_Brakes_Cooling" 22 "ACC_Cancel_Below_Min_Speed" 23 "ACC_Cancel_Above_Max_Speed" 24 "ACC_Cancel_EPB_Active" 25 "ACC_Cancel_Shift_D" 26 "ACC_Cancel_Door_Open" 27 "ACC_Cancel_Seatbelt_Unbuckled" 28 "ACC_Cancel_Road_to_Steep" 29 "ACC_Cancel_Wrong_gear" 30 "ACC_Cancel_Low_RPM" 31 "ACC_Cancel_High_RPM" 32 "ACC_Stop_Vehicle_Object_Detected" 33 "ACC_Warning_Clutch_Engaged" 34 "ACC_Warning_Neutral_Engaged" 35 "ACC_Off_ESC_Fault" 36 "ACC_Proximity_Warning" 37 "NCC_Unavailable" 38 "NCC_Unavailable_4WD_Low" 39 "NCC_Unavailable_ESC_Off" 40 "NCC_Unavailable_ESC_Event" 41 "NCC_Unavailable_Brakes_Cooling" 42 "NCC_Unavailable_Below_Min_Speed" 43 "NCC_Unavailable_Above_Max_Speed" 44 "NCC_Unavailable_EPB_Active" 45 "NCC_Unavailable_Shift_D" 46 "NCC_Unavailable_Wrong_Gear" 47 "NCC_Unavailable_Low_RPM" 48 "NCC_Unavailable_High_RPM" 49 "NCC_Unavailable_Clutch_Engaged" 50 "NCC_Cancel" 51 "NCC_AEB_Cancel_ESC_Off" 52 "NCC_Cancel_ESC_Off" 53 "NCC_Cancel_ESC_Event" 54 "NCC_Cancel_Brakes_Cooling" 55 "NCC_Cancel_Below_Min_Speed" 56 "NCC_Cancel_Above_Max_Speed" 57 "NCC_Cancel_EPB_Active" 58 "NCC_Cancel_Shift_D" 59 "NCC_Cancel_Wrong_Gear" 60 "NCC_Cancel_Low_RPM" 61 "NCC_Cancel_High_RPM" 62 "NCC_Warning_Clutch_Engaged" 63 "NCC_Warning_Neutral_Engaged" 64 "ACC_User_Enabled" 68 "ACC_Set" 76 "ACC_Override" 77 "ACC_User_Disabled" 78 "NCC_User_Enabled" 79 "NCC_Set" 80 "NCC_User_Disbaled" 81 "NCC_Override" 82 "Front_Radar_Sensor_Plant_Mode" 83 "ACC_AEB_LKA_Cam_Blind" 84 "ACC_AEB_Cam_Blind" 85 "ACC_LKA_Cam_Blind" 86 "ACC_Cam_Blind" 87 "ACC_AEB_LKA_LIMITED_Fail" 88 "ACC_AEB_LIMITED_Fail" 89 "ACC_LKA_LIMITED_Fail" 90 "ACC_LIMITED_Fail" 91 "ACC_AEB_Radar_Blind" 92 "ACC_Radar_Blind" 93 "ACC_AEB_LKA_Fail" 94 "ACC_AEB_Fail" 95 "ACC_LKA_Fail" 96 "ACC_Fail" 97 "NCC_AEB_LKA_Fail" 98 "NCC_AEB_Fail" 99 "NCC_LKA_Fail" 100 "NCC_Fail" 101 "Alignment_Mode" 102 "Misaligned_Radar" 103 "ACC_Unavail_Corsa" 104 "NCC_Unavail_Corsa" 105 "ACC_Unavailable_Off_Road" 106 "NCC_Unavailable_Off_Road" 107 "ACC_Resume_Reminder" 108 "ACC_Cancel_Off_Road" 109 "ACC_Unavail_HDC" 110 "NCC_Unavail_HDC" 111 "ACC_AEB_Cancel_Off_Road" 112 "Stopping_Ahead" 113 "Press_xx_Confirm_To_Pass" 114 "ACC_Unavailable_Race" 115 "Manual_Confirmation" 116 "Auto_Confirmation" 117 "RES_or_Accel_Pdl_to_Continue_Moving" 118 "Vehicle_Not_Stop_Completely" 119 "Vehicle_Unable_To_Stop_At_Traffic_Light" 120 "Be_Prepared_to_Stop_Ahead" 121 "RES_or_Accel_Pdl_to_Bypass_Upcoming_stop" 122 "Change_Lane_to_Follow_Route" 123 "Route_Lane_Guidence_Aborted" 124 "ACC_Limited" 125 "IACC_NOT_AVAILABLE_TSR_NOT_AVAILABLE" 126 "IACC_NOT_AVAIL_SPEED_TOO_HIGH" 127 "IACC_NOT_AVAIL_SPEED_TOO_LOW";
VAL_ 1456 ACC_Blind 0 "Fail_Not_Present" 1 "Fail_Present";
VAL_ 278 TRANS_ADAS_Inhibit 0 "Faulted" 1 "Available";
VAL_ 1452 PrivacyMode 0 "Not_Active" 1 "Active";
VAL_ 610 HAS_Status_DALM 0 "Disabled" 1 "Enabled" 2 "Engaged" 3 "Faulted";
VAL_ 2654486640 CBV_bit6_PartialNtwInfBit 0 "NM_PDU_contains_no_Partial_Network_request_information" 1 "NM_PDU_contains_Partial_Network_request_information";
VAL_ 2654486593 CBV_bit6_PartialNtwInfBit 0 "NM_PDU_contains_no_Partial_Network_request_information" 1 "NM_PDU_contains_Partial_Network_request_information";
VAL_ 2654486595 CBV_bit6_PartialNtwInfBit 0 "NM_PDU_contains_no_Partial_Network_request_information" 1 "NM_PDU_contains_Partial_Network_request_information";
VAL_ 2654486529 CBV_bit6_PartialNtwInfBit 0 "NM_PDU_contains_no_Partial_Network_request_information" 1 "NM_PDU_contains_Partial_Network_request_information";
VAL_ 2654486549 CBV_bit6_PartialNtwInfBit 0 "NM_PDU_contains_no_Partial_Network_request_information" 1 "NM_PDU_contains_Partial_Network_request_information";
VAL_ 2654486531 CBV_bit6_PartialNtwInfBit 0 "NM_PDU_contains_no_Partial_Network_request_information" 1 "NM_PDU_contains_Partial_Network_request_information";
VAL_ 2654486531 CBV_bit4_ActiveWakeupBit 0 "PassiveWakeup" 1 "ActiveWakeup";
VAL_ 2654486549 CBV_bit4_ActiveWakeupBit 0 "PassiveWakeup" 1 "ActiveWakeup";
VAL_ 2654486529 CBV_bit4_ActiveWakeupBit 0 "PassiveWakeup" 1 "ActiveWakeup";
VAL_ 2654486595 CBV_bit4_ActiveWakeupBit 0 "PassiveWakeup" 1 "ActiveWakeup";
VAL_ 2654486593 CBV_bit4_ActiveWakeupBit 0 "PassiveWakeup" 1 "ActiveWakeup";
VAL_ 2654486640 CBV_bit4_ActiveWakeupBit 0 "PassiveWakeup" 1 "ActiveWakeup";
VAL_ 2654486640 CBV_bit3_NMCoordinatorBit 0 "Start_of_synchronized_shutdown_is_not_requested_by_main_coordinator" 1 "Start_of_synchronized_shutdown_is_requested_by_main_coordinator";
VAL_ 2654486593 CBV_bit3_NMCoordinatorBit 0 "Start_of_synchronized_shutdown_is_not_requested_by_main_coordinator" 1 "Start_of_synchronized_shutdown_is_requested_by_main_coordinator";
VAL_ 2654486595 CBV_bit3_NMCoordinatorBit 0 "Start_of_synchronized_shutdown_is_not_requested_by_main_coordinator" 1 "Start_of_synchronized_shutdown_is_requested_by_main_coordinator";
VAL_ 2654486529 CBV_bit3_NMCoordinatorBit 0 "Start_of_synchronized_shutdown_is_not_requested_by_main_coordinator" 1 "Start_of_synchronized_shutdown_is_requested_by_main_coordinator";
VAL_ 2654486549 CBV_bit3_NMCoordinatorBit 0 "Start_of_synchronized_shutdown_is_not_requested_by_main_coordinator" 1 "Start_of_synchronized_shutdown_is_requested_by_main_coordinator";
VAL_ 2654486531 CBV_bit3_NMCoordinatorBit 0 "Start_of_synchronized_shutdown_is_not_requested_by_main_coordinator" 1 "Start_of_synchronized_shutdown_is_requested_by_main_coordinator";
VAL_ 2654486531 CBV_bit0_RepeatMessageRequestBit 0 "Repeat_Message_State_not_requested" 1 "Repeat_Message_State_requested";
VAL_ 2654486593 CBV_bit0_RepeatMessageRequestBit 0 "Repeat_Message_State_not_requested" 1 "Repeat_Message_State_requested";
VAL_ 2654486549 CBV_bit0_RepeatMessageRequestBit 0 "Repeat_Message_State_not_requested" 1 "Repeat_Message_State_requested";
VAL_ 2654486529 CBV_bit0_RepeatMessageRequestBit 0 "Repeat_Message_State_not_requested" 1 "Repeat_Message_State_requested";
VAL_ 2654486595 CBV_bit0_RepeatMessageRequestBit 0 "Repeat_Message_State_not_requested" 1 "Repeat_Message_State_requested";
VAL_ 2654486640 CBV_bit0_RepeatMessageRequestBit 0 "Repeat_Message_State_not_requested" 1 "Repeat_Message_State_requested";
VAL_ 1456 Driver_Model 0 "Attention_Unknown" 1 "Attention_Criteria_Met" 2 "Attention_Criteria_Not_Met" 3 "Faulted";
VAL_ 1456 SVI_Request_ext 0 "OFF" 1 "Green" 2 "YELLOW" 3 "Red" 4 "Blue";
VAL_ 1456 ADASDoorunlock_Request 0 "No_Request" 1 "Request";
VAL_ 610 DRV_Request 0 "None" 1 "Service_Required" 2 "Subscription_Expired" 3 "Geolocation_OFF" 4 "DRV_Not_Available";
VAL_ 1456 HAS_TelltaleSts_ext 0 "RED_HANDS_FREE" 7 "SNA";
VAL_ 1456 DisplaySts_Route 0 "Route_Roundabout" 1 "Route_Highway_Exit" 2 "Route_Grade_Intersection" 3 "Route_Trafic_Light" 4 "Route_T_Intersection";
VAL_ 610 Alg_DisplaySts 0 "Off" 1 "green_left" 2 "green_right" 3 "grey_left" 4 "grey_right" 5 "white_left" 6 "white_right" 7 "SNA";
VAL_ 1456 SLA_Telltale_Sts 0 "off" 1 "white" 2 "green" 3 "SNA";
VAL_ 1456 RRCC_LEDSts 0 "OFF" 1 "Cont" 2 "Blink" 3 "SNA";
VAL_ 610 Turn_Lever_Unlatch_Req 0 "No_Request" 1 "Unlatch_Requested" 3 "SNA";
VAL_ 1456 HAS_Inhibit_HMI 0 "No_Request" 1 "Msg_1" 2 "Msg_2" 3 "Msg_3" 4 "Msg_4" 5 "Msg_5" 6 "Msg_6" 7 "Msg_7" 8 "Msg_8" 9 "Msg_9" 10 "Msg_10" 11 "Msg_11" 12 "Msg_12" 13 "Msg_13" 14 "Msg_14" 15 "Msg_15" 16 "Msg_16" 17 "Msg_17" 18 "Msg_18" 19 "Msg_19" 20 "Msg_20" 21 "Msg_21" 22 "Msg_22" 23 "Msg_23" 24 "Msg_24" 25 "Msg_25" 26 "Msg_26" 27 "Msg_27" 28 "Msg_28" 29 "Msg_29" 30 "Msg_30" 31 "Msg_31" 32 "Msg_32" 33 "Msg_33" 34 "Msg_34" 35 "Msg_35" 36 "Msg_36" 37 "Msg_37" 38 "Msg_38" 39 "Msg_39" 40 "Msg_40" 41 "Msg_41" 42 "Msg_42" 43 "Msg_43" 44 "Msg_44" 45 "Msg_45" 46 "Msg_46" 47 "Msg_47" 48 "Msg_48" 49 "Msg_49" 50 "Msg_50" 51 "Msg_51" 52 "Msg_52" 53 "Msg_53" 54 "Msg_54" 55 "Msg_55" 56 "Msg_56" 57 "Msg_57" 58 "Msg_58" 59 "Msg_59" 60 "Msg_60" 61 "Msg_61" 62 "Msg_62" 63 "SNA";
VAL_ 1456 Lane_DispPopupSts 0 "No_Code" 1 "LKA_On" 2 "LKA_Off" 3 "LKA_Hands_Off" 4 "HAS_Eyes_Off_Yellow" 5 "Take_Control_Red" 6 "HAS_Ready_Highway" 7 "Blind_Spot_OFF" 8 "HAS_Ready_ACC_Set" 9 "HAS_Unavailable_Speed_to_High" 10 "HAS_Unavailable_Trailer" 11 "HAS_Unavailable_TempNAP" 12 "HAS_Cancel_FOW" 13 "HAS_Cancel_Lane" 15 "HAS_Cancel_Curve" 16 "Unsupport_Lane_Ahead_Take_Control" 17 "MRM_In_Prog" 18 "MRM_Complete" 19 "HAS_Unavail_Lane" 20 "HAS_Hands_Off_Yellow" 21 "HAS_Hands_Off_Red" 22 "HAS_Cancel_Hands_Off" 23 "HAS_AEB_LKA_Cam_Blind" 24 "HAS_AEB_Cam_Blind" 25 "HAS_LKA_Cam_Blind" 26 "HAS_Cam_Blind" 27 "LKA_AEB_Cam_Blind" 28 "LKA_Cam_Blind" 29 "HAS_AEB_Radar_Blind" 30 "HAS_Radar_Blind" 31 "HAS_AEB_LKA_LIMITED_Fail" 32 "HAS_AEB_LIMITED_Fail" 33 "LKA_AEB_LIMITED_Fail" 34 "HAS_AEB_LKA_Fail" 35 "HAS_AEB_Fail" 36 "HAS_LKA_Fail" 37 "HAS_Fail" 38 "LKA_AEB_Fail" 39 "LKA_Fail" 40 "HAS_Cancel" 42 "HAS_ON" 43 "HAS_OFF" 44 "BSS_Blind_ALM_On" 45 "BSS_Blind_ALM_Off" 46 "BSS_OPR_ALM_Off" 47 "BSS_OPR_ALM_On" 48 "BSS_SRV_ALM_Off" 49 "BSS_SRV_ALM_On" 50 "HAS_Unavail_Road_Data" 51 "HAS_Unavail_No_Eyes_On" 52 "HAS_Unavail_Map_OOD" 53 "HAS_Unavail_Locked_Out" 54 "HAS_Cancel_Road_Data" 55 "HAS_Cancel_Driver_Not_Attent" 56 "HAS_Cancel_Brake_Event" 57 "HAS_Cancel_Speed_Too_High" 58 "HAS_Cancel_Control_Limit" 59 "HAS_ACC_Unavailable_4WD_Low" 60 "HAS_ACC_Unavailable_ESC_Off" 61 "HAS_ACC_Unavailable_ESC_Event" 62 "HAS_ACC_Unavailable_Brakes_Cooling" 63 "HAS_ACC_Unavailable_EPB_Active" 64 "HAS_ACC_Unavailable_Shift_D" 65 "HAS_ACC_Unavailable_Door_Open" 66 "HAS_ACC_Unavailable_Seatbelt_Unbuckled" 67 "HAS_ACC_Unavailable_Road_to_Steep" 68 "HAS_ACC_Unavailable_Low_RPM" 69 "HAS_ACC_Unavailable_High_RPM" 70 "HAS_ACC_Cancel" 71 "HAS_ACC_AEB_Cancel_ESC_Off" 72 "HAS_ACC_Cancel_ESC_Off" 73 "HAS_ACC_Cancel_ESC_Event" 74 "HAS_ACC_Cancel_Brakes_Cooling" 75 "HAS_ACC_Cancel_EPB_Active" 76 "HAS_ACC_Cancel_Shift_D" 77 "HAS_ACC_Cancel_Door_Open" 78 "HAS_ACC_Cancel_Seatbelt_Unbuckled" 79 "HAS_ACC_Cancel_Road_to_Steep" 80 "HAS_ACC_Cancel_Low_RPM" 81 "HAS_ACC_Cancel_High_RPM" 82 "HAS_ACC_Stop_Vehicle_Object_Detected" 83 "HAS_ACC_User_Enabled" 84 "HAS_ACC_Set" 85 "LKA_Off_Check" 86 "HAS_Curve_Too_Tight" 87 "HAS_Lane_Split" 88 "HAS_On_Reminder" 89 "HAS_ACC_Unavail_Corsa" 90 "LKA_Unavail_Corsa" 91 "HAS_ACC_Unavailable_Off_Road" 92 "BSS_Unavail_Corsa" 93 "BSS_Trailer_On" 94 "BSS_Trailer_Max" 95 "ADAS_Unavailable_Snow_Plow_Detected" 96 "HF_ADA_Set" 97 "Ready_No_Road_HF" 98 "Adjust_Seat_State_2" 99 "Drowsy_State_2" 100 "HF_To_HO_Generic" 101 "HF_To_HO_Hwy_Ending" 102 "HF_Cancel_Not_Attentive" 103 "DA_Set_HF_Service" 104 "Stay_In_Lane" 105 "ALM_Unavail_ESC_Off" 106 "ALM_Off_ESC_Off" 107 "HAS_ACC_Unavail_HDC" 108 "HAS_ACC_AEB_Cancel_Off_Road" 109 "HAS_ACC_Cancel_Off_Road" 110 "HAS_Only_Fail" 111 "HAS_Only_ALM_Fail" 112 "MRM_Complete_Shift_P" 113 "HAS_Eyes_Off_Red" 114 "LKA_Cancel_Hands_Off" 115 "Change_Lane_To_Follow_the_Route" 116 "Route_Lane_Guidance_Aborted_Chime" 117 "Route_Lane_Guidance_Aborted_No_Chime" 118 "HAS_Unavailable_Race" 119 "EmrgCorrAssist_AvailContry" 120 "EmrgCorrAssist_UnavailContry" 121 "EmrgCorrAssist_Active?" 122 "EmrgCorrAssist_Unavail?" 123 "EmrgCorrAssist_Off" 124 "ScText_Srch_opening" 125 "ScText_SpdSlow_MnLChgReq" 126 "LnUnavail_MnLChgReq" 127 "MnLChgReq" 128 "OpNotFnd_MnLChgReq" 129 "ADA_Cancel_JuncAhead" 130 "SpeedOverMax_for_ADA" 131 "SteerReq_Junction_Ahead" 132 "No_ADA_JunctionDetected" 133 "No_ADA_VulnerableUserDet" 134 "HandsOnWheel_JuncAhead" 135 "DriNotVisPlcHndsOnStrngWhl" 136 "ADA_CANCELLED_INCOMPATIBLE_TRAILER" 137 "ADA_UNAVAIL_INCOMPATIBLE_TRAILER" 138 "ADA_ACC_Limited_NO_HandsFree";
VAL_ 1452 WiFiSts 0 "OFF" 1 "ON" 3 "SNA";
VAL_ 1452 SignalStrength 0 "0" 1 "1" 2 "2" 3 "3" 4 "4" 5 "5" 7 "SNA";
VAL_ 1452 NetConnection 0 "Not_Connected" 1 "Connected" 2 "Connection_Ongoing" 3 "Connection_Failed";
VAL_ 1452 LTESts 0 "No_Network" 1 "2G" 2 "3G" 3 "4G" 4 "E" 5 "H_Plus" 6 "Unknown" 7 "5G";
VAL_ 610 SpeedArrows 0 "NONE" 1 "UP" 2 "DOWN" 3 "NOT_RECEIVED";
VAL_ 610 SignVehicleSpeedLimitPredictive 0 "SIGNAL_NOT_DETECTED" 1 "SPEED_LIMIT_5" 2 "SPEED_LIMIT_10" 3 "SPEED_LIMIT_15" 4 "SPEED_LIMIT_20" 5 "SPEED_LIMIT_25" 6 "SPEED_LIMIT_30" 7 "SPEED_LIMIT_35" 8 "SPEED_LIMIT_40" 9 "SPEED_LIMIT_45" 10 "SPEED_LIMIT_50" 11 "SPEED_LIMIT_55" 12 "SPEED_LIMIT_60" 13 "SPEED_LIMIT_65" 14 "SPEED_LIMIT_70" 15 "SPEED_LIMIT_75" 16 "SPEED_LIMIT_80" 17 "SPEED_LIMIT_85" 18 "SPEED_LIMIT_90" 19 "SPEED_LIMIT_95" 20 "SPEED_LIMIT_100" 21 "SPEED_LIMIT_105" 22 "SPEED_LIMIT_110" 23 "SPEED_LIMIT_115" 24 "SPEED_LIMIT_120" 25 "SPEED_LIMIT_125" 26 "SPEED_LIMIT_130" 27 "SPEED_LIMIT_135" 28 "SPEED_LIMIT_140" 29 "SPEED_LIMIT_145" 30 "SPEED_LIMIT_UNLIMITED" 31 "END_SPEED_LIMIT";
VAL_ 610 MRRRR_Sts 0 "Normal" 1 "Blinded" 2 "Faulted";
VAL_ 610 MRRRL_Sts 0 "Normal" 1 "Blinded" 2 "Faulted";
VAL_ 610 MRRFR_Sts 0 "Normal" 1 "Blinded" 2 "Faulted";
VAL_ 610 MRRFL_Sts 0 "Normal" 1 "Blinded" 2 "Faulted";
VAL_ 610 LRRF_Sts 0 "Normal" 1 "Blinded" 2 "Faulted";
VAL_ 610 LRCF_Sts 0 "Normal" 1 "Blinded" 2 "Faulted";
VAL_ 1456 RRCC_DispPopupSts 0 "No_Code";
SIG_GROUP_ 610 ADAS_FD_INFO2_Pkt 1 : TSRSts SignVehicleSpeedLimitConditional SignVehicleSpeedLimit SignSupplemVehicleSpeedLimit SignOvertaking AHBFault AHB_ON AHB_Blind Speed_Sign_Shape SpdUnits_Cam SourceFusedSpeedLimit HAS_ValidRoad HAS_Status_DALM HAS_OpStat_Prim_DALM DALM_Request CADM_DALM_MC CADM_DALM_CRC Turn_Lever_Unlatch_Req SpeedArrows SignVehicleSpeedLimitPredictive MRRRR_Sts MRRRL_Sts MRRFR_Sts MRRFL_Sts LRRF_Sts LRCF_Sts DistanceSpeedLimitPredictive MessageCounter_ADAS_FD_INFO2 CRC_ADAS_FD_INFO2 DRV_Request Alg_DisplaySts;
